VERSION ""

NS_ :

BS_:

BU_: Gen AF01A

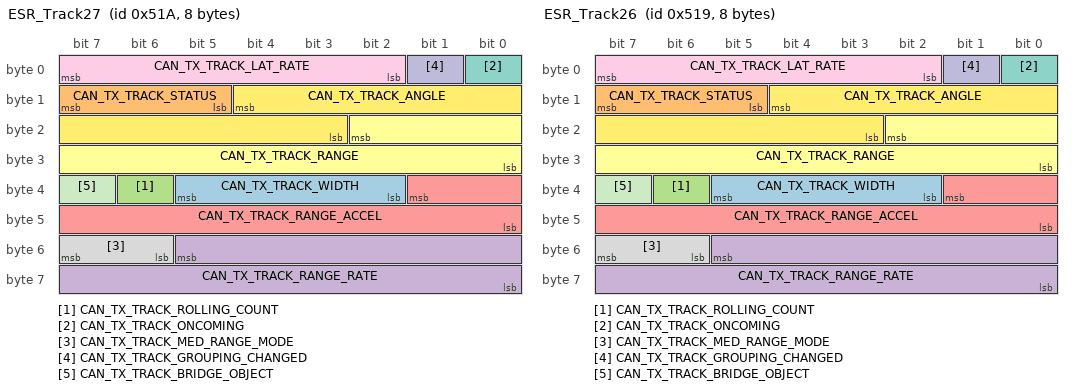
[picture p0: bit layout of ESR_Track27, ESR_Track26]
BO_ 1306 ESR_Track27: 8 Vector__XXX
 SG_ CAN_TX_TRACK_WIDTH : 37|4@0- (0.5,0) [0|7.5] "m"  AF01A
 SG_ CAN_TX_TRACK_STATUS : 15|3@0+ (1,0) [0|7] ""  AF01A
 SG_ CAN_TX_TRACK_ROLLING_COUNT : 38|1@0+ (1,0) [0|1] ""  AF01A
 SG_ CAN_TX_TRACK_RANGE_RATE : 53|14@0- (0.01,0) [-81.91|81.91] "m/s"  AF01A
 SG_ CAN_TX_TRACK_RANGE_ACCEL : 33|10@0- (0.05,0) [-25.6|25.55] "m/s/s"  AF01A
 SG_ CAN_TX_TRACK_RANGE : 18|11@0+ (0.1,0) [0|204.7] "m"  AF01A
 SG_ CAN_TX_TRACK_ONCOMING : 0|1@0+ (1,0) [0|0] ""  AF01A
 SG_ CAN_TX_TRACK_MED_RANGE_MODE : 55|2@0+ (1,0) [0|3] ""  AF01A
 SG_ CAN_TX_TRACK_LAT_RATE : 7|6@0- (0.25,0) [-8|7.75] ""  AF01A
 SG_ CAN_TX_TRACK_GROUPING_CHANGED : 1|1@0+ (1,0) [0|0] ""  AF01A
 SG_ CAN_TX_TRACK_BRIDGE_OBJECT : 39|1@0+ (1,0) [0|0] ""  AF01A
 SG_ CAN_TX_TRACK_ANGLE : 12|10@0- (0.1,0) [-51.2|51.1] "deg"  AF01A

BO_ 1305 ESR_Track26: 8 Vector__XXX
 SG_ CAN_TX_TRACK_WIDTH : 37|4@0+ (0.5,0) [0|7.5] "m"  AF01A
 SG_ CAN_TX_TRACK_STATUS : 15|3@0+ (1,0) [0|7] ""  AF01A
 SG_ CAN_TX_TRACK_ROLLING_COUNT : 38|1@0+ (1,0) [0|1] ""  AF01A
 SG_ CAN_TX_TRACK_RANGE_RATE : 53|14@0- (0.01,0) [-81.92|81.91] "m/s"  AF01A
 SG_ CAN_TX_TRACK_RANGE_ACCEL : 33|10@0- (0.05,0) [-25.6|25.55] "m/s/s"  AF01A
 SG_ CAN_TX_TRACK_RANGE : 18|11@0+ (0.1,0) [0|204.7] "m"  AF01A
 SG_ CAN_TX_TRACK_ONCOMING : 0|1@0+ (1,0) [0|0] ""  AF01A
 SG_ CAN_TX_TRACK_MED_RANGE_MODE : 55|2@0+ (1,0) [0|3] ""  AF01A
 SG_ CAN_TX_TRACK_LAT_RATE : 7|6@0- (0.25,0) [-8|7.75] ""  AF01A
 SG_ CAN_TX_TRACK_GROUPING_CHANGED : 1|1@0+ (1,0) [0|0] ""  AF01A
 SG_ CAN_TX_TRACK_BRIDGE_OBJECT : 39|1@0+ (1,0) [0|0] ""  AF01A
 SG_ CAN_TX_TRACK_ANGLE : 12|10@0- (0.1,0) [-51.2|51.1] "deg"  AF01A

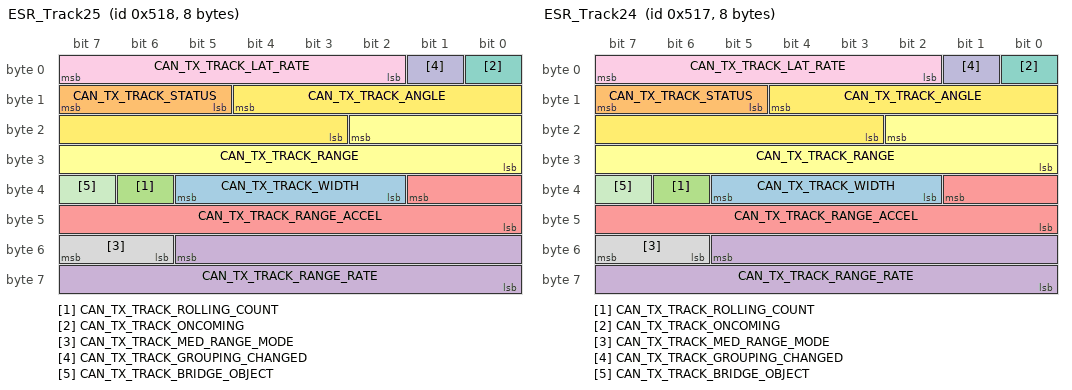
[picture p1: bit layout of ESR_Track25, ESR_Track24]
BO_ 1304 ESR_Track25: 8 Vector__XXX
 SG_ CAN_TX_TRACK_WIDTH : 37|4@0+ (0.5,0) [0|7.5] "m"  AF01A
 SG_ CAN_TX_TRACK_STATUS : 15|3@0+ (1,0) [0|7] ""  AF01A
 SG_ CAN_TX_TRACK_ROLLING_COUNT : 38|1@0+ (1,0) [0|1] ""  AF01A
 SG_ CAN_TX_TRACK_RANGE_RATE : 53|14@0- (0.01,0) [-81.92|81.91] "m/s"  AF01A
 SG_ CAN_TX_TRACK_RANGE_ACCEL : 33|10@0- (0.05,0) [-25.6|25.55] "m/s/s"  AF01A
 SG_ CAN_TX_TRACK_RANGE : 18|11@0+ (0.1,0) [0|204.7] "m"  AF01A
 SG_ CAN_TX_TRACK_ONCOMING : 0|1@0+ (1,0) [0|0] ""  AF01A
 SG_ CAN_TX_TRACK_MED_RANGE_MODE : 55|2@0+ (1,0) [0|3] ""  AF01A
 SG_ CAN_TX_TRACK_LAT_RATE : 7|6@0- (0.25,0) [-8|7.75] ""  AF01A
 SG_ CAN_TX_TRACK_GROUPING_CHANGED : 1|1@0+ (1,0) [0|0] ""  AF01A
 SG_ CAN_TX_TRACK_BRIDGE_OBJECT : 39|1@0+ (1,0) [0|0] ""  AF01A
 SG_ CAN_TX_TRACK_ANGLE : 12|10@0- (0.1,0) [-51.2|51.1] "deg"  AF01A

BO_ 1303 ESR_Track24: 8 Vector__XXX
 SG_ CAN_TX_TRACK_WIDTH : 37|4@0+ (0.5,0) [0|7.5] "m"  AF01A
 SG_ CAN_TX_TRACK_STATUS : 15|3@0+ (1,0) [0|7] ""  AF01A
 SG_ CAN_TX_TRACK_ROLLING_COUNT : 38|1@0+ (1,0) [0|1] ""  AF01A
 SG_ CAN_TX_TRACK_RANGE_RATE : 53|14@0- (0.01,0) [-81.92|81.91] "m/s"  AF01A
 SG_ CAN_TX_TRACK_RANGE_ACCEL : 33|10@0- (0.05,0) [-25.6|25.55] "m/s/s"  AF01A
 SG_ CAN_TX_TRACK_RANGE : 18|11@0+ (0.1,0) [0|204.7] "m"  AF01A
 SG_ CAN_TX_TRACK_ONCOMING : 0|1@0+ (1,0) [0|0] ""  AF01A
 SG_ CAN_TX_TRACK_MED_RANGE_MODE : 55|2@0+ (1,0) [0|3] ""  AF01A
 SG_ CAN_TX_TRACK_LAT_RATE : 7|6@0- (0.25,0) [-8|7.75] ""  AF01A
 SG_ CAN_TX_TRACK_GROUPING_CHANGED : 1|1@0+ (1,0) [0|0] ""  AF01A
 SG_ CAN_TX_TRACK_BRIDGE_OBJECT : 39|1@0+ (1,0) [0|0] ""  AF01A
 SG_ CAN_TX_TRACK_ANGLE : 12|10@0- (0.1,0) [-51.2|51.1] "deg"  AF01A

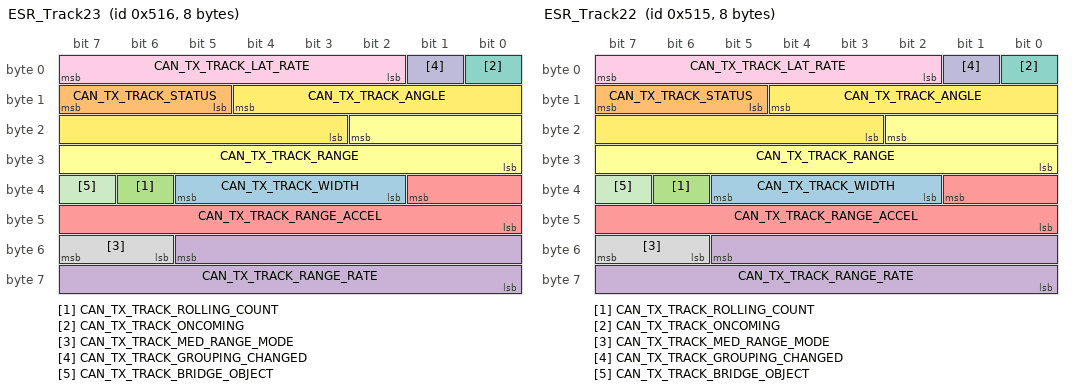
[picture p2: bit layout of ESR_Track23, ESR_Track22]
BO_ 1302 ESR_Track23: 8 Vector__XXX
 SG_ CAN_TX_TRACK_WIDTH : 37|4@0+ (0.5,0) [0|7.5] "m"  AF01A
 SG_ CAN_TX_TRACK_STATUS : 15|3@0+ (1,0) [0|7] ""  AF01A
 SG_ CAN_TX_TRACK_ROLLING_COUNT : 38|1@0+ (1,0) [0|1] ""  AF01A
 SG_ CAN_TX_TRACK_RANGE_RATE : 53|14@0- (0.01,0) [-81.92|81.91] "m/s"  AF01A
 SG_ CAN_TX_TRACK_RANGE_ACCEL : 33|10@0- (0.05,0) [-25.6|25.55] "m/s/s"  AF01A
 SG_ CAN_TX_TRACK_RANGE : 18|11@0+ (0.1,0) [0|204.7] "m"  AF01A
 SG_ CAN_TX_TRACK_ONCOMING : 0|1@0+ (1,0) [0|0] ""  AF01A
 SG_ CAN_TX_TRACK_MED_RANGE_MODE : 55|2@0+ (1,0) [0|3] ""  AF01A
 SG_ CAN_TX_TRACK_LAT_RATE : 7|6@0- (0.25,0) [-8|7.75] ""  AF01A
 SG_ CAN_TX_TRACK_GROUPING_CHANGED : 1|1@0+ (1,0) [0|0] ""  AF01A
 SG_ CAN_TX_TRACK_BRIDGE_OBJECT : 39|1@0+ (1,0) [0|0] ""  AF01A
 SG_ CAN_TX_TRACK_ANGLE : 12|10@0- (0.1,0) [-51.2|51.1] "deg"  AF01A

BO_ 1301 ESR_Track22: 8 Vector__XXX
 SG_ CAN_TX_TRACK_WIDTH : 37|4@0+ (0.5,0) [0|7.5] "m"  AF01A
 SG_ CAN_TX_TRACK_STATUS : 15|3@0+ (1,0) [0|7] ""  AF01A
 SG_ CAN_TX_TRACK_ROLLING_COUNT : 38|1@0+ (1,0) [0|1] ""  AF01A
 SG_ CAN_TX_TRACK_RANGE_RATE : 53|14@0- (0.01,0) [-81.92|81.91] "m/s"  AF01A
 SG_ CAN_TX_TRACK_RANGE_ACCEL : 33|10@0- (0.05,0) [-25.6|25.55] "m/s/s"  AF01A
 SG_ CAN_TX_TRACK_RANGE : 18|11@0+ (0.1,0) [0|204.7] "m"  AF01A
 SG_ CAN_TX_TRACK_ONCOMING : 0|1@0+ (1,0) [0|0] ""  AF01A
 SG_ CAN_TX_TRACK_MED_RANGE_MODE : 55|2@0+ (1,0) [0|3] ""  AF01A
 SG_ CAN_TX_TRACK_LAT_RATE : 7|6@0- (0.25,0) [-8|7.75] ""  AF01A
 SG_ CAN_TX_TRACK_GROUPING_CHANGED : 1|1@0+ (1,0) [0|0] ""  AF01A
 SG_ CAN_TX_TRACK_BRIDGE_OBJECT : 39|1@0+ (1,0) [0|0] ""  AF01A
 SG_ CAN_TX_TRACK_ANGLE : 12|10@0- (0.1,0) [-51.2|51.1] "deg"  AF01A

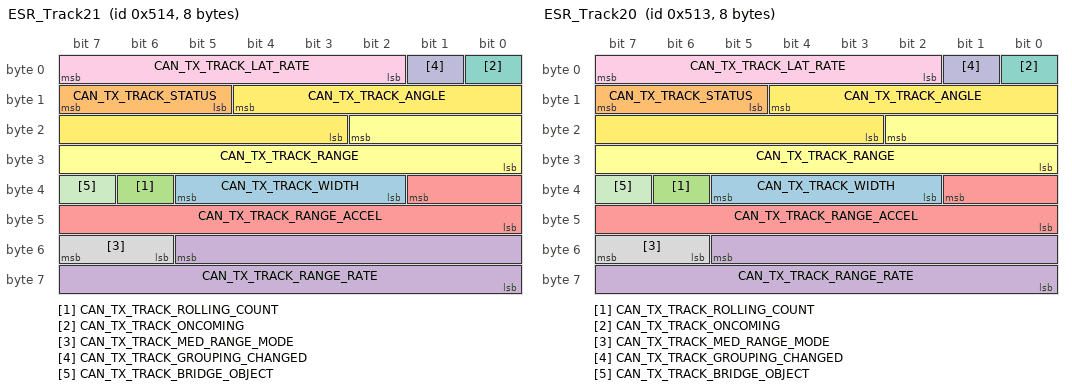
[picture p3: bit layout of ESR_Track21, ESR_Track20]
BO_ 1300 ESR_Track21: 8 Vector__XXX
 SG_ CAN_TX_TRACK_WIDTH : 37|4@0+ (0.5,0) [0|7.5] "m"  AF01A
 SG_ CAN_TX_TRACK_STATUS : 15|3@0+ (1,0) [0|7] ""  AF01A
 SG_ CAN_TX_TRACK_ROLLING_COUNT : 38|1@0+ (1,0) [0|1] ""  AF01A
 SG_ CAN_TX_TRACK_RANGE_RATE : 53|14@0- (0.01,0) [-81.92|81.91] "m/s"  AF01A
 SG_ CAN_TX_TRACK_RANGE_ACCEL : 33|10@0- (0.05,0) [-25.6|25.55] "m/s/s"  AF01A
 SG_ CAN_TX_TRACK_RANGE : 18|11@0+ (0.1,0) [0|204.7] "m"  AF01A
 SG_ CAN_TX_TRACK_ONCOMING : 0|1@0+ (1,0) [0|0] ""  AF01A
 SG_ CAN_TX_TRACK_MED_RANGE_MODE : 55|2@0+ (1,0) [0|3] ""  AF01A
 SG_ CAN_TX_TRACK_LAT_RATE : 7|6@0- (0.25,0) [-8|7.75] ""  AF01A
 SG_ CAN_TX_TRACK_GROUPING_CHANGED : 1|1@0+ (1,0) [0|0] ""  AF01A
 SG_ CAN_TX_TRACK_BRIDGE_OBJECT : 39|1@0+ (1,0) [0|0] ""  AF01A
 SG_ CAN_TX_TRACK_ANGLE : 12|10@0- (0.1,0) [-51.2|51.1] "deg"  AF01A

BO_ 1299 ESR_Track20: 8 Vector__XXX
 SG_ CAN_TX_TRACK_WIDTH : 37|4@0+ (0.5,0) [0|7.5] "m"  AF01A
 SG_ CAN_TX_TRACK_STATUS : 15|3@0+ (1,0) [0|7] ""  AF01A
 SG_ CAN_TX_TRACK_ROLLING_COUNT : 38|1@0+ (1,0) [0|1] ""  AF01A
 SG_ CAN_TX_TRACK_RANGE_RATE : 53|14@0- (0.01,0) [-81.92|81.91] "m/s"  AF01A
 SG_ CAN_TX_TRACK_RANGE_ACCEL : 33|10@0- (0.05,0) [-25.6|25.55] "m/s/s"  AF01A
 SG_ CAN_TX_TRACK_RANGE : 18|11@0+ (0.1,0) [0|204.7] "m"  AF01A
 SG_ CAN_TX_TRACK_ONCOMING : 0|1@0+ (1,0) [0|0] ""  AF01A
 SG_ CAN_TX_TRACK_MED_RANGE_MODE : 55|2@0+ (1,0) [0|3] ""  AF01A
 SG_ CAN_TX_TRACK_LAT_RATE : 7|6@0- (0.25,0) [-8|7.75] ""  AF01A
 SG_ CAN_TX_TRACK_GROUPING_CHANGED : 1|1@0+ (1,0) [0|0] ""  AF01A
 SG_ CAN_TX_TRACK_BRIDGE_OBJECT : 39|1@0+ (1,0) [0|0] ""  AF01A
 SG_ CAN_TX_TRACK_ANGLE : 12|10@0- (0.1,0) [-51.2|51.1] "deg"  AF01A

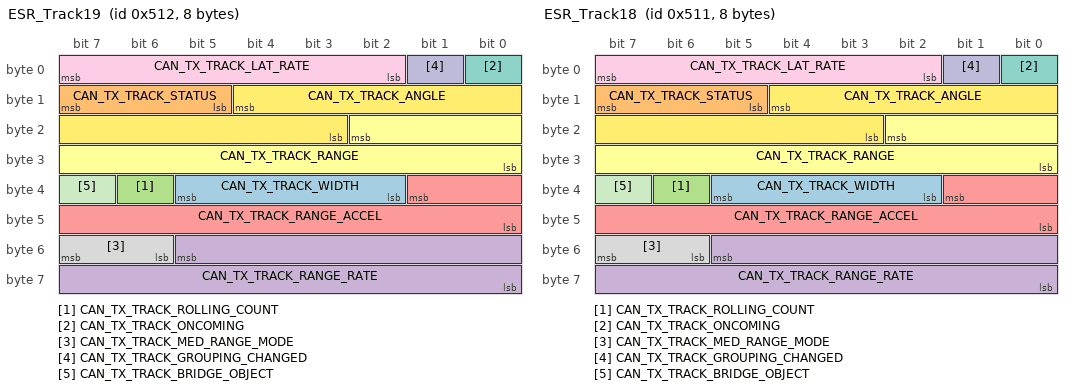
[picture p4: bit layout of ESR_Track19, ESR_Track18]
BO_ 1298 ESR_Track19: 8 Vector__XXX
 SG_ CAN_TX_TRACK_WIDTH : 37|4@0+ (0.5,0) [0|7.5] "m"  AF01A
 SG_ CAN_TX_TRACK_STATUS : 15|3@0+ (1,0) [0|7] ""  AF01A
 SG_ CAN_TX_TRACK_ROLLING_COUNT : 38|1@0+ (1,0) [0|1] ""  AF01A
 SG_ CAN_TX_TRACK_RANGE_RATE : 53|14@0- (0.01,0) [-81.92|81.91] "m/s"  AF01A
 SG_ CAN_TX_TRACK_RANGE_ACCEL : 33|10@0- (0.05,0) [-25.6|25.55] "m/s/s"  AF01A
 SG_ CAN_TX_TRACK_RANGE : 18|11@0+ (0.1,0) [0|204.7] "m"  AF01A
 SG_ CAN_TX_TRACK_ONCOMING : 0|1@0+ (1,0) [0|0] ""  AF01A
 SG_ CAN_TX_TRACK_MED_RANGE_MODE : 55|2@0+ (1,0) [0|3] ""  AF01A
 SG_ CAN_TX_TRACK_LAT_RATE : 7|6@0- (0.25,0) [-8|7.75] ""  AF01A
 SG_ CAN_TX_TRACK_GROUPING_CHANGED : 1|1@0+ (1,0) [0|0] ""  AF01A
 SG_ CAN_TX_TRACK_BRIDGE_OBJECT : 39|1@0+ (1,0) [0|0] ""  AF01A
 SG_ CAN_TX_TRACK_ANGLE : 12|10@0- (0.1,0) [-51.2|51.1] "deg"  AF01A

BO_ 1297 ESR_Track18: 8 Vector__XXX
 SG_ CAN_TX_TRACK_WIDTH : 37|4@0+ (0.5,0) [0|7.5] "m"  AF01A
 SG_ CAN_TX_TRACK_STATUS : 15|3@0+ (1,0) [0|7] ""  AF01A
 SG_ CAN_TX_TRACK_ROLLING_COUNT : 38|1@0+ (1,0) [0|1] ""  AF01A
 SG_ CAN_TX_TRACK_RANGE_RATE : 53|14@0- (0.01,0) [-81.92|81.91] "m/s"  AF01A
 SG_ CAN_TX_TRACK_RANGE_ACCEL : 33|10@0- (0.05,0) [-25.6|25.55] "m/s/s"  AF01A
 SG_ CAN_TX_TRACK_RANGE : 18|11@0+ (0.1,0) [0|204.7] "m"  AF01A
 SG_ CAN_TX_TRACK_ONCOMING : 0|1@0+ (1,0) [0|0] ""  AF01A
 SG_ CAN_TX_TRACK_MED_RANGE_MODE : 55|2@0+ (1,0) [0|3] ""  AF01A
 SG_ CAN_TX_TRACK_LAT_RATE : 7|6@0- (0.25,0) [-8|7.75] ""  AF01A
 SG_ CAN_TX_TRACK_GROUPING_CHANGED : 1|1@0+ (1,0) [0|0] ""  AF01A
 SG_ CAN_TX_TRACK_BRIDGE_OBJECT : 39|1@0+ (1,0) [0|0] ""  AF01A
 SG_ CAN_TX_TRACK_ANGLE : 12|10@0- (0.1,0) [-51.2|51.1] "deg"  AF01A

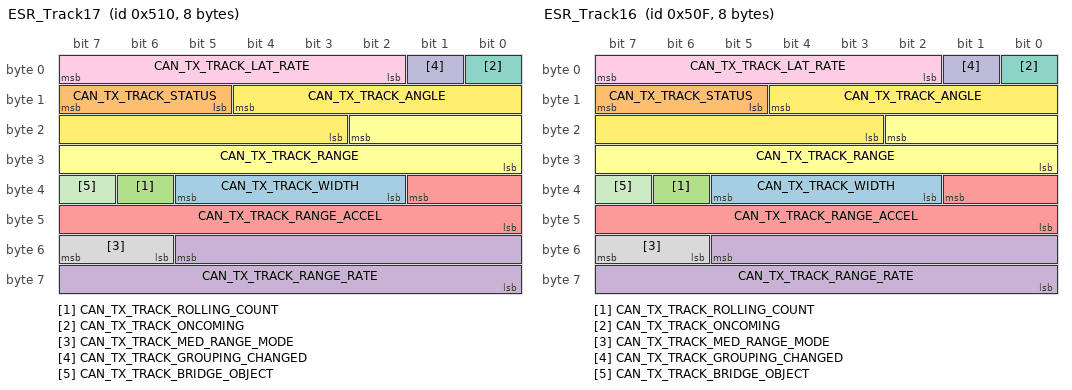
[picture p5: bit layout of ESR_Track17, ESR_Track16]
BO_ 1296 ESR_Track17: 8 Vector__XXX
 SG_ CAN_TX_TRACK_WIDTH : 37|4@0+ (0.5,0) [0|7.5] "m"  AF01A
 SG_ CAN_TX_TRACK_STATUS : 15|3@0+ (1,0) [0|7] ""  AF01A
 SG_ CAN_TX_TRACK_ROLLING_COUNT : 38|1@0+ (1,0) [0|1] ""  AF01A
 SG_ CAN_TX_TRACK_RANGE_RATE : 53|14@0- (0.01,0) [-81.92|81.91] "m/s"  AF01A
 SG_ CAN_TX_TRACK_RANGE_ACCEL : 33|10@0- (0.05,0) [-25.6|25.55] "m/s/s"  AF01A
 SG_ CAN_TX_TRACK_RANGE : 18|11@0+ (0.1,0) [0|204.7] "m"  AF01A
 SG_ CAN_TX_TRACK_ONCOMING : 0|1@0+ (1,0) [0|0] ""  AF01A
 SG_ CAN_TX_TRACK_MED_RANGE_MODE : 55|2@0+ (1,0) [0|3] ""  AF01A
 SG_ CAN_TX_TRACK_LAT_RATE : 7|6@0- (0.25,0) [-8|7.75] ""  AF01A
 SG_ CAN_TX_TRACK_GROUPING_CHANGED : 1|1@0+ (1,0) [0|0] ""  AF01A
 SG_ CAN_TX_TRACK_BRIDGE_OBJECT : 39|1@0+ (1,0) [0|0] ""  AF01A
 SG_ CAN_TX_TRACK_ANGLE : 12|10@0- (0.1,0) [-51.2|51.1] "deg"  AF01A

BO_ 1295 ESR_Track16: 8 Vector__XXX
 SG_ CAN_TX_TRACK_WIDTH : 37|4@0+ (0.5,0) [0|7.5] "m"  AF01A
 SG_ CAN_TX_TRACK_STATUS : 15|3@0+ (1,0) [0|7] ""  AF01A
 SG_ CAN_TX_TRACK_ROLLING_COUNT : 38|1@0+ (1,0) [0|1] ""  AF01A
 SG_ CAN_TX_TRACK_RANGE_RATE : 53|14@0- (0.01,0) [-81.92|81.91] "m/s"  AF01A
 SG_ CAN_TX_TRACK_RANGE_ACCEL : 33|10@0- (0.05,0) [-25.6|25.55] "m/s/s"  AF01A
 SG_ CAN_TX_TRACK_RANGE : 18|11@0+ (0.1,0) [0|204.7] "m"  AF01A
 SG_ CAN_TX_TRACK_ONCOMING : 0|1@0+ (1,0) [0|0] ""  AF01A
 SG_ CAN_TX_TRACK_MED_RANGE_MODE : 55|2@0+ (1,0) [0|3] ""  AF01A
 SG_ CAN_TX_TRACK_LAT_RATE : 7|6@0- (0.25,0) [-8|7.75] ""  AF01A
 SG_ CAN_TX_TRACK_GROUPING_CHANGED : 1|1@0+ (1,0) [0|0] ""  AF01A
 SG_ CAN_TX_TRACK_BRIDGE_OBJECT : 39|1@0+ (1,0) [0|0] ""  AF01A
 SG_ CAN_TX_TRACK_ANGLE : 12|10@0- (0.1,0) [-51.2|51.1] "deg"  AF01A

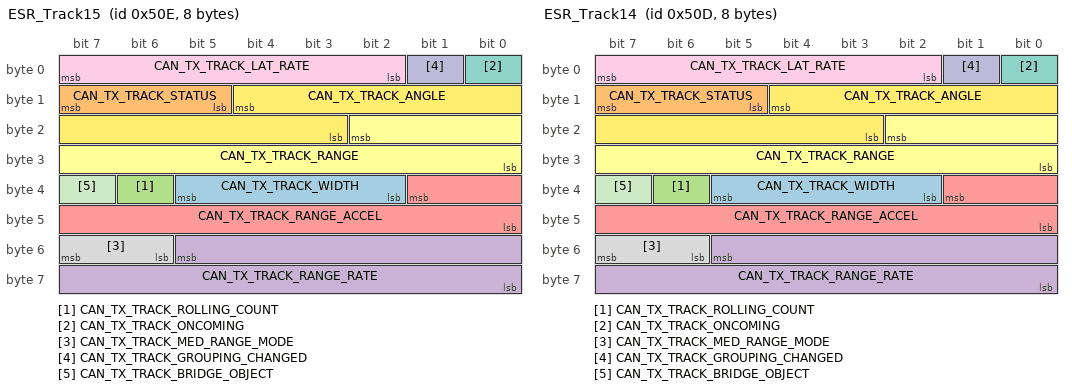
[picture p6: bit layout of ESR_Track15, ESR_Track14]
BO_ 1294 ESR_Track15: 8 Vector__XXX
 SG_ CAN_TX_TRACK_WIDTH : 37|4@0+ (0.5,0) [0|7.5] "m"  AF01A
 SG_ CAN_TX_TRACK_STATUS : 15|3@0+ (1,0) [0|7] ""  AF01A
 SG_ CAN_TX_TRACK_ROLLING_COUNT : 38|1@0+ (1,0) [0|1] ""  AF01A
 SG_ CAN_TX_TRACK_RANGE_RATE : 53|14@0- (0.01,0) [-81.92|81.91] "m/s"  AF01A
 SG_ CAN_TX_TRACK_RANGE_ACCEL : 33|10@0- (0.05,0) [-25.6|25.55] "m/s/s"  AF01A
 SG_ CAN_TX_TRACK_RANGE : 18|11@0+ (0.1,0) [0|204.7] "m"  AF01A
 SG_ CAN_TX_TRACK_ONCOMING : 0|1@0+ (1,0) [0|0] ""  AF01A
 SG_ CAN_TX_TRACK_MED_RANGE_MODE : 55|2@0+ (1,0) [0|3] ""  AF01A
 SG_ CAN_TX_TRACK_LAT_RATE : 7|6@0- (0.25,0) [-8|7.75] ""  AF01A
 SG_ CAN_TX_TRACK_GROUPING_CHANGED : 1|1@0+ (1,0) [0|0] ""  AF01A
 SG_ CAN_TX_TRACK_BRIDGE_OBJECT : 39|1@0+ (1,0) [0|0] ""  AF01A
 SG_ CAN_TX_TRACK_ANGLE : 12|10@0- (0.1,0) [-51.2|51.1] "deg"  AF01A

BO_ 1293 ESR_Track14: 8 Vector__XXX
 SG_ CAN_TX_TRACK_WIDTH : 37|4@0+ (0.5,0) [0|7.5] "m"  AF01A
 SG_ CAN_TX_TRACK_STATUS : 15|3@0+ (1,0) [0|7] ""  AF01A
 SG_ CAN_TX_TRACK_ROLLING_COUNT : 38|1@0+ (1,0) [0|1] ""  AF01A
 SG_ CAN_TX_TRACK_RANGE_RATE : 53|14@0- (0.01,0) [-81.92|81.91] "m/s"  AF01A
 SG_ CAN_TX_TRACK_RANGE_ACCEL : 33|10@0- (0.05,0) [-25.6|25.55] "m/s/s"  AF01A
 SG_ CAN_TX_TRACK_RANGE : 18|11@0+ (0.1,0) [0|204.7] "m"  AF01A
 SG_ CAN_TX_TRACK_ONCOMING : 0|1@0+ (1,0) [0|0] ""  AF01A
 SG_ CAN_TX_TRACK_MED_RANGE_MODE : 55|2@0+ (1,0) [0|3] ""  AF01A
 SG_ CAN_TX_TRACK_LAT_RATE : 7|6@0- (0.25,0) [-8|7.75] ""  AF01A
 SG_ CAN_TX_TRACK_GROUPING_CHANGED : 1|1@0+ (1,0) [0|0] ""  AF01A
 SG_ CAN_TX_TRACK_BRIDGE_OBJECT : 39|1@0+ (1,0) [0|0] ""  AF01A
 SG_ CAN_TX_TRACK_ANGLE : 12|10@0- (0.1,0) [-51.2|51.1] "deg"  AF01A

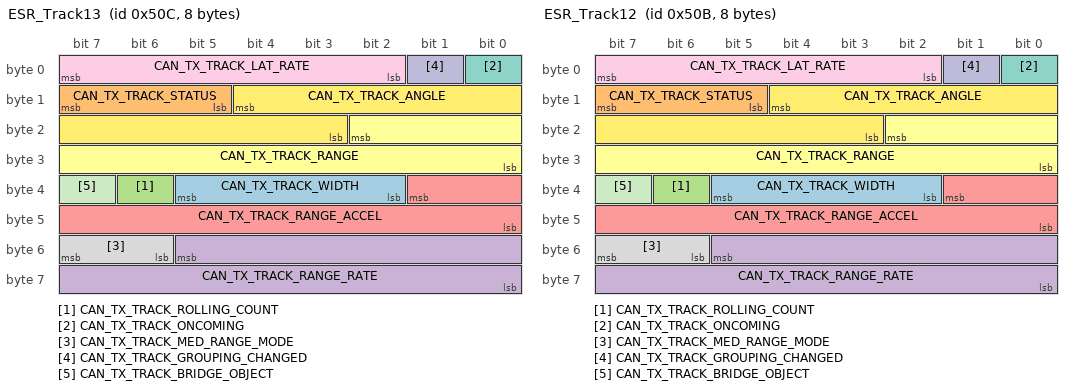
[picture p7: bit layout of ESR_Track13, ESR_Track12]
BO_ 1292 ESR_Track13: 8 Vector__XXX
 SG_ CAN_TX_TRACK_WIDTH : 37|4@0+ (0.5,0) [0|7.5] "m"  AF01A
 SG_ CAN_TX_TRACK_STATUS : 15|3@0+ (1,0) [0|7] ""  AF01A
 SG_ CAN_TX_TRACK_ROLLING_COUNT : 38|1@0+ (1,0) [0|1] ""  AF01A
 SG_ CAN_TX_TRACK_RANGE_RATE : 53|14@0- (0.01,0) [-81.92|81.91] "m/s"  AF01A
 SG_ CAN_TX_TRACK_RANGE_ACCEL : 33|10@0- (0.05,0) [-25.6|25.55] "m/s/s"  AF01A
 SG_ CAN_TX_TRACK_RANGE : 18|11@0+ (0.1,0) [0|204.7] "m"  AF01A
 SG_ CAN_TX_TRACK_ONCOMING : 0|1@0+ (1,0) [0|0] ""  AF01A
 SG_ CAN_TX_TRACK_MED_RANGE_MODE : 55|2@0+ (1,0) [0|3] ""  AF01A
 SG_ CAN_TX_TRACK_LAT_RATE : 7|6@0- (0.25,0) [-8|7.75] ""  AF01A
 SG_ CAN_TX_TRACK_GROUPING_CHANGED : 1|1@0+ (1,0) [0|0] ""  AF01A
 SG_ CAN_TX_TRACK_BRIDGE_OBJECT : 39|1@0+ (1,0) [0|0] ""  AF01A
 SG_ CAN_TX_TRACK_ANGLE : 12|10@0- (0.1,0) [-51.2|51.1] "deg"  AF01A

BO_ 1291 ESR_Track12: 8 Vector__XXX
 SG_ CAN_TX_TRACK_WIDTH : 37|4@0+ (0.5,0) [0|7.5] "m"  AF01A
 SG_ CAN_TX_TRACK_STATUS : 15|3@0+ (1,0) [0|7] ""  AF01A
 SG_ CAN_TX_TRACK_ROLLING_COUNT : 38|1@0+ (1,0) [0|1] ""  AF01A
 SG_ CAN_TX_TRACK_RANGE_RATE : 53|14@0- (0.01,0) [-81.92|81.91] "m/s"  AF01A
 SG_ CAN_TX_TRACK_RANGE_ACCEL : 33|10@0- (0.05,0) [-25.6|25.55] "m/s/s"  AF01A
 SG_ CAN_TX_TRACK_RANGE : 18|11@0+ (0.1,0) [0|204.7] "m"  AF01A
 SG_ CAN_TX_TRACK_ONCOMING : 0|1@0+ (1,0) [0|0] ""  AF01A
 SG_ CAN_TX_TRACK_MED_RANGE_MODE : 55|2@0+ (1,0) [0|3] ""  AF01A
 SG_ CAN_TX_TRACK_LAT_RATE : 7|6@0- (0.25,0) [-8|7.75] ""  AF01A
 SG_ CAN_TX_TRACK_GROUPING_CHANGED : 1|1@0+ (1,0) [0|0] ""  AF01A
 SG_ CAN_TX_TRACK_BRIDGE_OBJECT : 39|1@0+ (1,0) [0|0] ""  AF01A
 SG_ CAN_TX_TRACK_ANGLE : 12|10@0- (0.1,0) [-51.2|51.1] "deg"  AF01A

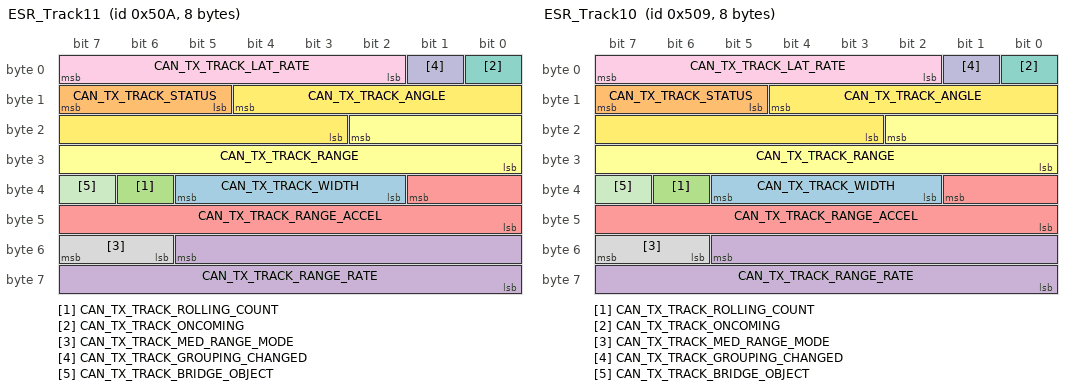
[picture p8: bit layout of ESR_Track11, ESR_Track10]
BO_ 1290 ESR_Track11: 8 Vector__XXX
 SG_ CAN_TX_TRACK_WIDTH : 37|4@0+ (0.5,0) [0|7.5] "m"  AF01A
 SG_ CAN_TX_TRACK_STATUS : 15|3@0+ (1,0) [0|7] ""  AF01A
 SG_ CAN_TX_TRACK_ROLLING_COUNT : 38|1@0+ (1,0) [0|1] ""  AF01A
 SG_ CAN_TX_TRACK_RANGE_RATE : 53|14@0- (0.01,0) [-81.92|81.91] "m/s"  AF01A
 SG_ CAN_TX_TRACK_RANGE_ACCEL : 33|10@0- (0.05,0) [-25.6|25.55] "m/s/s"  AF01A
 SG_ CAN_TX_TRACK_RANGE : 18|11@0+ (0.1,0) [0|204.7] "m"  AF01A
 SG_ CAN_TX_TRACK_ONCOMING : 0|1@0+ (1,0) [0|0] ""  AF01A
 SG_ CAN_TX_TRACK_MED_RANGE_MODE : 55|2@0+ (1,0) [0|3] ""  AF01A
 SG_ CAN_TX_TRACK_LAT_RATE : 7|6@0- (0.25,0) [-8|7.75] ""  AF01A
 SG_ CAN_TX_TRACK_GROUPING_CHANGED : 1|1@0+ (1,0) [0|0] ""  AF01A
 SG_ CAN_TX_TRACK_BRIDGE_OBJECT : 39|1@0+ (1,0) [0|0] ""  AF01A
 SG_ CAN_TX_TRACK_ANGLE : 12|10@0- (0.1,0) [-51.2|51.1] "deg"  AF01A

BO_ 1289 ESR_Track10: 8 Vector__XXX
 SG_ CAN_TX_TRACK_WIDTH : 37|4@0+ (0.5,0) [0|7.5] "m"  AF01A
 SG_ CAN_TX_TRACK_STATUS : 15|3@0+ (1,0) [0|7] ""  AF01A
 SG_ CAN_TX_TRACK_ROLLING_COUNT : 38|1@0+ (1,0) [0|1] ""  AF01A
 SG_ CAN_TX_TRACK_RANGE_RATE : 53|14@0- (0.01,0) [-81.92|81.91] "m/s"  AF01A
 SG_ CAN_TX_TRACK_RANGE_ACCEL : 33|10@0- (0.05,0) [-25.6|25.55] "m/s/s"  AF01A
 SG_ CAN_TX_TRACK_RANGE : 18|11@0+ (0.1,0) [0|204.7] "m"  AF01A
 SG_ CAN_TX_TRACK_ONCOMING : 0|1@0+ (1,0) [0|0] ""  AF01A
 SG_ CAN_TX_TRACK_MED_RANGE_MODE : 55|2@0+ (1,0) [0|3] ""  AF01A
 SG_ CAN_TX_TRACK_LAT_RATE : 7|6@0- (0.25,0) [-8|7.75] ""  AF01A
 SG_ CAN_TX_TRACK_GROUPING_CHANGED : 1|1@0+ (1,0) [0|0] ""  AF01A
 SG_ CAN_TX_TRACK_BRIDGE_OBJECT : 39|1@0+ (1,0) [0|0] ""  AF01A
 SG_ CAN_TX_TRACK_ANGLE : 12|10@0- (0.1,0) [-51.2|51.1] "deg"  AF01A

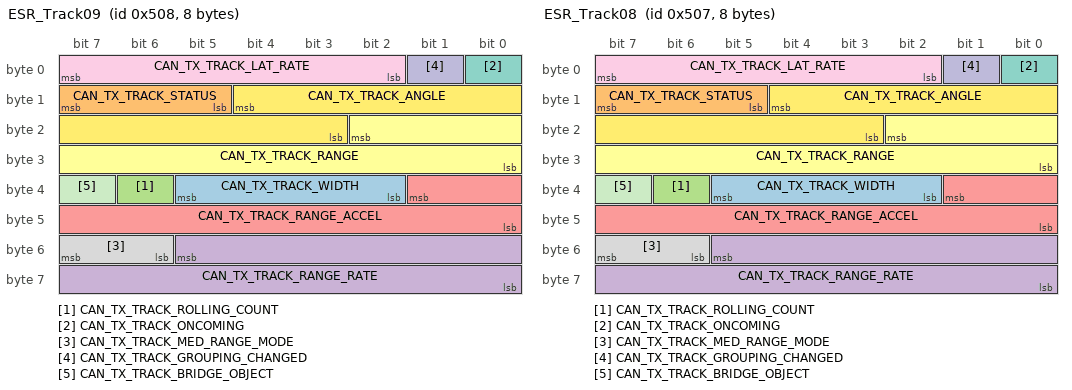
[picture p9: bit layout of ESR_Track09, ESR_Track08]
BO_ 1288 ESR_Track09: 8 Vector__XXX
 SG_ CAN_TX_TRACK_WIDTH : 37|4@0+ (0.5,0) [0|7.5] "m"  AF01A
 SG_ CAN_TX_TRACK_STATUS : 15|3@0+ (1,0) [0|7] ""  AF01A
 SG_ CAN_TX_TRACK_ROLLING_COUNT : 38|1@0+ (1,0) [0|1] ""  AF01A
 SG_ CAN_TX_TRACK_RANGE_RATE : 53|14@0- (0.01,0) [-81.92|81.91] "m/s"  AF01A
 SG_ CAN_TX_TRACK_RANGE_ACCEL : 33|10@0- (0.05,0) [-25.6|25.55] "m/s/s"  AF01A
 SG_ CAN_TX_TRACK_RANGE : 18|11@0+ (0.1,0) [0|204.7] "m"  AF01A
 SG_ CAN_TX_TRACK_ONCOMING : 0|1@0+ (1,0) [0|0] ""  AF01A
 SG_ CAN_TX_TRACK_MED_RANGE_MODE : 55|2@0+ (1,0) [0|3] ""  AF01A
 SG_ CAN_TX_TRACK_LAT_RATE : 7|6@0- (0.25,0) [-8|7.75] ""  AF01A
 SG_ CAN_TX_TRACK_GROUPING_CHANGED : 1|1@0+ (1,0) [0|0] ""  AF01A
 SG_ CAN_TX_TRACK_BRIDGE_OBJECT : 39|1@0+ (1,0) [0|0] ""  AF01A
 SG_ CAN_TX_TRACK_ANGLE : 12|10@0- (0.1,0) [-51.2|51.1] "deg"  AF01A

BO_ 1287 ESR_Track08: 8 Vector__XXX
 SG_ CAN_TX_TRACK_WIDTH : 37|4@0+ (0.5,0) [0|7.5] "m"  AF01A
 SG_ CAN_TX_TRACK_STATUS : 15|3@0+ (1,0) [0|7] ""  AF01A
 SG_ CAN_TX_TRACK_ROLLING_COUNT : 38|1@0+ (1,0) [0|1] ""  AF01A
 SG_ CAN_TX_TRACK_RANGE_RATE : 53|14@0- (0.01,0) [-81.92|81.91] "m/s"  AF01A
 SG_ CAN_TX_TRACK_RANGE_ACCEL : 33|10@0- (0.05,0) [-25.6|25.55] "m/s/s"  AF01A
 SG_ CAN_TX_TRACK_RANGE : 18|11@0+ (0.1,0) [0|204.7] "m"  AF01A
 SG_ CAN_TX_TRACK_ONCOMING : 0|1@0+ (1,0) [0|0] ""  AF01A
 SG_ CAN_TX_TRACK_MED_RANGE_MODE : 55|2@0+ (1,0) [0|3] ""  AF01A
 SG_ CAN_TX_TRACK_LAT_RATE : 7|6@0- (0.25,0) [-8|7.75] ""  AF01A
 SG_ CAN_TX_TRACK_GROUPING_CHANGED : 1|1@0+ (1,0) [0|0] ""  AF01A
 SG_ CAN_TX_TRACK_BRIDGE_OBJECT : 39|1@0+ (1,0) [0|0] ""  AF01A
 SG_ CAN_TX_TRACK_ANGLE : 12|10@0- (0.1,0) [-51.2|51.1] "deg"  AF01A

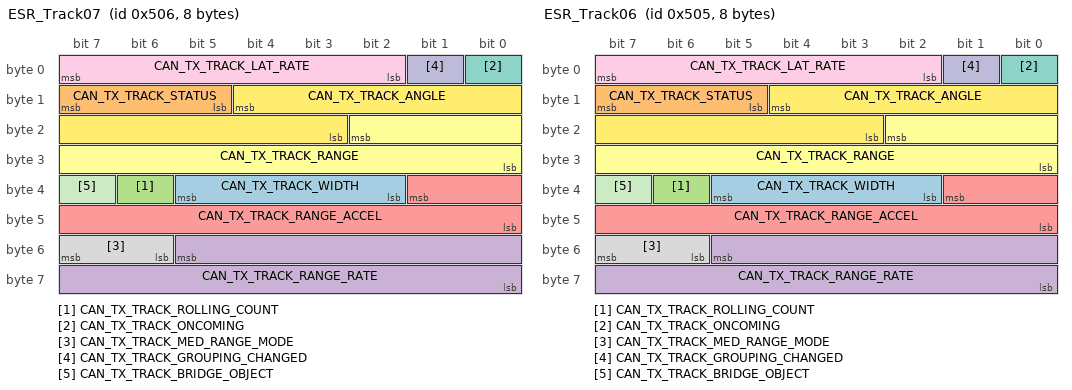
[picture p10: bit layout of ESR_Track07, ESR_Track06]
BO_ 1286 ESR_Track07: 8 Vector__XXX
 SG_ CAN_TX_TRACK_WIDTH : 37|4@0+ (0.5,0) [0|7.5] "m"  AF01A
 SG_ CAN_TX_TRACK_STATUS : 15|3@0+ (1,0) [0|7] ""  AF01A
 SG_ CAN_TX_TRACK_ROLLING_COUNT : 38|1@0+ (1,0) [0|1] ""  AF01A
 SG_ CAN_TX_TRACK_RANGE_RATE : 53|14@0- (0.01,0) [-81.92|81.91] "m/s"  AF01A
 SG_ CAN_TX_TRACK_RANGE_ACCEL : 33|10@0- (0.05,0) [-25.6|25.55] "m/s/s"  AF01A
 SG_ CAN_TX_TRACK_RANGE : 18|11@0+ (0.1,0) [0|204.7] "m"  AF01A
 SG_ CAN_TX_TRACK_ONCOMING : 0|1@0+ (1,0) [0|0] ""  AF01A
 SG_ CAN_TX_TRACK_MED_RANGE_MODE : 55|2@0+ (1,0) [0|3] ""  AF01A
 SG_ CAN_TX_TRACK_LAT_RATE : 7|6@0- (0.25,0) [-8|7.75] ""  AF01A
 SG_ CAN_TX_TRACK_GROUPING_CHANGED : 1|1@0+ (1,0) [0|0] ""  AF01A
 SG_ CAN_TX_TRACK_BRIDGE_OBJECT : 39|1@0+ (1,0) [0|0] ""  AF01A
 SG_ CAN_TX_TRACK_ANGLE : 12|10@0- (0.1,0) [-51.2|51.1] "deg"  AF01A

BO_ 1285 ESR_Track06: 8 Vector__XXX
 SG_ CAN_TX_TRACK_WIDTH : 37|4@0+ (0.5,0) [0|7.5] "m"  AF01A
 SG_ CAN_TX_TRACK_STATUS : 15|3@0+ (1,0) [0|7] ""  AF01A
 SG_ CAN_TX_TRACK_ROLLING_COUNT : 38|1@0+ (1,0) [0|1] ""  AF01A
 SG_ CAN_TX_TRACK_RANGE_RATE : 53|14@0- (0.01,0) [-81.92|81.91] "m/s"  AF01A
 SG_ CAN_TX_TRACK_RANGE_ACCEL : 33|10@0- (0.05,0) [-25.6|25.55] "m/s/s"  AF01A
 SG_ CAN_TX_TRACK_RANGE : 18|11@0+ (0.1,0) [0|204.7] "m"  AF01A
 SG_ CAN_TX_TRACK_ONCOMING : 0|1@0+ (1,0) [0|0] ""  AF01A
 SG_ CAN_TX_TRACK_MED_RANGE_MODE : 55|2@0+ (1,0) [0|3] ""  AF01A
 SG_ CAN_TX_TRACK_LAT_RATE : 7|6@0- (0.25,0) [-8|7.75] ""  AF01A
 SG_ CAN_TX_TRACK_GROUPING_CHANGED : 1|1@0+ (1,0) [0|0] ""  AF01A
 SG_ CAN_TX_TRACK_BRIDGE_OBJECT : 39|1@0+ (1,0) [0|0] ""  AF01A
 SG_ CAN_TX_TRACK_ANGLE : 12|10@0- (0.1,0) [-51.2|51.1] "deg"  AF01A

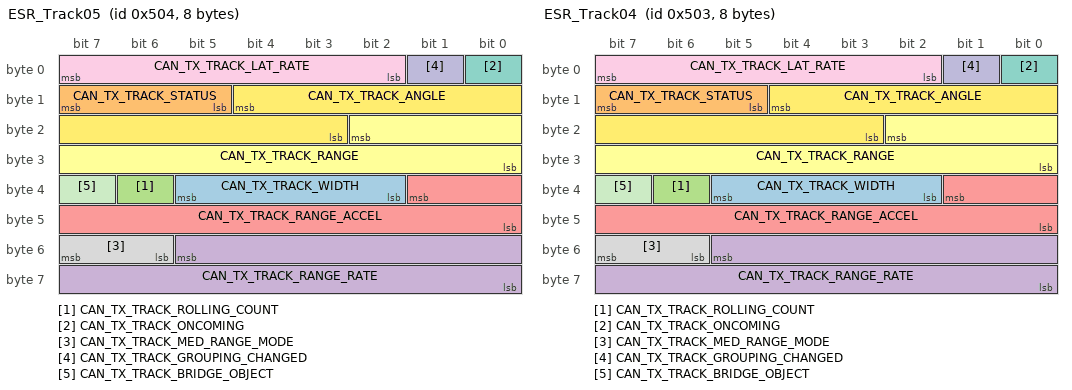
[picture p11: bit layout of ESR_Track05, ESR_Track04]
BO_ 1284 ESR_Track05: 8 Vector__XXX
 SG_ CAN_TX_TRACK_WIDTH : 37|4@0+ (0.5,0) [0|7.5] "m"  AF01A
 SG_ CAN_TX_TRACK_STATUS : 15|3@0+ (1,0) [0|7] ""  AF01A
 SG_ CAN_TX_TRACK_ROLLING_COUNT : 38|1@0+ (1,0) [0|1] ""  AF01A
 SG_ CAN_TX_TRACK_RANGE_RATE : 53|14@0- (0.01,0) [-81.92|81.91] "m/s"  AF01A
 SG_ CAN_TX_TRACK_RANGE_ACCEL : 33|10@0- (0.05,0) [-25.6|25.55] "m/s/s"  AF01A
 SG_ CAN_TX_TRACK_RANGE : 18|11@0+ (0.1,0) [0|204.7] "m"  AF01A
 SG_ CAN_TX_TRACK_ONCOMING : 0|1@0+ (1,0) [0|0] ""  AF01A
 SG_ CAN_TX_TRACK_MED_RANGE_MODE : 55|2@0+ (1,0) [0|3] ""  AF01A
 SG_ CAN_TX_TRACK_LAT_RATE : 7|6@0- (0.25,0) [-8|7.75] ""  AF01A
 SG_ CAN_TX_TRACK_GROUPING_CHANGED : 1|1@0+ (1,0) [0|0] ""  AF01A
 SG_ CAN_TX_TRACK_BRIDGE_OBJECT : 39|1@0+ (1,0) [0|0] ""  AF01A
 SG_ CAN_TX_TRACK_ANGLE : 12|10@0- (0.1,0) [-51.2|51.1] "deg"  AF01A

BO_ 1283 ESR_Track04: 8 Vector__XXX
 SG_ CAN_TX_TRACK_WIDTH : 37|4@0+ (0.5,0) [0|0] "m"  AF01A
 SG_ CAN_TX_TRACK_STATUS : 15|3@0+ (1,0) [0|7] ""  AF01A
 SG_ CAN_TX_TRACK_ROLLING_COUNT : 38|1@0+ (1,0) [0|1] ""  AF01A
 SG_ CAN_TX_TRACK_RANGE_RATE : 53|14@0- (0.01,0) [-81.92|81.91] "m/s"  AF01A
 SG_ CAN_TX_TRACK_RANGE_ACCEL : 33|10@0- (0.05,0) [-25.6|25.55] "m/s/s"  AF01A
 SG_ CAN_TX_TRACK_RANGE : 18|11@0+ (0.1,0) [0|204.7] "m"  AF01A
 SG_ CAN_TX_TRACK_ONCOMING : 0|1@0+ (1,0) [0|0] ""  AF01A
 SG_ CAN_TX_TRACK_MED_RANGE_MODE : 55|2@0+ (1,0) [0|3] ""  AF01A
 SG_ CAN_TX_TRACK_LAT_RATE : 7|6@0- (0.25,0) [-8|7.75] ""  AF01A
 SG_ CAN_TX_TRACK_GROUPING_CHANGED : 1|1@0+ (1,0) [0|0] ""  AF01A
 SG_ CAN_TX_TRACK_BRIDGE_OBJECT : 39|1@0+ (1,0) [0|0] ""  AF01A
 SG_ CAN_TX_TRACK_ANGLE : 12|10@0- (0.1,0) [-51.2|51.1] "deg"  AF01A

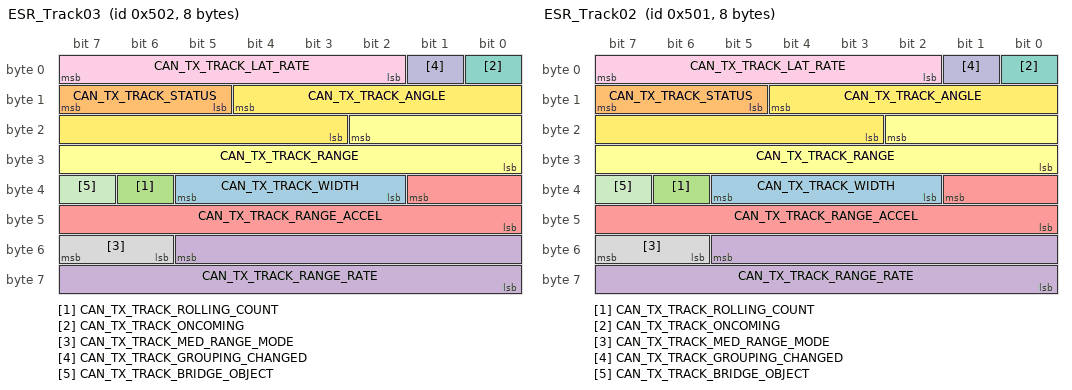
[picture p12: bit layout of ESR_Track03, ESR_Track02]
BO_ 1282 ESR_Track03: 8 Vector__XXX
 SG_ CAN_TX_TRACK_WIDTH : 37|4@0+ (0.5,0) [0|7.5] "m"  AF01A
 SG_ CAN_TX_TRACK_STATUS : 15|3@0+ (1,0) [0|7] ""  AF01A
 SG_ CAN_TX_TRACK_ROLLING_COUNT : 38|1@0+ (1,0) [0|1] ""  AF01A
 SG_ CAN_TX_TRACK_RANGE_RATE : 53|14@0- (0.01,0) [-81.92|81.91] "m/s"  AF01A
 SG_ CAN_TX_TRACK_RANGE_ACCEL : 33|10@0- (0.05,0) [-25.6|25.55] "m/s/s"  AF01A
 SG_ CAN_TX_TRACK_RANGE : 18|11@0+ (0.1,0) [0|204.7] "m"  AF01A
 SG_ CAN_TX_TRACK_ONCOMING : 0|1@0+ (1,0) [0|0] ""  AF01A
 SG_ CAN_TX_TRACK_MED_RANGE_MODE : 55|2@0+ (1,0) [0|3] ""  AF01A
 SG_ CAN_TX_TRACK_LAT_RATE : 7|6@0- (0.25,0) [-8|7.75] ""  AF01A
 SG_ CAN_TX_TRACK_GROUPING_CHANGED : 1|1@0+ (1,0) [0|0] ""  AF01A
 SG_ CAN_TX_TRACK_BRIDGE_OBJECT : 39|1@0+ (1,0) [0|0] ""  AF01A
 SG_ CAN_TX_TRACK_ANGLE : 12|10@0- (0.1,0) [-51.2|51.1] "deg"  AF01A

BO_ 1281 ESR_Track02: 8 Vector__XXX
 SG_ CAN_TX_TRACK_WIDTH : 37|4@0+ (0.5,0) [0|7.5] "m"  AF01A
 SG_ CAN_TX_TRACK_STATUS : 15|3@0+ (1,0) [0|7] ""  AF01A
 SG_ CAN_TX_TRACK_ROLLING_COUNT : 38|1@0+ (1,0) [0|1] ""  AF01A
 SG_ CAN_TX_TRACK_RANGE_RATE : 53|14@0- (0.01,0) [-81.92|81.91] "m/s"  AF01A
 SG_ CAN_TX_TRACK_RANGE_ACCEL : 33|10@0- (0.05,0) [-25.6|25.55] "m/s/s"  AF01A
 SG_ CAN_TX_TRACK_RANGE : 18|11@0+ (0.1,0) [0|204.7] "m"  AF01A
 SG_ CAN_TX_TRACK_ONCOMING : 0|1@0+ (1,0) [0|0] ""  AF01A
 SG_ CAN_TX_TRACK_MED_RANGE_MODE : 55|2@0+ (1,0) [0|3] ""  AF01A
 SG_ CAN_TX_TRACK_LAT_RATE : 7|6@0- (0.25,0) [-8|7.75] ""  AF01A
 SG_ CAN_TX_TRACK_GROUPING_CHANGED : 1|1@0+ (1,0) [0|0] ""  AF01A
 SG_ CAN_TX_TRACK_BRIDGE_OBJECT : 39|1@0+ (1,0) [0|0] ""  AF01A
 SG_ CAN_TX_TRACK_ANGLE : 12|10@0- (0.1,0) [-51.2|51.1] "deg"  AF01A

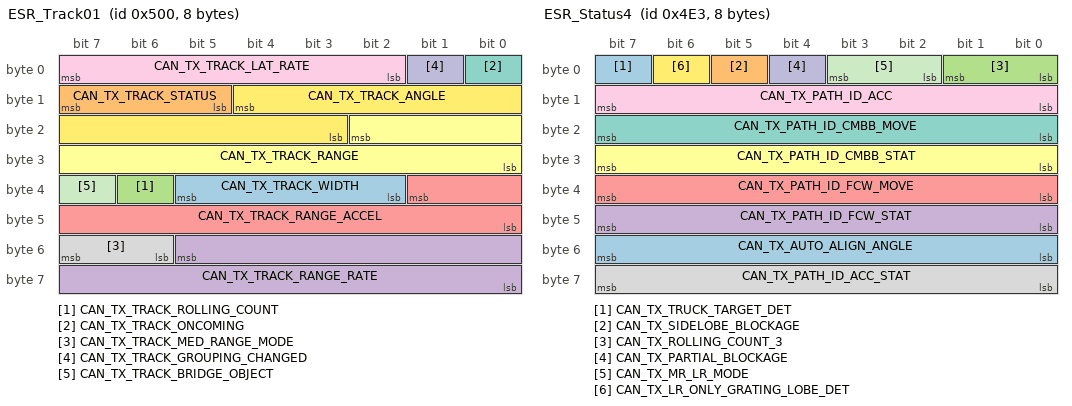
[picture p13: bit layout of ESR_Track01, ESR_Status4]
BO_ 1280 ESR_Track01: 8 Vector__XXX
 SG_ CAN_TX_TRACK_WIDTH : 37|4@0+ (0.5,0) [0|7.5] "m"  AF01A
 SG_ CAN_TX_TRACK_STATUS : 15|3@0+ (1,0) [0|7] ""  AF01A
 SG_ CAN_TX_TRACK_ROLLING_COUNT : 38|1@0+ (1,0) [0|1] ""  AF01A
 SG_ CAN_TX_TRACK_RANGE_RATE : 53|14@0- (0.01,0) [-81.92|81.91] "m/s"  AF01A
 SG_ CAN_TX_TRACK_RANGE_ACCEL : 33|10@0- (0.05,0) [-25.6|25.55] "m/s/s"  AF01A
 SG_ CAN_TX_TRACK_RANGE : 18|11@0+ (0.1,0) [0|204.7] "m"  AF01A
 SG_ CAN_TX_TRACK_ONCOMING : 0|1@0+ (1,0) [0|0] ""  AF01A
 SG_ CAN_TX_TRACK_MED_RANGE_MODE : 55|2@0+ (1,0) [0|3] ""  AF01A
 SG_ CAN_TX_TRACK_LAT_RATE : 7|6@0- (0.25,0) [-8|7.75] ""  AF01A
 SG_ CAN_TX_TRACK_GROUPING_CHANGED : 1|1@0+ (1,0) [0|0] ""  AF01A
 SG_ CAN_TX_TRACK_BRIDGE_OBJECT : 39|1@0+ (1,0) [0|0] ""  AF01A
 SG_ CAN_TX_TRACK_ANGLE : 12|10@0- (0.1,0) [-51.2|51.1] "deg"  AF01A

BO_ 1251 ESR_Status4: 8 Vector__XXX
 SG_ CAN_TX_TRUCK_TARGET_DET : 7|1@0+ (1,0) [0|0] ""  AF01A
 SG_ CAN_TX_SIDELOBE_BLOCKAGE : 5|1@0+ (1,0) [0|0] ""  AF01A
 SG_ CAN_TX_ROLLING_COUNT_3 : 1|2@0+ (1,0) [0|0] ""  AF01A
 SG_ CAN_TX_PATH_ID_FCW_STAT : 47|8@0+ (1,0) [0|0] ""  AF01A
 SG_ CAN_TX_PATH_ID_FCW_MOVE : 39|8@0+ (1,0) [0|0] ""  AF01A
 SG_ CAN_TX_PATH_ID_CMBB_STAT : 31|8@0+ (1,0) [0|0] ""  AF01A
 SG_ CAN_TX_PATH_ID_CMBB_MOVE : 23|8@0+ (1,0) [0|0] ""  AF01A
 SG_ CAN_TX_PATH_ID_ACC_STAT : 63|8@0+ (1,0) [0|0] ""  AF01A
 SG_ CAN_TX_PATH_ID_ACC : 15|8@0+ (1,0) [0|0] ""  AF01A
 SG_ CAN_TX_PARTIAL_BLOCKAGE : 4|1@0+ (1,0) [0|0] ""  AF01A
 SG_ CAN_TX_MR_LR_MODE : 3|2@0+ (1,0) [0|3] ""  AF01A
 SG_ CAN_TX_LR_ONLY_GRATING_LOBE_DET : 6|1@0+ (1,0) [0|0] ""  AF01A
 SG_ CAN_TX_AUTO_ALIGN_ANGLE : 55|8@0- (0.0625,0) [-8|7.9375] ""  AF01A

BO_ 1250 ESR_Status3: 8 Vector__XXX
 SG_ CAN_TX_SW_VERSION_PLD : 63|8@0+ (1,0) [0|0] ""  AF01A
 SG_ CAN_TX_SW_VERSION_HOST : 15|24@0+ (1,0) [0|0] ""  AF01A
 SG_ CAN_TX_SERIAL_NUM : 39|24@0+ (1,0) [0|0] ""  AF01A
 SG_ CAN_TX_INTERFACE_VERSION : 7|4@0+ (1,0) [0|0] ""  AF01A
 SG_ CAN_TX_HW_VERSION : 3|4@0+ (1,0) [0|0] ""  AF01A

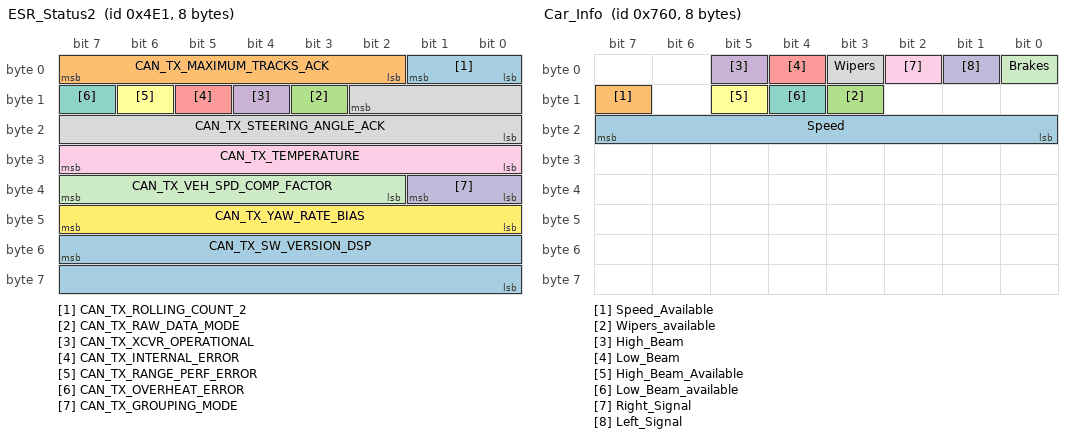
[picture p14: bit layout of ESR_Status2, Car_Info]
BO_ 1249 ESR_Status2: 8 Vector__XXX
 SG_ CAN_TX_ROLLING_COUNT_2 : 1|2@0+ (1,0) [0|0] ""  AF01A
 SG_ CAN_TX_MAXIMUM_TRACKS_ACK : 7|6@0+ (1,0) [1|64] ""  AF01A
 SG_ CAN_TX_RAW_DATA_MODE : 11|1@0+ (1,0) [0|0] ""  AF01A
 SG_ CAN_TX_XCVR_OPERATIONAL : 12|1@0+ (1,0) [0|0] ""  AF01A
 SG_ CAN_TX_INTERNAL_ERROR : 13|1@0+ (1,0) [0|0] ""  AF01A
 SG_ CAN_TX_RANGE_PERF_ERROR : 14|1@0+ (1,0) [0|0] ""  AF01A
 SG_ CAN_TX_OVERHEAT_ERROR : 15|1@0+ (1,0) [0|0] ""  AF01A
 SG_ CAN_TX_STEERING_ANGLE_ACK : 10|11@0+ (1,0) [0|2047] "deg"  AF01A
 SG_ CAN_TX_TEMPERATURE : 31|8@0- (1,0) [-128|127] "degC"  AF01A
 SG_ CAN_TX_GROUPING_MODE : 33|2@0+ (1,0) [0|0] ""  AF01A
 SG_ CAN_TX_VEH_SPD_COMP_FACTOR : 39|6@0- (0.001953125,1) [0.9375|1.060546875] ""  AF01A
 SG_ CAN_TX_YAW_RATE_BIAS : 47|8@0- (0.125,0) [-16|15.875] ""  AF01A
 SG_ CAN_TX_SW_VERSION_DSP : 55|16@0+ (1,0) [0|0] ""  AF01A

BO_ 1248 ESR_Status1: 8 Vector__XXX
 SG_ CAN_TX_VEHICLE_SPEED_CALC : 50|11@0+ (0.0625,0) [0|127.9375] "m/s"  AF01A
 SG_ CAN_TX_YAW_RATE_CALC : 47|12@0- (0.0625,0) [-128|127.9375] "deg/s"  AF01A
 SG_ CAN_TX_SCAN_INDEX : 31|16@0+ (1,0) [0|65535] ""  AF01A
 SG_ CAN_TX_RADIUS_CURVATURE_CALC : 13|14@0- (1,0) [-8192|8191] "m"  AF01A
 SG_ CAN_TX_DSP_TIMESTAMP : 5|7@0+ (2,0) [0|254] "ms"  AF01A
 SG_ CAN_TX_COMM_ERROR : 14|1@0+ (1,0) [0|0] ""  AF01A
 SG_ CAN_TX_ROLLING_COUNT_1 : 7|2@0+ (1,0) [0|0] ""  AF01A

BO_ 1888 Car_Info: 8 AF01A
 SG_ Speed : 16|8@1+ (1,0) [0|255] "km/h" Vector__XXX
 SG_ Speed_Available : 15|1@1+ (1,0) [0|1] "" Vector__XXX
 SG_ Wipers_available : 11|1@1+ (1,0) [0|1] "" Vector__XXX
 SG_ High_Beam : 5|1@1+ (1,0) [0|1] "" Vector__XXX
 SG_ Low_Beam : 4|1@1+ (1,0) [0|1] "" Vector__XXX
 SG_ High_Beam_Available : 13|1@1+ (1,0) [0|1] "" Vector__XXX
 SG_ Low_Beam_available : 12|1@1+ (1,0) [0|1] "" Vector__XXX
 SG_ Wipers : 3|1@1+ (1,0) [0|1] "" Vector__XXX
 SG_ Right_Signal : 2|1@1+ (1,0) [0|1] "" Vector__XXX
 SG_ Left_Signal : 1|1@1+ (1,0) [0|1] "" Vector__XXX
 SG_ Brakes : 0|1@1+ (1,0) [0|1] "" Vector__XXX

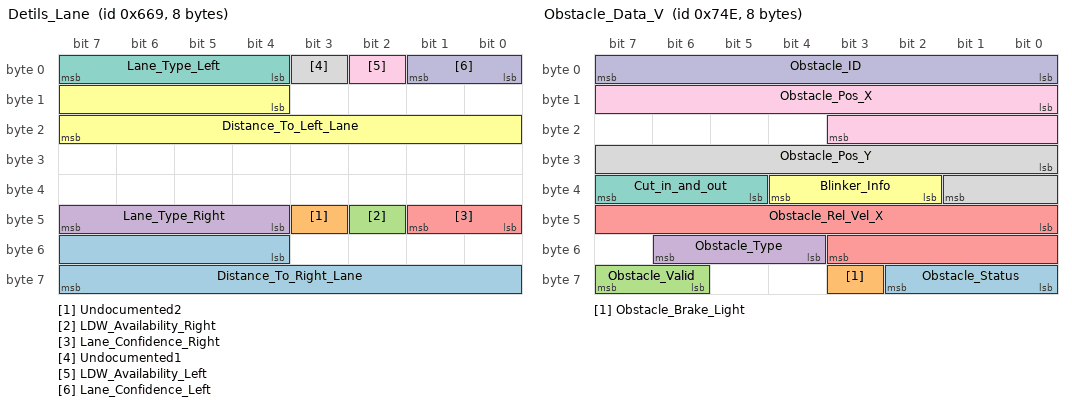
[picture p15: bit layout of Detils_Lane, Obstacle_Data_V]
BO_ 1641 Detils_Lane: 8 AF01A
 SG_ Distance_To_Right_Lane : 52|12@1- (0.02,0) [-40|40] "" Vector__XXX
 SG_ Undocumented2 : 43|1@1+ (1,0) [0|1] "" Vector__XXX
 SG_ LDW_Availability_Right : 42|1@1+ (1,0) [0|1] "" Vector__XXX
 SG_ Lane_Type_Right : 44|4@1+ (1,0) [0|15] "" Vector__XXX
 SG_ Lane_Confidence_Right : 40|2@1+ (1,0) [0|3] "m" Vector__XXX
 SG_ Distance_To_Left_Lane : 12|12@1- (0.02,0) [-40|40] "" Vector__XXX
 SG_ Lane_Type_Left : 4|4@1+ (1,0) [0|15] "" Vector__XXX
 SG_ Undocumented1 : 3|1@1+ (1,0) [0|1] "" Vector__XXX
 SG_ LDW_Availability_Left : 2|1@1+ (1,0) [0|1] "" Vector__XXX
 SG_ Lane_Confidence_Left : 0|2@1+ (1,0) [0|3] "m" Vector__XXX

BO_ 1915 Next_lane_Right_P: 4 AF01A
 SG_ View_range_availability : 31|1@1+ (1,0) [0|1] "" Vector__XXX
 SG_ View_range : 16|15@1+ (0.00390625,0) [0|127.99609375] "meter" Vector__XXX
 SG_ Heading_angle_Parameter_C1 : 0|16@1+ (0.0009765625,-31.999) [-0.357|0.357] "radians" Vector__XXX

BO_ 1914 Next_lane_Right_O: 8 AF01A
 SG_ Curvature_derivative_C3 : 40|16@1+ (3.72529E-009,-0.000122067) [-0.00012|0.00012] "n/a" Vector__XXX
 SG_ Curvature_Parameter_C2 : 24|16@1+ (9.765625E-007,-0.031999) [-0.031999|0.0320000234375] "n/a" Vector__XXX
 SG_ Position_Parameter_C0 : 8|16@1- (0.00390625,0) [-127|128] "meter" Vector__XXX
 SG_ Model_degree : 6|2@1+ (1,0) [0|3] "" Vector__XXX
 SG_ Quality : 4|2@1+ (1,0) [0|3] "" Vector__XXX
 SG_ Lane_type : 0|4@1+ (1,0) [0|15] "" Vector__XXX
 SG_ Lane_mark_width : 56|8@1+ (0.01,0) [0|2.5] "m" Vector__XXX

BO_ 1913 Next_lane_Left_N: 4 AF01A
 SG_ View_range_availability : 31|1@1+ (1,0) [0|1] "" Vector__XXX
 SG_ View_range : 16|15@1+ (0.00390625,0) [0|127.99609375] "meter" Vector__XXX
 SG_ Heading_angle_Parameter_C1 : 0|16@1+ (0.0009765625,-31.999) [-0.357|0.357] "radians" Vector__XXX

BO_ 1912 Next_lane_Left_M: 8 AF01A
 SG_ Curvature_derivative_C3 : 40|16@1+ (3.72529E-009,-0.000122067) [-0.00012|0.00012] "n/a" Vector__XXX
 SG_ Curvature_Parameter_C2 : 24|16@1+ (9.765625E-007,-0.031999) [-0.031999|0.0320000234375] "n/a" Vector__XXX
 SG_ Position_Parameter_C0 : 8|16@1- (0.00390625,0) [-127|128] "meter" Vector__XXX
 SG_ Model_degree : 6|2@1+ (1,0) [0|3] "" Vector__XXX
 SG_ Quality : 4|2@1+ (1,0) [0|3] "" Vector__XXX
 SG_ Lane_type : 0|4@1+ (1,0) [0|15] "" Vector__XXX
 SG_ Lane_mark_width : 56|8@1+ (0.01,0) [0|2.5] "m" Vector__XXX

BO_ 1909 Next_lane_Left_J: 4 AF01A
 SG_ View_range_availability : 31|1@1+ (1,0) [0|1] "" Vector__XXX
 SG_ View_range : 16|15@1+ (0.00390625,0) [0|127.99609375] "meter" Vector__XXX
 SG_ Heading_angle_Parameter_C1 : 0|16@1+ (0.0009765625,-31.999) [-0.357|0.357] "radians" Vector__XXX

BO_ 1908 Next_lane_Left_I: 8 AF01A
 SG_ Curvature_derivative_C3 : 40|16@1+ (3.72529E-009,-0.000122067) [-0.00012|0.00012] "n/a" Vector__XXX
 SG_ Curvature_Parameter_C2 : 24|16@1+ (9.765625E-007,-0.031999) [-0.031999|0.0320000234375] "n/a" Vector__XXX
 SG_ Position_Parameter_C0 : 8|16@1- (0.00390625,0) [-127|128] "meter" Vector__XXX
 SG_ Model_degree : 6|2@1+ (1,0) [0|3] "" Vector__XXX
 SG_ Quality : 4|2@1+ (1,0) [0|3] "" Vector__XXX
 SG_ Lane_type : 0|4@1+ (1,0) [0|15] "" Vector__XXX
 SG_ Lane_mark_width : 56|8@1+ (0.01,0) [0|2.5] "m" Vector__XXX

BO_ 1911 Next_lane_Right_L: 4 AF01A
 SG_ View_range_availability : 31|1@1+ (1,0) [0|1] "" Vector__XXX
 SG_ View_range : 16|15@1+ (0.00390625,0) [0|127.99609375] "meter" Vector__XXX
 SG_ Heading_angle_Parameter_C1 : 0|16@1+ (0.0009765625,-31.999) [-0.357|0.357] "radians" Vector__XXX

BO_ 1910 Next_lane_Right_K: 8 AF01A
 SG_ Curvature_derivative_C3 : 40|16@1+ (3.72529E-009,-0.000122067) [-0.00012|0.00012] "n/a" Vector__XXX
 SG_ Curvature_Parameter_C2 : 24|16@1+ (9.765625E-007,-0.031999) [-0.031999|0.0320000234375] "n/a" Vector__XXX
 SG_ Position_Parameter_C0 : 8|16@1- (0.00390625,0) [-127|128] "meter" Vector__XXX
 SG_ Model_degree : 6|2@1+ (1,0) [0|3] "" Vector__XXX
 SG_ Quality : 4|2@1+ (1,0) [0|3] "" Vector__XXX
 SG_ Lane_type : 0|4@1+ (1,0) [0|15] "" Vector__XXX
 SG_ Lane_mark_width : 56|8@1+ (0.01,0) [0|2.5] "m" Vector__XXX

BO_ 1907 Next_lane_Right_H: 4 AF01A
 SG_ View_range_availability : 31|1@1+ (1,0) [0|1] "" Vector__XXX
 SG_ View_range : 16|15@1+ (0.00390625,0) [0|127.99609375] "meter" Vector__XXX
 SG_ Heading_angle_Parameter_C1 : 0|16@1+ (0.0009765625,-31.999) [-0.357|0.357] "radians" Vector__XXX

BO_ 1906 Next_lane_Right_G: 8 AF01A
 SG_ Curvature_derivative_C3 : 40|16@1+ (3.72529E-009,-0.000122067) [-0.00012|0.00012] "n/a" Vector__XXX
 SG_ Curvature_Parameter_C2 : 24|16@1+ (9.765625E-007,-0.031999) [-0.031999|0.0320000234375] "n/a" Vector__XXX
 SG_ Position_Parameter_C0 : 8|16@1- (0.00390625,0) [-127|128] "meter" Vector__XXX
 SG_ Model_degree : 6|2@1+ (1,0) [0|3] "" Vector__XXX
 SG_ Quality : 4|2@1+ (1,0) [0|3] "" Vector__XXX
 SG_ Lane_type : 0|4@1+ (1,0) [0|15] "" Vector__XXX
 SG_ Lane_mark_width : 56|8@1+ (0.01,0) [0|2.5] "m" Vector__XXX

BO_ 1905 Next_lane_Left_F: 4 AF01A
 SG_ View_range_availability : 31|1@1+ (1,0) [0|1] "" Vector__XXX
 SG_ View_range : 16|15@1+ (0.00390625,0) [0|127.99609375] "meter" Vector__XXX
 SG_ Heading_angle_Parameter_C1 : 0|16@1+ (0.0009765625,-31.999) [-0.357|0.357] "radians" Vector__XXX

BO_ 1904 Next_lane_Left_E: 8 AF01A
 SG_ Curvature_derivative_C3 : 40|16@1+ (3.72529E-009,-0.000122067) [-0.00012|0.00012] "n/a" Vector__XXX
 SG_ Curvature_Parameter_C2 : 24|16@1+ (9.765625E-007,-0.031999) [-0.031999|0.0320000234375] "n/a" Vector__XXX
 SG_ Position_Parameter_C0 : 8|16@1- (0.00390625,0) [-127|128] "meter" Vector__XXX
 SG_ Model_degree : 6|2@1+ (1,0) [0|3] "" Vector__XXX
 SG_ Quality : 4|2@1+ (1,0) [0|3] "" Vector__XXX
 SG_ Lane_type : 0|4@1+ (1,0) [0|15] "" Vector__XXX
 SG_ Lane_mark_width : 56|8@1+ (0.01,0) [0|2.5] "m" Vector__XXX

BO_ 1903 Next_lane_Right_D: 4 AF01A
 SG_ View_range_availability : 31|1@1+ (1,0) [0|1] "" Vector__XXX
 SG_ View_range : 16|15@1+ (0.00390625,0) [0|127.99609375] "meter" Vector__XXX
 SG_ Heading_angle_Parameter_C1 : 0|16@1+ (0.0009765625,-31.999) [-0.357|0.357] "radians" Vector__XXX

BO_ 1902 Next_lane_Right_C: 8 AF01A
 SG_ Curvature_derivative_C3 : 40|16@1+ (3.72529E-009,-0.000122067) [-0.00012|0.00012] "n/a" Vector__XXX
 SG_ Curvature_Parameter_C2 : 24|16@1+ (9.765625E-007,-0.031999) [-0.031999|0.0320000234375] "n/a" Vector__XXX
 SG_ Position_Parameter_C0 : 8|16@1- (0.00390625,0) [-127|128] "meter" Vector__XXX
 SG_ Model_degree : 6|2@1+ (1,0) [0|3] "" Vector__XXX
 SG_ Quality : 4|2@1+ (1,0) [0|3] "" Vector__XXX
 SG_ Lane_type : 0|4@1+ (1,0) [0|15] "" Vector__XXX
 SG_ Lane_mark_width : 56|8@1+ (0.01,0) [0|2.5] "m" Vector__XXX

BO_ 1872 Obstacle_Data_X: 8 AF01A
 SG_ Obstacle_Angle : 48|16@1- (0.01,0) [-327.68|327.68] "degree" Vector__XXX
 SG_ Obstacle_Replaced : 44|1@1+ (1,0) [0|1] "" Vector__XXX
 SG_ Object_Accel_X : 32|10@1- (0.03,0) [-14.97|14.97] "m/s^2" Vector__XXX
 SG_ Obstacle_Scale_Change : 16|16@1- (0.0002,0) [-6.5532|6.5532] "pix/sec" Vector__XXX
 SG_ Obstacle_Angle_Rate : 0|16@1- (0.01,0) [-327.68|327.68] "degree" Vector__XXX

BO_ 1869 Obstacle_Data_U: 8 AF01A
 SG_ Obstacle_Angle : 48|16@1- (0.01,0) [-327.68|327.68] "degree" Vector__XXX
 SG_ Obstacle_Replaced : 44|1@1+ (1,0) [0|1] "" Vector__XXX
 SG_ Object_Accel_X : 32|10@1- (0.03,0) [-14.97|14.97] "m/s^2" Vector__XXX
 SG_ Obstacle_Scale_Change : 16|16@1- (0.0002,0) [-6.5532|6.5532] "pix/sec" Vector__XXX
 SG_ Obstacle_Angle_Rate : 0|16@1- (0.01,0) [-327.68|327.68] "degree" Vector__XXX

BO_ 1866 Obstacle_Data_R: 8 AF01A
 SG_ Obstacle_Angle : 48|16@1- (0.01,0) [-327.68|327.68] "degree" Vector__XXX
 SG_ Obstacle_Replaced : 44|1@1+ (1,0) [0|1] "" Vector__XXX
 SG_ Object_Accel_X : 32|10@1- (0.03,0) [-14.97|14.97] "m/s^2" Vector__XXX
 SG_ Obstacle_Scale_Change : 16|16@1- (0.0002,0) [-6.5532|6.5532] "pix/sec" Vector__XXX
 SG_ Obstacle_Angle_Rate : 0|16@1- (0.01,0) [-327.68|327.68] "degree" Vector__XXX

BO_ 1863 Obstacle_Data_O: 8 AF01A
 SG_ Obstacle_Angle : 48|16@1- (0.01,0) [-327.68|327.68] "degree" Vector__XXX
 SG_ Obstacle_Replaced : 44|1@1+ (1,0) [0|1] "" Vector__XXX
 SG_ Object_Accel_X : 32|10@1- (0.03,0) [-14.97|14.97] "m/s^2" Vector__XXX
 SG_ Obstacle_Scale_Change : 16|16@1- (0.0002,0) [-6.5532|6.5532] "pix/sec" Vector__XXX
 SG_ Obstacle_Angle_Rate : 0|16@1- (0.01,0) [-327.68|327.68] "degree" Vector__XXX

BO_ 1860 Obstacle_Data_L: 8 AF01A
 SG_ Obstacle_Angle : 48|16@1- (0.01,0) [-327.68|327.68] "degree" Vector__XXX
 SG_ Obstacle_Replaced : 44|1@1+ (1,0) [0|1] "" Vector__XXX
 SG_ Object_Accel_X : 32|10@1- (0.03,0) [-14.97|14.97] "m/s^2" Vector__XXX
 SG_ Obstacle_Scale_Change : 16|16@1- (0.0002,0) [-6.5532|6.5532] "pix/sec" Vector__XXX
 SG_ Obstacle_Angle_Rate : 0|16@1- (0.01,0) [-327.68|327.68] "degree" Vector__XXX

BO_ 1857 Obstacle_Data_I: 8 AF01A
 SG_ Obstacle_Angle : 48|16@1- (0.01,0) [-327.68|327.68] "degree" Vector__XXX
 SG_ Obstacle_Replaced : 44|1@1+ (1,0) [0|1] "" Vector__XXX
 SG_ Object_Accel_X : 32|10@1- (0.03,0) [-14.97|14.97] "m/s^2" Vector__XXX
 SG_ Obstacle_Scale_Change : 16|16@1- (0.0002,0) [-6.5532|6.5532] "pix/sec" Vector__XXX
 SG_ Obstacle_Angle_Rate : 0|16@1- (0.01,0) [-327.68|327.68] "degree" Vector__XXX

BO_ 1854 Obstacle_Data_F: 8 AF01A
 SG_ Obstacle_Angle : 48|16@1- (0.01,0) [-327.68|327.68] "degree" Vector__XXX
 SG_ Obstacle_Replaced : 44|1@1+ (1,0) [0|1] "" Vector__XXX
 SG_ Object_Accel_X : 32|10@1- (0.03,0) [-14.97|14.97] "m/s^2" Vector__XXX
 SG_ Obstacle_Scale_Change : 16|16@1- (0.0002,0) [-6.5532|6.5532] "pix/sec" Vector__XXX
 SG_ Obstacle_Angle_Rate : 0|16@1- (0.01,0) [-327.68|327.68] "degree" Vector__XXX

BO_ 1871 Obstacle_Data_W: 8 AF01A
 SG_ Matched_Radar_ID : 56|7@1+ (1,0) [0|127] "" Vector__XXX
 SG_ Radar_Match_Confidence : 52|3@1+ (1,0) [0.5|5] "" Vector__XXX
 SG_ CIPV_Flag : 26|1@1+ (1,0) [0|1] "Enum" Vector__XXX
 SG_ Obstacle_Lane : 24|2@1+ (1,0) [0|3] "Enum" Vector__XXX
 SG_ Radar_Vel_X : 40|12@1- (0.0625,0) [-127.93|127.93] "meter/sec" Vector__XXX
 SG_ Radar_Pos_X : 28|12@1+ (0.0625,0) [0|250] "meter" Vector__XXX
 SG_ Obstacle_Age : 16|8@1+ (1,0) [0|255] "" Vector__XXX
 SG_ Obstacle_Width : 8|8@1+ (0.05,0) [0|12.5] "meter" Vector__XXX
 SG_ Obstacle_Legnth : 0|8@1+ (0.5,0) [0|31] "meter" Vector__XXX

BO_ 1868 Obstacle_Data_T: 8 AF01A
 SG_ Matched_Radar_ID : 56|7@1+ (1,0) [0|127] "" Vector__XXX
 SG_ Radar_Match_Confidence : 52|3@1+ (1,0) [0.5|5] "" Vector__XXX
 SG_ CIPV_Flag : 26|1@1+ (1,0) [0|1] "Enum" Vector__XXX
 SG_ Obstacle_Lane : 24|2@1+ (1,0) [0|3] "Enum" Vector__XXX
 SG_ Radar_Vel_X : 40|12@1- (0.0625,0) [-127.93|127.93] "meter/sec" Vector__XXX
 SG_ Radar_Pos_X : 28|12@1+ (0.0625,0) [0|250] "meter" Vector__XXX
 SG_ Obstacle_Age : 16|8@1+ (1,0) [0|255] "" Vector__XXX
 SG_ Obstacle_Width : 8|8@1+ (0.05,0) [0|12.5] "meter" Vector__XXX
 SG_ Obstacle_Legnth : 0|8@1+ (0.5,0) [0|31] "meter" Vector__XXX

BO_ 1865 Obstacle_Data_Q: 8 AF01A
 SG_ Matched_Radar_ID : 56|7@1+ (1,0) [0|127] "" Vector__XXX
 SG_ Radar_Match_Confidence : 52|3@1+ (1,0) [0.5|5] "" Vector__XXX
 SG_ CIPV_Flag : 26|1@1+ (1,0) [0|1] "Enum" Vector__XXX
 SG_ Obstacle_Lane : 24|2@1+ (1,0) [0|3] "Enum" Vector__XXX
 SG_ Radar_Vel_X : 40|12@1- (0.0625,0) [-127.93|127.93] "meter/sec" Vector__XXX
 SG_ Radar_Pos_X : 28|12@1+ (0.0625,0) [0|250] "meter" Vector__XXX
 SG_ Obstacle_Age : 16|8@1+ (1,0) [0|255] "" Vector__XXX
 SG_ Obstacle_Width : 8|8@1+ (0.05,0) [0|12.5] "meter" Vector__XXX
 SG_ Obstacle_Legnth : 0|8@1+ (0.5,0) [0|31] "meter" Vector__XXX

BO_ 1862 Obstacle_Data_N: 8 AF01A
 SG_ Matched_Radar_ID : 56|7@1+ (1,0) [0|127] "" Vector__XXX
 SG_ Radar_Match_Confidence : 52|3@1+ (1,0) [0.5|5] "" Vector__XXX
 SG_ CIPV_Flag : 26|1@1+ (1,0) [0|1] "Enum" Vector__XXX
 SG_ Obstacle_Lane : 24|2@1+ (1,0) [0|3] "Enum" Vector__XXX
 SG_ Radar_Vel_X : 40|12@1- (0.0625,0) [-127.93|127.93] "meter/sec" Vector__XXX
 SG_ Radar_Pos_X : 28|12@1+ (0.0625,0) [0|250] "meter" Vector__XXX
 SG_ Obstacle_Age : 16|8@1+ (1,0) [0|255] "" Vector__XXX
 SG_ Obstacle_Width : 8|8@1+ (0.05,0) [0|12.5] "meter" Vector__XXX
 SG_ Obstacle_Legnth : 0|8@1+ (0.5,0) [0|31] "meter" Vector__XXX

BO_ 1859 Obstacle_Data_K: 8 AF01A
 SG_ Matched_Radar_ID : 56|7@1+ (1,0) [0|127] "" Vector__XXX
 SG_ Radar_Match_Confidence : 52|3@1+ (1,0) [0.5|5] "" Vector__XXX
 SG_ CIPV_Flag : 26|1@1+ (1,0) [0|1] "Enum" Vector__XXX
 SG_ Obstacle_Lane : 24|2@1+ (1,0) [0|3] "Enum" Vector__XXX
 SG_ Radar_Vel_X : 40|12@1- (0.0625,0) [-127.93|127.93] "meter/sec" Vector__XXX
 SG_ Radar_Pos_X : 28|12@1+ (0.0625,0) [0|250] "meter" Vector__XXX
 SG_ Obstacle_Age : 16|8@1+ (1,0) [0|255] "" Vector__XXX
 SG_ Obstacle_Width : 8|8@1+ (0.05,0) [0|12.5] "meter" Vector__XXX
 SG_ Obstacle_Legnth : 0|8@1+ (0.5,0) [0|31] "meter" Vector__XXX

BO_ 1856 Obstacle_Data_H: 8 AF01A
 SG_ Matched_Radar_ID : 56|7@1+ (1,0) [0|127] "" Vector__XXX
 SG_ Radar_Match_Confidence : 52|3@1+ (1,0) [0.5|5] "" Vector__XXX
 SG_ CIPV_Flag : 26|1@1+ (1,0) [0|1] "Enum" Vector__XXX
 SG_ Obstacle_Lane : 24|2@1+ (1,0) [0|3] "Enum" Vector__XXX
 SG_ Radar_Vel_X : 40|12@1- (0.0625,0) [-127.93|127.93] "meter/sec" Vector__XXX
 SG_ Radar_Pos_X : 28|12@1+ (0.0625,0) [0|250] "meter" Vector__XXX
 SG_ Obstacle_Age : 16|8@1+ (1,0) [0|255] "" Vector__XXX
 SG_ Obstacle_Width : 8|8@1+ (0.05,0) [0|12.5] "meter" Vector__XXX
 SG_ Obstacle_Legnth : 0|8@1+ (0.5,0) [0|31] "meter" Vector__XXX

BO_ 1853 Obstacle_Data_E: 8 AF01A
 SG_ Matched_Radar_ID : 56|7@1+ (1,0) [0|127] "" Vector__XXX
 SG_ Radar_Match_Confidence : 52|3@1+ (1,0) [0.5|5] "" Vector__XXX
 SG_ CIPV_Flag : 26|1@1+ (1,0) [0|1] "Enum" Vector__XXX
 SG_ Obstacle_Lane : 24|2@1+ (1,0) [0|3] "Enum" Vector__XXX
 SG_ Radar_Vel_X : 40|12@1- (0.0625,0) [-127.93|127.93] "meter/sec" Vector__XXX
 SG_ Radar_Pos_X : 28|12@1+ (0.0625,0) [0|250] "meter" Vector__XXX
 SG_ Obstacle_Age : 16|8@1+ (1,0) [0|255] "" Vector__XXX
 SG_ Obstacle_Width : 8|8@1+ (0.05,0) [0|12.5] "meter" Vector__XXX
 SG_ Obstacle_Legnth : 0|8@1+ (0.5,0) [0|31] "meter" Vector__XXX

BO_ 1870 Obstacle_Data_V: 8 AF01A
 SG_ Obstacle_Status : 56|3@1+ (1,0) [0|7] "" Vector__XXX
 SG_ Obstacle_Brake_Light : 59|1@1+ (1,0) [0|1] "" Vector__XXX
 SG_ Obstacle_Valid : 62|2@1+ (1,0) [0|3] "" Vector__XXX
 SG_ Obstacle_Type : 52|3@1+ (1,0) [0|7] "" Vector__XXX
 SG_ Obstacle_Rel_Vel_X : 40|12@1- (0.0625,0) [-127.93|127.93] "meter/sec" Vector__XXX
 SG_ Blinker_Info : 34|3@1+ (1,0) [0|7] "" Vector__XXX
 SG_ Cut_in_and_out : 37|3@1+ (1,0) [0|7] "" Vector__XXX
 SG_ Obstacle_Pos_Y : 24|10@1- (0.0625,0) [-31.93|31.93] "m" Vector__XXX
 SG_ Obstacle_Pos_X : 8|12@1+ (0.0625,0) [0|250] "meter" Vector__XXX
 SG_ Obstacle_ID : 0|8@1+ (1,0) [0|63] "" Vector__XXX

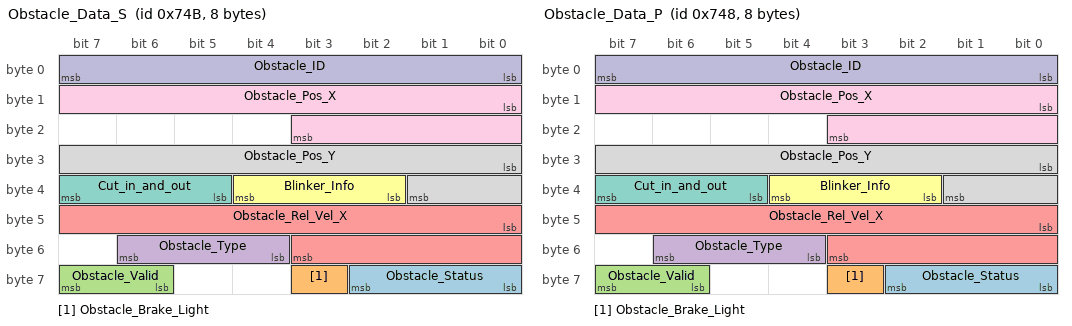
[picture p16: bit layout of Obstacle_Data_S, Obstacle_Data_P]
BO_ 1867 Obstacle_Data_S: 8 AF01A
 SG_ Obstacle_Status : 56|3@1+ (1,0) [0|7] "" Vector__XXX
 SG_ Obstacle_Brake_Light : 59|1@1+ (1,0) [0|1] "" Vector__XXX
 SG_ Obstacle_Valid : 62|2@1+ (1,0) [0|3] "" Vector__XXX
 SG_ Obstacle_Type : 52|3@1+ (1,0) [0|7] "" Vector__XXX
 SG_ Obstacle_Rel_Vel_X : 40|12@1- (0.0625,0) [-127.93|127.93] "meter/sec" Vector__XXX
 SG_ Blinker_Info : 34|3@1+ (1,0) [0|7] "" Vector__XXX
 SG_ Cut_in_and_out : 37|3@1+ (1,0) [0|7] "" Vector__XXX
 SG_ Obstacle_Pos_Y : 24|10@1- (0.0625,0) [-31.93|31.93] "m" Vector__XXX
 SG_ Obstacle_Pos_X : 8|12@1+ (0.0625,0) [0|250] "meter" Vector__XXX
 SG_ Obstacle_ID : 0|8@1+ (1,0) [0|63] "" Vector__XXX

BO_ 1864 Obstacle_Data_P: 8 AF01A
 SG_ Obstacle_Status : 56|3@1+ (1,0) [0|7] "" Vector__XXX
 SG_ Obstacle_Brake_Light : 59|1@1+ (1,0) [0|1] "" Vector__XXX
 SG_ Obstacle_Valid : 62|2@1+ (1,0) [0|3] "" Vector__XXX
 SG_ Obstacle_Type : 52|3@1+ (1,0) [0|7] "" Vector__XXX
 SG_ Obstacle_Rel_Vel_X : 40|12@1- (0.0625,0) [-127.93|127.93] "meter/sec" Vector__XXX
 SG_ Blinker_Info : 34|3@1+ (1,0) [0|7] "" Vector__XXX
 SG_ Cut_in_and_out : 37|3@1+ (1,0) [0|7] "" Vector__XXX
 SG_ Obstacle_Pos_Y : 24|10@1- (0.0625,0) [-31.93|31.93] "m" Vector__XXX
 SG_ Obstacle_Pos_X : 8|12@1+ (0.0625,0) [0|250] "meter" Vector__XXX
 SG_ Obstacle_ID : 0|8@1+ (1,0) [0|63] "" Vector__XXX

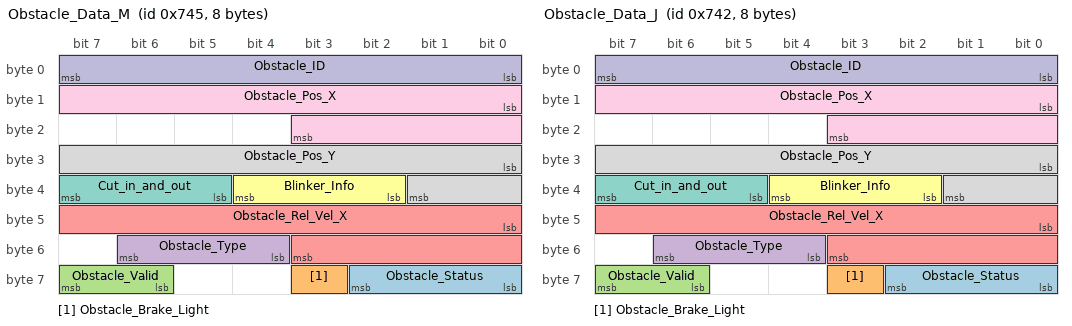
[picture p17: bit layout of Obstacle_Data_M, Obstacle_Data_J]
BO_ 1861 Obstacle_Data_M: 8 AF01A
 SG_ Obstacle_Status : 56|3@1+ (1,0) [0|7] "" Vector__XXX
 SG_ Obstacle_Brake_Light : 59|1@1+ (1,0) [0|1] "" Vector__XXX
 SG_ Obstacle_Valid : 62|2@1+ (1,0) [0|3] "" Vector__XXX
 SG_ Obstacle_Type : 52|3@1+ (1,0) [0|7] "" Vector__XXX
 SG_ Obstacle_Rel_Vel_X : 40|12@1- (0.0625,0) [-127.93|127.93] "meter/sec" Vector__XXX
 SG_ Blinker_Info : 34|3@1+ (1,0) [0|7] "" Vector__XXX
 SG_ Cut_in_and_out : 37|3@1+ (1,0) [0|7] "" Vector__XXX
 SG_ Obstacle_Pos_Y : 24|10@1- (0.0625,0) [-31.93|31.93] "m" Vector__XXX
 SG_ Obstacle_Pos_X : 8|12@1+ (0.0625,0) [0|250] "meter" Vector__XXX
 SG_ Obstacle_ID : 0|8@1+ (1,0) [0|63] "" Vector__XXX

BO_ 1858 Obstacle_Data_J: 8 AF01A
 SG_ Obstacle_Status : 56|3@1+ (1,0) [0|7] "" Vector__XXX
 SG_ Obstacle_Brake_Light : 59|1@1+ (1,0) [0|1] "" Vector__XXX
 SG_ Obstacle_Valid : 62|2@1+ (1,0) [0|3] "" Vector__XXX
 SG_ Obstacle_Type : 52|3@1+ (1,0) [0|7] "" Vector__XXX
 SG_ Obstacle_Rel_Vel_X : 40|12@1- (0.0625,0) [-127.93|127.93] "meter/sec" Vector__XXX
 SG_ Blinker_Info : 34|3@1+ (1,0) [0|7] "" Vector__XXX
 SG_ Cut_in_and_out : 37|3@1+ (1,0) [0|7] "" Vector__XXX
 SG_ Obstacle_Pos_Y : 24|10@1- (0.0625,0) [-31.93|31.93] "m" Vector__XXX
 SG_ Obstacle_Pos_X : 8|12@1+ (0.0625,0) [0|250] "meter" Vector__XXX
 SG_ Obstacle_ID : 0|8@1+ (1,0) [0|63] "" Vector__XXX

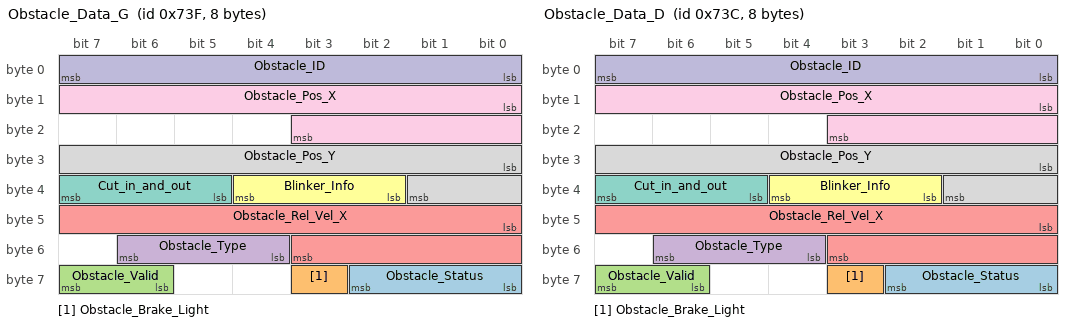
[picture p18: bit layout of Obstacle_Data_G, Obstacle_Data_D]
BO_ 1855 Obstacle_Data_G: 8 AF01A
 SG_ Obstacle_Status : 56|3@1+ (1,0) [0|7] "" Vector__XXX
 SG_ Obstacle_Brake_Light : 59|1@1+ (1,0) [0|1] "" Vector__XXX
 SG_ Obstacle_Valid : 62|2@1+ (1,0) [0|3] "" Vector__XXX
 SG_ Obstacle_Type : 52|3@1+ (1,0) [0|7] "" Vector__XXX
 SG_ Obstacle_Rel_Vel_X : 40|12@1- (0.0625,0) [-127.93|127.93] "meter/sec" Vector__XXX
 SG_ Blinker_Info : 34|3@1+ (1,0) [0|7] "" Vector__XXX
 SG_ Cut_in_and_out : 37|3@1+ (1,0) [0|7] "" Vector__XXX
 SG_ Obstacle_Pos_Y : 24|10@1- (0.0625,0) [-31.93|31.93] "m" Vector__XXX
 SG_ Obstacle_Pos_X : 8|12@1+ (0.0625,0) [0|250] "meter" Vector__XXX
 SG_ Obstacle_ID : 0|8@1+ (1,0) [0|63] "" Vector__XXX

BO_ 1852 Obstacle_Data_D: 8 AF01A
 SG_ Obstacle_Status : 56|3@1+ (1,0) [0|7] "" Vector__XXX
 SG_ Obstacle_Brake_Light : 59|1@1+ (1,0) [0|1] "" Vector__XXX
 SG_ Obstacle_Valid : 62|2@1+ (1,0) [0|3] "" Vector__XXX
 SG_ Obstacle_Type : 52|3@1+ (1,0) [0|7] "" Vector__XXX
 SG_ Obstacle_Rel_Vel_X : 40|12@1- (0.0625,0) [-127.93|127.93] "meter/sec" Vector__XXX
 SG_ Blinker_Info : 34|3@1+ (1,0) [0|7] "" Vector__XXX
 SG_ Cut_in_and_out : 37|3@1+ (1,0) [0|7] "" Vector__XXX
 SG_ Obstacle_Pos_Y : 24|10@1- (0.0625,0) [-31.93|31.93] "m" Vector__XXX
 SG_ Obstacle_Pos_X : 8|12@1+ (0.0625,0) [0|250] "meter" Vector__XXX
 SG_ Obstacle_ID : 0|8@1+ (1,0) [0|63] "" Vector__XXX

BO_ 1830 TSR_message_G: 6 AF01A
 SG_ Sign_Position_Z : 32|8@1- (0.5,0) [-16|16] "meter" Vector__XXX
 SG_ Filter_Type : 40|8@1+ (1,0) [0|255] "" Vector__XXX
 SG_ Sign_Position_Y : 24|8@1- (0.5,0) [-32|31] "meter" Vector__XXX
 SG_ Sign_Position_X : 16|8@1+ (0.5,0) [0|122] "meter" Vector__XXX
 SG_ Supplementary_Sign_Type : 8|8@1+ (1,0) [0|255] "" Vector__XXX
 SG_ Vision_only_Sign_Type : 0|8@1+ (1,0) [0|255] "" Vector__XXX

BO_ 1829 TSR_message_F: 6 AF01A
 SG_ Sign_Position_Z : 32|8@1- (0.5,0) [-16|16] "meter" Vector__XXX
 SG_ Filter_Type : 40|8@1+ (1,0) [0|255] "" Vector__XXX
 SG_ Sign_Position_Y : 24|8@1- (0.5,0) [-32|31] "meter" Vector__XXX
 SG_ Sign_Position_X : 16|8@1+ (0.5,0) [0|122] "meter" Vector__XXX
 SG_ Supplementary_Sign_Type : 8|8@1+ (1,0) [0|255] "" Vector__XXX
 SG_ Vision_only_Sign_Type : 0|8@1+ (1,0) [0|255] "" Vector__XXX

BO_ 1828 TSR_message_E: 6 AF01A
 SG_ Sign_Position_Z : 32|8@1- (0.5,0) [-16|16] "meter" Vector__XXX
 SG_ Filter_Type : 40|8@1+ (1,0) [0|255] "" Vector__XXX
 SG_ Sign_Position_Y : 24|8@1- (0.5,0) [-32|31] "meter" Vector__XXX
 SG_ Sign_Position_X : 16|8@1+ (0.5,0) [0|122] "meter" Vector__XXX
 SG_ Supplementary_Sign_Type : 8|8@1+ (1,0) [0|255] "" Vector__XXX
 SG_ Vision_only_Sign_Type : 0|8@1+ (1,0) [0|255] "" Vector__XXX

BO_ 1827 TSR_message_D: 6 AF01A
 SG_ Sign_Position_Z : 32|8@1- (0.5,0) [-16|16] "meter" Vector__XXX
 SG_ Filter_Type : 40|8@1+ (1,0) [0|255] "" Vector__XXX
 SG_ Sign_Position_Y : 24|8@1- (0.5,0) [-32|31] "meter" Vector__XXX
 SG_ Sign_Position_X : 16|8@1+ (0.5,0) [0|122] "meter" Vector__XXX
 SG_ Supplementary_Sign_Type : 8|8@1+ (1,0) [0|255] "" Vector__XXX
 SG_ Vision_only_Sign_Type : 0|8@1+ (1,0) [0|255] "" Vector__XXX

BO_ 1826 TSR_message_C: 6 AF01A
 SG_ Sign_Position_Z : 32|8@1- (0.5,0) [-16|16] "meter" Vector__XXX
 SG_ Filter_Type : 40|8@1+ (1,0) [0|255] "" Vector__XXX
 SG_ Sign_Position_Y : 24|8@1- (0.5,0) [-32|31] "meter" Vector__XXX
 SG_ Sign_Position_X : 16|8@1+ (0.5,0) [0|122] "meter" Vector__XXX
 SG_ Supplementary_Sign_Type : 8|8@1+ (1,0) [0|255] "" Vector__XXX
 SG_ Vision_only_Sign_Type : 0|8@1+ (1,0) [0|255] "" Vector__XXX

BO_ 1825 TSR_message_B: 6 AF01A
 SG_ Sign_Position_Z : 32|8@1- (0.5,0) [-16|16] "meter" Vector__XXX
 SG_ Filter_Type : 40|8@1+ (1,0) [0|255] "" Vector__XXX
 SG_ Sign_Position_Y : 24|8@1- (0.5,0) [-32|31] "meter" Vector__XXX
 SG_ Sign_Position_X : 16|8@1+ (0.5,0) [0|122] "meter" Vector__XXX
 SG_ Supplementary_Sign_Type : 8|8@1+ (1,0) [0|255] "" Vector__XXX
 SG_ Vision_only_Sign_Type : 0|8@1+ (1,0) [0|255] "" Vector__XXX

BO_ 1898 Reference_points: 8 AF01A
 SG_ Ref_point_2_validity : 63|1@1+ (1,0) [0|1] "" Vector__XXX
 SG_ Ref_point_1_validity : 31|1@1+ (1,0) [0|1] "" Vector__XXX
 SG_ Ref_point_2_Distance : 48|15@1+ (0.00390625,0) [0|127.99609376] "meters" Vector__XXX
 SG_ Ref_point_2_Position : 32|16@1+ (0.00390625,-127.99609375) [-127.996|127.996] "meters" Vector__XXX
 SG_ Ref_point_1_Distance : 16|15@1+ (0.00390625,0) [0|127.99609376] "meters" Vector__XXX
 SG_ Ref_point_1_Position : 0|16@1+ (0.00390625,-127.99609376) [-127.996|127.996] "meters" Vector__XXX

BO_ 1899 Numebr_of_next_lane: 1 AF01A
 SG_ Number_lane_markers_reported : 0|8@1+ (1,0) [0|7] "" Vector__XXX

BO_ 1901 Next_lane_Left_B: 4 AF01A
 SG_ View_range_availability : 31|1@1+ (1,0) [0|1] "" Vector__XXX
 SG_ View_range : 16|15@1+ (0.00390625,0) [0|127.99609375] "meter" Vector__XXX
 SG_ Heading_angle_Parameter_C1 : 0|16@1+ (0.0009765625,-31.999) [-0.357|0.357] "radians" Vector__XXX

BO_ 1900 Next_lane_Left_A: 8 AF01A
 SG_ Curvature_derivative_C3 : 40|16@1+ (3.72529E-009,-0.000122067) [-0.00012|0.00012] "n/a" Vector__XXX
 SG_ Curvature_Parameter_C2 : 24|16@1+ (9.765625E-007,-0.031999) [-0.031999|0.0320000234375] "n/a" Vector__XXX
 SG_ Position_Parameter_C0 : 8|16@1- (0.00390625,0) [-127|128] "meter" Vector__XXX
 SG_ Model_degree : 6|2@1+ (1,0) [0|3] "" Vector__XXX
 SG_ Quality : 4|2@1+ (1,0) [0|3] "" Vector__XXX
 SG_ Lane_type : 0|4@1+ (1,0) [0|15] "" Vector__XXX
 SG_ Lane_mark_width : 56|8@1+ (0.01,0) [0|2.5] "m" Vector__XXX

BO_ 1897 LKA_right_lane_B: 4 AF01A
 SG_ View_range_availability : 31|1@1+ (1,0) [0|1] "" Vector__XXX
 SG_ View_range : 16|15@1+ (0.00390625,0) [0|127.99609375] "meter" Vector__XXX
 SG_ Heading_angle_Parameter_C1 : 0|16@1+ (0.0009765625,-31.999) [-0.357|0.357] "radians" Vector__XXX

BO_ 1896 LKA_right_lane_A: 8 AF01A
 SG_ Curvature_derivative_C3 : 40|16@1+ (3.72529E-009,-0.000122067) [-0.00012|0.00012] "n/a" Vector__XXX
 SG_ Curvature_Parameter_C2 : 24|16@1+ (9.765625E-007,-0.031999) [-0.031999|0.0320000234375] "n/a" Vector__XXX
 SG_ Position_Parameter_C0 : 8|16@1- (0.00390625,0) [-127|128] "meter" Vector__XXX
 SG_ Model_degree : 6|2@1+ (1,0) [0|3] "" Vector__XXX
 SG_ Quality : 4|2@1+ (1,0) [0|3] "" Vector__XXX
 SG_ Lane_type : 0|4@1+ (1,0) [0|15] "" Vector__XXX
 SG_ Width_right_marking : 56|8@1+ (0.01,0) [0|2.5] "m" Vector__XXX

BO_ 1895 LKA_left_lane_B: 4 AF01A
 SG_ Heading_angle_Parameter_C1 : 0|16@1+ (0.0009765625,-31.999) [-0.357|0.357] "radians" Vector__XXX
 SG_ View_range_availability : 31|1@1+ (1,0) [0|1] "" Vector__XXX
 SG_ View_range : 16|15@1+ (0.00390625,0) [0|127.99609375] "meter" Vector__XXX

BO_ 1894 LKA_left_lane_A: 8 AF01A
 SG_ Curvature_Parameter_C2 : 24|16@1+ (9.765625E-007,-0.031999) [-0.031999|0.0320000234375] "n/a" Vector__XXX
 SG_ Width_left_marking : 56|8@1+ (0.01,0) [0|2.5] "m" Vector__XXX
 SG_ Curvature_derivative_C3 : 40|16@1+ (3.72529E-009,-0.000122067) [-0.00012|0.00012] "n/a" Vector__XXX
 SG_ Position_Parameter_C0 : 8|16@1- (0.00390625,0) [-127|128] "meter" Vector__XXX
 SG_ Model_degree : 6|2@1+ (1,0) [0|3] "" Vector__XXX
 SG_ Quality : 4|2@1+ (1,0) [0|3] "" Vector__XXX
 SG_ Lane_type : 0|4@1+ (1,0) [0|15] "" Vector__XXX

BO_ 1851 Obstacle_Data_C: 8 AF01A
 SG_ Obstacle_Angle : 48|16@1- (0.01,0) [-327.68|327.68] "degree" Vector__XXX
 SG_ Obstacle_Replaced : 44|1@1+ (1,0) [0|1] "" Vector__XXX
 SG_ Object_Accel_X : 32|10@1- (0.03,0) [-14.97|14.97] "m/s^2" Vector__XXX
 SG_ Obstacle_Scale_Change : 16|16@1- (0.0002,0) [-6.5532|6.5532] "pix/sec" Vector__XXX
 SG_ Obstacle_Angle_Rate : 0|16@1- (0.01,0) [-327.68|327.68] "degree" Vector__XXX

BO_ 1850 Obstacle_Data_B: 8 AF01A
 SG_ Matched_Radar_ID : 56|7@1+ (1,0) [0|127] "" Vector__XXX
 SG_ Radar_Match_Confidence : 52|3@1+ (1,0) [0.5|5] "" Vector__XXX
 SG_ CIPV_Flag : 26|1@1+ (1,0) [0|1] "Enum" Vector__XXX
 SG_ Obstacle_Lane : 24|2@1+ (1,0) [0|3] "Enum" Vector__XXX
 SG_ Radar_Vel_X : 40|12@1- (0.0625,0) [-127.93|127.93] "meter/sec" Vector__XXX
 SG_ Radar_Pos_X : 28|12@1+ (0.0625,0) [0|250] "meter" Vector__XXX
 SG_ Obstacle_Age : 16|8@1+ (1,0) [0|255] "" Vector__XXX
 SG_ Obstacle_Width : 8|8@1+ (0.05,0) [0|12.5] "meter" Vector__XXX
 SG_ Obstacle_Legnth : 0|8@1+ (0.5,0) [0|31] "meter" Vector__XXX

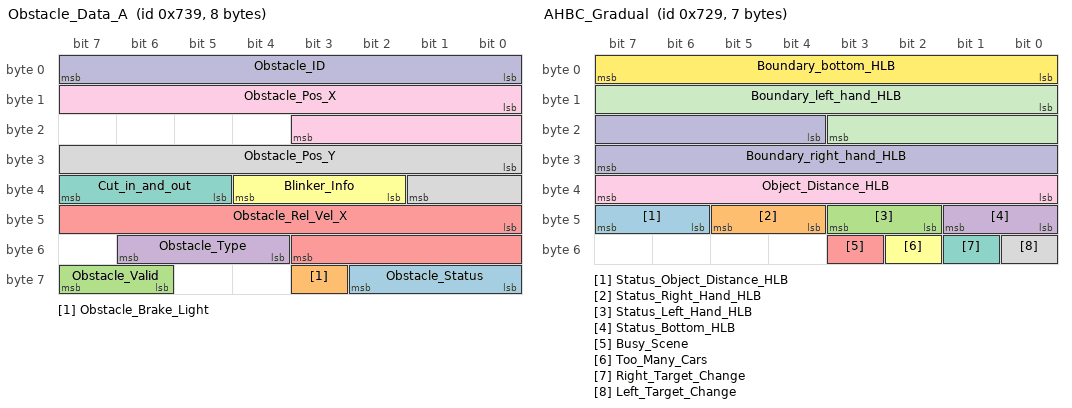
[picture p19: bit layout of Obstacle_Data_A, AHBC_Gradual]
BO_ 1849 Obstacle_Data_A: 8 AF01A
 SG_ Obstacle_Status : 56|3@1+ (1,0) [0|7] "" Vector__XXX
 SG_ Obstacle_Brake_Light : 59|1@1+ (1,0) [0|1] "" Vector__XXX
 SG_ Obstacle_Valid : 62|2@1+ (1,0) [0|3] "" Vector__XXX
 SG_ Obstacle_Type : 52|3@1+ (1,0) [0|7] "" Vector__XXX
 SG_ Obstacle_Rel_Vel_X : 40|12@1- (0.0625,0) [-127.93|127.93] "meter/sec" Vector__XXX
 SG_ Blinker_Info : 34|3@1+ (1,0) [0|7] "" Vector__XXX
 SG_ Cut_in_and_out : 37|3@1+ (1,0) [0|7] "" Vector__XXX
 SG_ Obstacle_Pos_Y : 24|10@1- (0.0625,0) [-31.93|31.93] "m" Vector__XXX
 SG_ Obstacle_Pos_X : 8|12@1+ (0.0625,0) [0|250] "meter" Vector__XXX
 SG_ Obstacle_ID : 0|8@1+ (1,0) [0|63] "" Vector__XXX

BO_ 1848 Obstacle_Status: 6 AF01A
 SG_ Close_Car : 40|1@1+ (1,0) [0|1] "" Vector__XXX
 SG_ Failsafe : 41|4@1+ (1,0) [0|7] "" Vector__XXX
 SG_ Protocol_Version : 32|8@1+ (1,0) [0|255] "" Vector__XXX
 SG_ Active_Version_Number_Section : 24|2@1+ (1,0) [0|3] "" Vector__XXX
 SG_ Left_close_rang_cut_in : 26|1@1+ (1,0) [0|1] "" Vector__XXX
 SG_ Right_close_rang_cut_in : 27|1@1+ (1,0) [0|1] "" Vector__XXX
 SG_ Go : 28|4@1+ (1,0) [0|15] "" Vector__XXX
 SG_ Application_Version : 16|8@1+ (1,0) [0|255] "" Vector__XXX
 SG_ Timestamp : 8|8@1+ (1,0) [0|255] "ms" Vector__XXX
 SG_ Num_Obstacles : 0|8@1+ (1,0) [0|255] "" Vector__XXX

BO_ 1847 Lane: 8 AF01A
 SG_ Lane_Curvature : 0|16@1- (3.81E-006,0) [-0.12|0.12] "l/m" Vector__XXX
 SG_ Pitch_Angle : 48|16@1+ (1.91E-006,-0.06249809) [-0.05|0.05] "radians" Vector__XXX
 SG_ Yaw_Angle : 32|16@1+ (0.00097656,-31.999) [-31.999|31.9998596] "radians" Vector__XXX
 SG_ CA : 28|1@1+ (1,0) [0|1] "" Vector__XXX
 SG_ Right_LDW_Availability : 29|1@1+ (1,0) [0|1] "" Vector__XXX
 SG_ Left_LDW_Availability : 30|1@1+ (1,0) [0|1] "" Vector__XXX
 SG_ Lane_Heading : 16|12@1- (0.0005,0) [-1|1] "" Vector__XXX

BO_ 1832 AHBC_high_low_beam: 3 AF01A
 SG_ Reasons_for_switch_to_low_beam : 8|9@1+ (1,0) [0|511] "" Vector__XXX
 SG_ Binary_high_low_beam_decision : 0|2@1+ (1,0) [0|3] "" Vector__XXX

BO_ 1824 TSR_message_A: 6 AF01A
 SG_ Sign_Position_Z : 32|8@1- (0.5,0) [-16|16] "meter" Vector__XXX
 SG_ Filter_Type : 40|8@1+ (1,0) [0|255] "" Vector__XXX
 SG_ Sign_Position_Y : 24|8@1- (0.5,0) [-32|31] "meter" Vector__XXX
 SG_ Sign_Position_X : 16|8@1+ (0.5,0) [0|122] "meter" Vector__XXX
 SG_ Supplementary_Sign_Type : 8|8@1+ (1,0) [0|255] "" Vector__XXX
 SG_ Vision_only_Sign_Type : 0|8@1+ (1,0) [0|255] "" Vector__XXX

BO_ 1831 Sign_Type: 8 AF01A
 SG_ Supplementary_Sign_Type_Display4 : 56|8@1+ (1,0) [0|255] "" Vector__XXX
 SG_ Supplementary_Sign_Type_Display3 : 40|8@1+ (1,0) [0|255] "" Vector__XXX
 SG_ Supplementary_Sign_Type_Display2 : 24|8@1+ (1,0) [0|255] "" Vector__XXX
 SG_ Supplementary_Sign_Type_Display1 : 8|8@1+ (1,0) [0|255] "" Vector__XXX
 SG_ Vision_only_Sign_Type_Display4 : 48|8@1+ (1,0) [0|255] "" Vector__XXX
 SG_ Vision_only_Sign_Type_Display3 : 32|8@1+ (1,0) [0|255] "" Vector__XXX
 SG_ Vision_only_Sign_Type_Display2 : 16|8@1+ (1,0) [0|255] "" Vector__XXX
 SG_ Vision_only_Sign_Type_Display1 : 0|8@1+ (1,0) [0|255] "" Vector__XXX

BO_ 1616 Fixed_FOE: 8 AF01A
 SG_ Fixed_Horizon : 32|32@1- (1,0) [-3.4E+038|3.4E+038] "" Vector__XXX
 SG_ Fixed_Yaw : 0|32@1- (1,0) [-3.4E+038|3.4E+038] "" Vector__XXX

BO_ 1792 C2_Display_and_warning: 8 AF01A
 SG_ Right_Crossing : 37|1@1+ (1,0) [0|1] "" Vector__XXX
 SG_ Left_Crossing : 36|1@1+ (1,0) [0|1] "" Vector__XXX
 SG_ Lanes_On : 32|1@1+ (1,0) [0|1] "" Vector__XXX
 SG_ Suppress : 7|1@1+ (1,0) [0|1] "" Vector__XXX
 SG_ Dusk_Time_Indicator : 3|1@1+ (1,0) [0|1] "" Vector__XXX
 SG_ Night_Time_Indicator : 4|1@1+ (1,0) [0|1] "" Vector__XXX
 SG_ Maintenanc : 38|1@1+ (1,0) [0|1] "" Vector__XXX
 SG_ Headway_Warning_Level : 56|2@1+ (1,0) [0|3] "" Vector__XXX
 SG_ Peds_FCW : 41|1@1+ (1,0) [0|1] "" Vector__XXX
 SG_ Peds_in_DZ : 42|1@1+ (1,0) [0|1] "" Vector__XXX
 SG_ Left_LDW_ON : 33|1@1+ (1,0) [0|1] "" Vector__XXX
 SG_ Right_LDW_ON : 34|1@1+ (1,0) [0|1] "" Vector__XXX
 SG_ FCW_on : 35|1@1+ (1,0) [0|1] "" Vector__XXX
 SG_ Failsafe : 39|1@1+ (1,0) [0|1] "" Vector__XXX
 SG_ Headway_valid : 16|1@1+ (1,0) [0|1] "" Vector__XXX
 SG_ Headway_measurement : 17|7@1+ (0.1,0) [0|9.9] "0.1s" Vector__XXX
 SG_ Sound_type : 0|3@1+ (1,0) [0|1] "" Vector__XXX

BO_ 1833 AHBC_Gradual: 7 AF01A
 SG_ Status_Object_Distance_HLB : 46|2@1+ (1,0) [0|3] "" Vector__XXX
 SG_ Status_Right_Hand_HLB : 44|2@1+ (1,0) [0|3] "" Vector__XXX
 SG_ Status_Left_Hand_HLB : 42|2@1+ (1,0) [0|3] "" Vector__XXX
 SG_ Status_Bottom_HLB : 40|2@1+ (1,0) [0|3] "" Vector__XXX
 SG_ Busy_Scene : 51|1@1+ (1,0) [0|1] "" Vector__XXX
 SG_ Too_Many_Cars : 50|1@1+ (1,0) [0|1] "" Vector__XXX
 SG_ Right_Target_Change : 49|1@1+ (1,0) [0|1] "" Vector__XXX
 SG_ Left_Target_Change : 48|1@1+ (1,0) [0|1] "" Vector__XXX
 SG_ Object_Distance_HLB : 32|8@1+ (2,0) [0|400] "m" Vector__XXX
 SG_ Boundary_right_hand_HLB : 20|12@1+ (0.1,-20) [-20|20] "deg" Vector__XXX
 SG_ Boundary_left_hand_HLB : 8|12@1+ (0.1,-20) [-20|20] "deg" Vector__XXX
 SG_ Boundary_bottom_HLB : 0|8@1+ (0.1,-10) [-10|10] "deg" Vector__XXX

BO_TX_BU_ 1888 : Gen,AF01A;
BO_TX_BU_ 1641 : Gen,AF01A;
BO_TX_BU_ 1915 : Gen,AF01A;
BO_TX_BU_ 1914 : Gen,AF01A;
BO_TX_BU_ 1913 : Gen,AF01A;
BO_TX_BU_ 1912 : Gen,AF01A;
BO_TX_BU_ 1909 : Gen,AF01A;
BO_TX_BU_ 1908 : Gen,AF01A;
BO_TX_BU_ 1911 : Gen,AF01A;
BO_TX_BU_ 1910 : Gen,AF01A;
BO_TX_BU_ 1907 : Gen,AF01A;
BO_TX_BU_ 1906 : Gen,AF01A;
BO_TX_BU_ 1905 : Gen,AF01A;
BO_TX_BU_ 1904 : Gen,AF01A;
BO_TX_BU_ 1903 : Gen,AF01A;
BO_TX_BU_ 1902 : Gen,AF01A;
BO_TX_BU_ 1872 : Gen,AF01A;
BO_TX_BU_ 1869 : Gen,AF01A;
BO_TX_BU_ 1866 : Gen,AF01A;
BO_TX_BU_ 1863 : Gen,AF01A;
BO_TX_BU_ 1860 : Gen,AF01A;
BO_TX_BU_ 1857 : Gen,AF01A;
BO_TX_BU_ 1854 : Gen,AF01A;
BO_TX_BU_ 1871 : Gen,AF01A;
BO_TX_BU_ 1868 : Gen,AF01A;
BO_TX_BU_ 1865 : Gen,AF01A;
BO_TX_BU_ 1862 : Gen,AF01A;
BO_TX_BU_ 1859 : Gen,AF01A;
BO_TX_BU_ 1856 : Gen,AF01A;
BO_TX_BU_ 1853 : Gen,AF01A;
BO_TX_BU_ 1870 : Gen,AF01A;
BO_TX_BU_ 1867 : Gen,AF01A;
BO_TX_BU_ 1864 : Gen,AF01A;
BO_TX_BU_ 1861 : Gen,AF01A;
BO_TX_BU_ 1858 : Gen,AF01A;
BO_TX_BU_ 1855 : Gen,AF01A;
BO_TX_BU_ 1852 : Gen,AF01A;
BO_TX_BU_ 1830 : Gen,AF01A;
BO_TX_BU_ 1829 : Gen,AF01A;
BO_TX_BU_ 1828 : Gen,AF01A;
BO_TX_BU_ 1827 : Gen,AF01A;
BO_TX_BU_ 1826 : Gen,AF01A;
BO_TX_BU_ 1825 : Gen,AF01A;
BO_TX_BU_ 1898 : Gen,AF01A;
BO_TX_BU_ 1899 : Gen,AF01A;
BO_TX_BU_ 1901 : Gen,AF01A;
BO_TX_BU_ 1900 : Gen,AF01A;
BO_TX_BU_ 1897 : Gen,AF01A;
BO_TX_BU_ 1896 : Gen,AF01A;
BO_TX_BU_ 1895 : Gen,AF01A;
BO_TX_BU_ 1894 : Gen,AF01A;
BO_TX_BU_ 1851 : Gen,AF01A;
BO_TX_BU_ 1850 : Gen,AF01A;
BO_TX_BU_ 1849 : Gen,AF01A;
BO_TX_BU_ 1848 : Gen,AF01A;
BO_TX_BU_ 1847 : Gen,AF01A;
BO_TX_BU_ 1832 : Gen,AF01A;
BO_TX_BU_ 1824 : Gen,AF01A;
BO_TX_BU_ 1831 : Gen,AF01A;
BO_TX_BU_ 1616 : Gen,AF01A;
BO_TX_BU_ 1792 : Gen,AF01A;
BO_TX_BU_ 1833 : Gen,AF01A;
BA_DEF_ SG_  "GenSigSendType" ENUM  "Cyclic","OnWrite","OnWriteWithRepetition","OnChange","OnChangeWithRepetition","IfActive","IfActiveWithRepetition","NoSigSendType";
BA_DEF_ BO_  "GenMsgSendType" ENUM  "Cyclic","not_used","not_used","not_used","not_used","not_used","not_used","IfActive","NoMsgSendType";
BA_DEF_ BO_  "GenMsgNrOfRepetition" INT 0 100;
BA_DEF_ BO_  "GenMsgILSupport" ENUM  "No","Yes";
BA_DEF_ BO_  "GenMsgCycleTimeFast" INT 0 100000;
BA_DEF_ BO_  "GenMsgCycleTime" INT 0 10000;
BA_DEF_REL_ BU_SG_REL_  "GenSigTimeoutTime" INT 0 65535;
BA_DEF_DEF_  "GenSigSendType" "Cyclic";
BA_DEF_DEF_  "GenMsgSendType" "Cyclic";
BA_DEF_DEF_  "GenMsgNrOfRepetition" 0;
BA_DEF_DEF_  "GenMsgILSupport" "Yes";
BA_DEF_DEF_  "GenMsgCycleTimeFast" 0;
BA_DEF_DEF_  "GenMsgCycleTime" 0;
BA_DEF_DEF_REL_ "GenSigTimeoutTime" 0;
BA_ "GenMsgCycleTime" BO_ 1888 100;
BA_ "GenMsgCycleTime" BO_ 1641 100;
BA_ "GenMsgCycleTime" BO_ 1915 100;
BA_ "GenMsgCycleTime" BO_ 1914 100;
BA_ "GenMsgCycleTime" BO_ 1913 100;
BA_ "GenMsgCycleTime" BO_ 1912 100;
BA_ "GenMsgCycleTime" BO_ 1909 100;
BA_ "GenMsgCycleTime" BO_ 1908 100;
BA_ "GenMsgCycleTime" BO_ 1911 100;
BA_ "GenMsgCycleTime" BO_ 1910 100;
BA_ "GenMsgCycleTime" BO_ 1907 100;
BA_ "GenMsgCycleTime" BO_ 1906 100;
BA_ "GenMsgCycleTime" BO_ 1905 100;
BA_ "GenMsgCycleTime" BO_ 1904 100;
BA_ "GenMsgCycleTime" BO_ 1903 100;
BA_ "GenMsgCycleTime" BO_ 1902 100;
BA_ "GenMsgCycleTime" BO_ 1872 100;
BA_ "GenMsgCycleTime" BO_ 1869 100;
BA_ "GenMsgCycleTime" BO_ 1866 100;
BA_ "GenMsgCycleTime" BO_ 1863 100;
BA_ "GenMsgCycleTime" BO_ 1860 100;
BA_ "GenMsgCycleTime" BO_ 1857 100;
BA_ "GenMsgCycleTime" BO_ 1854 100;
BA_ "GenMsgCycleTime" BO_ 1871 100;
BA_ "GenMsgCycleTime" BO_ 1868 100;
BA_ "GenMsgCycleTime" BO_ 1865 100;
BA_ "GenMsgCycleTime" BO_ 1862 100;
BA_ "GenMsgCycleTime" BO_ 1859 100;
BA_ "GenMsgCycleTime" BO_ 1856 100;
BA_ "GenMsgCycleTime" BO_ 1853 100;
BA_ "GenMsgCycleTime" BO_ 1870 100;
BA_ "GenMsgCycleTime" BO_ 1867 100;
BA_ "GenMsgCycleTime" BO_ 1864 100;
BA_ "GenMsgCycleTime" BO_ 1861 100;
BA_ "GenMsgCycleTime" BO_ 1858 100;
BA_ "GenMsgCycleTime" BO_ 1855 100;
BA_ "GenMsgCycleTime" BO_ 1852 100;
BA_ "GenMsgCycleTime" BO_ 1830 100;
BA_ "GenMsgCycleTime" BO_ 1829 100;
BA_ "GenMsgCycleTime" BO_ 1828 100;
BA_ "GenMsgCycleTime" BO_ 1827 100;
BA_ "GenMsgCycleTime" BO_ 1826 100;
BA_ "GenMsgCycleTime" BO_ 1825 100;
BA_ "GenMsgCycleTime" BO_ 1898 100;
BA_ "GenMsgCycleTime" BO_ 1899 100;
BA_ "GenMsgCycleTime" BO_ 1901 100;
BA_ "GenMsgCycleTime" BO_ 1900 100;
BA_ "GenMsgCycleTime" BO_ 1897 100;
BA_ "GenMsgCycleTime" BO_ 1896 100;
BA_ "GenMsgCycleTime" BO_ 1895 100;
BA_ "GenMsgCycleTime" BO_ 1894 100;
BA_ "GenMsgCycleTime" BO_ 1851 100;
BA_ "GenMsgCycleTime" BO_ 1850 100;
BA_ "GenMsgCycleTime" BO_ 1849 100;
BA_ "GenMsgCycleTime" BO_ 1848 100;
BA_ "GenMsgCycleTime" BO_ 1847 100;
BA_ "GenMsgCycleTime" BO_ 1832 100;
BA_ "GenMsgCycleTime" BO_ 1824 100;
BA_ "GenMsgCycleTime" BO_ 1831 100;
BA_ "GenMsgCycleTime" BO_ 1616 100;
BA_ "GenMsgCycleTime" BO_ 1792 100;
BA_ "GenMsgCycleTime" BO_ 1833 100;
BA_REL_ "GenSigTimeoutTime" BU_SG_REL_ AF01A SG_ 1306 CAN_TX_TRACK_WIDTH 60;
BA_REL_ "GenSigTimeoutTime" BU_SG_REL_ AF01A SG_ 1306 CAN_TX_TRACK_STATUS 60;
BA_REL_ "GenSigTimeoutTime" BU_SG_REL_ AF01A SG_ 1306 CAN_TX_TRACK_ROLLING_COUNT 60;
BA_REL_ "GenSigTimeoutTime" BU_SG_REL_ AF01A SG_ 1306 CAN_TX_TRACK_RANGE_RATE 60;
BA_REL_ "GenSigTimeoutTime" BU_SG_REL_ AF01A SG_ 1306 CAN_TX_TRACK_RANGE_ACCEL 60;
BA_REL_ "GenSigTimeoutTime" BU_SG_REL_ AF01A SG_ 1306 CAN_TX_TRACK_RANGE 60;
BA_REL_ "GenSigTimeoutTime" BU_SG_REL_ AF01A SG_ 1306 CAN_TX_TRACK_ONCOMING 60;
BA_REL_ "GenSigTimeoutTime" BU_SG_REL_ AF01A SG_ 1306 CAN_TX_TRACK_MED_RANGE_MODE 60;
BA_REL_ "GenSigTimeoutTime" BU_SG_REL_ AF01A SG_ 1306 CAN_TX_TRACK_LAT_RATE 60;
BA_REL_ "GenSigTimeoutTime" BU_SG_REL_ AF01A SG_ 1306 CAN_TX_TRACK_GROUPING_CHANGED 60;
BA_REL_ "GenSigTimeoutTime" BU_SG_REL_ AF01A SG_ 1306 CAN_TX_TRACK_BRIDGE_OBJECT 60;
BA_REL_ "GenSigTimeoutTime" BU_SG_REL_ AF01A SG_ 1306 CAN_TX_TRACK_ANGLE 60;
BA_REL_ "GenSigTimeoutTime" BU_SG_REL_ AF01A SG_ 1305 CAN_TX_TRACK_WIDTH 60;
BA_REL_ "GenSigTimeoutTime" BU_SG_REL_ AF01A SG_ 1305 CAN_TX_TRACK_STATUS 60;
BA_REL_ "GenSigTimeoutTime" BU_SG_REL_ AF01A SG_ 1305 CAN_TX_TRACK_ROLLING_COUNT 60;
BA_REL_ "GenSigTimeoutTime" BU_SG_REL_ AF01A SG_ 1305 CAN_TX_TRACK_RANGE_RATE 60;
BA_REL_ "GenSigTimeoutTime" BU_SG_REL_ AF01A SG_ 1305 CAN_TX_TRACK_RANGE_ACCEL 60;
BA_REL_ "GenSigTimeoutTime" BU_SG_REL_ AF01A SG_ 1305 CAN_TX_TRACK_RANGE 60;
BA_REL_ "GenSigTimeoutTime" BU_SG_REL_ AF01A SG_ 1305 CAN_TX_TRACK_ONCOMING 60;
BA_REL_ "GenSigTimeoutTime" BU_SG_REL_ AF01A SG_ 1305 CAN_TX_TRACK_MED_RANGE_MODE 60;
BA_REL_ "GenSigTimeoutTime" BU_SG_REL_ AF01A SG_ 1305 CAN_TX_TRACK_LAT_RATE 60;
BA_REL_ "GenSigTimeoutTime" BU_SG_REL_ AF01A SG_ 1305 CAN_TX_TRACK_GROUPING_CHANGED 60;
BA_REL_ "GenSigTimeoutTime" BU_SG_REL_ AF01A SG_ 1305 CAN_TX_TRACK_BRIDGE_OBJECT 60;
BA_REL_ "GenSigTimeoutTime" BU_SG_REL_ AF01A SG_ 1305 CAN_TX_TRACK_ANGLE 60;
BA_REL_ "GenSigTimeoutTime" BU_SG_REL_ AF01A SG_ 1304 CAN_TX_TRACK_WIDTH 60;
BA_REL_ "GenSigTimeoutTime" BU_SG_REL_ AF01A SG_ 1304 CAN_TX_TRACK_STATUS 60;
BA_REL_ "GenSigTimeoutTime" BU_SG_REL_ AF01A SG_ 1304 CAN_TX_TRACK_ROLLING_COUNT 60;
BA_REL_ "GenSigTimeoutTime" BU_SG_REL_ AF01A SG_ 1304 CAN_TX_TRACK_RANGE_RATE 60;
BA_REL_ "GenSigTimeoutTime" BU_SG_REL_ AF01A SG_ 1304 CAN_TX_TRACK_RANGE_ACCEL 60;
BA_REL_ "GenSigTimeoutTime" BU_SG_REL_ AF01A SG_ 1304 CAN_TX_TRACK_RANGE 60;
BA_REL_ "GenSigTimeoutTime" BU_SG_REL_ AF01A SG_ 1304 CAN_TX_TRACK_ONCOMING 60;
BA_REL_ "GenSigTimeoutTime" BU_SG_REL_ AF01A SG_ 1304 CAN_TX_TRACK_MED_RANGE_MODE 60;
BA_REL_ "GenSigTimeoutTime" BU_SG_REL_ AF01A SG_ 1304 CAN_TX_TRACK_LAT_RATE 60;
BA_REL_ "GenSigTimeoutTime" BU_SG_REL_ AF01A SG_ 1304 CAN_TX_TRACK_GROUPING_CHANGED 60;
BA_REL_ "GenSigTimeoutTime" BU_SG_REL_ AF01A SG_ 1304 CAN_TX_TRACK_BRIDGE_OBJECT 60;
BA_REL_ "GenSigTimeoutTime" BU_SG_REL_ AF01A SG_ 1304 CAN_TX_TRACK_ANGLE 60;
BA_REL_ "GenSigTimeoutTime" BU_SG_REL_ AF01A SG_ 1303 CAN_TX_TRACK_WIDTH 60;
BA_REL_ "GenSigTimeoutTime" BU_SG_REL_ AF01A SG_ 1303 CAN_TX_TRACK_STATUS 60;
BA_REL_ "GenSigTimeoutTime" BU_SG_REL_ AF01A SG_ 1303 CAN_TX_TRACK_ROLLING_COUNT 60;
BA_REL_ "GenSigTimeoutTime" BU_SG_REL_ AF01A SG_ 1303 CAN_TX_TRACK_RANGE_RATE 60;
BA_REL_ "GenSigTimeoutTime" BU_SG_REL_ AF01A SG_ 1303 CAN_TX_TRACK_RANGE_ACCEL 60;
BA_REL_ "GenSigTimeoutTime" BU_SG_REL_ AF01A SG_ 1303 CAN_TX_TRACK_RANGE 60;
BA_REL_ "GenSigTimeoutTime" BU_SG_REL_ AF01A SG_ 1303 CAN_TX_TRACK_ONCOMING 60;
BA_REL_ "GenSigTimeoutTime" BU_SG_REL_ AF01A SG_ 1303 CAN_TX_TRACK_MED_RANGE_MODE 60;
BA_REL_ "GenSigTimeoutTime" BU_SG_REL_ AF01A SG_ 1303 CAN_TX_TRACK_LAT_RATE 60;
BA_REL_ "GenSigTimeoutTime" BU_SG_REL_ AF01A SG_ 1303 CAN_TX_TRACK_GROUPING_CHANGED 60;
BA_REL_ "GenSigTimeoutTime" BU_SG_REL_ AF01A SG_ 1303 CAN_TX_TRACK_BRIDGE_OBJECT 60;
BA_REL_ "GenSigTimeoutTime" BU_SG_REL_ AF01A SG_ 1303 CAN_TX_TRACK_ANGLE 60;
BA_REL_ "GenSigTimeoutTime" BU_SG_REL_ AF01A SG_ 1302 CAN_TX_TRACK_WIDTH 60;
BA_REL_ "GenSigTimeoutTime" BU_SG_REL_ AF01A SG_ 1302 CAN_TX_TRACK_STATUS 60;
BA_REL_ "GenSigTimeoutTime" BU_SG_REL_ AF01A SG_ 1302 CAN_TX_TRACK_ROLLING_COUNT 60;
BA_REL_ "GenSigTimeoutTime" BU_SG_REL_ AF01A SG_ 1302 CAN_TX_TRACK_RANGE_RATE 60;
BA_REL_ "GenSigTimeoutTime" BU_SG_REL_ AF01A SG_ 1302 CAN_TX_TRACK_RANGE_ACCEL 60;
BA_REL_ "GenSigTimeoutTime" BU_SG_REL_ AF01A SG_ 1302 CAN_TX_TRACK_RANGE 60;
BA_REL_ "GenSigTimeoutTime" BU_SG_REL_ AF01A SG_ 1302 CAN_TX_TRACK_ONCOMING 60;
BA_REL_ "GenSigTimeoutTime" BU_SG_REL_ AF01A SG_ 1302 CAN_TX_TRACK_MED_RANGE_MODE 60;
BA_REL_ "GenSigTimeoutTime" BU_SG_REL_ AF01A SG_ 1302 CAN_TX_TRACK_LAT_RATE 60;
BA_REL_ "GenSigTimeoutTime" BU_SG_REL_ AF01A SG_ 1302 CAN_TX_TRACK_GROUPING_CHANGED 60;
BA_REL_ "GenSigTimeoutTime" BU_SG_REL_ AF01A SG_ 1302 CAN_TX_TRACK_BRIDGE_OBJECT 60;
BA_REL_ "GenSigTimeoutTime" BU_SG_REL_ AF01A SG_ 1302 CAN_TX_TRACK_ANGLE 60;
BA_REL_ "GenSigTimeoutTime" BU_SG_REL_ AF01A SG_ 1301 CAN_TX_TRACK_WIDTH 60;
BA_REL_ "GenSigTimeoutTime" BU_SG_REL_ AF01A SG_ 1301 CAN_TX_TRACK_STATUS 60;
BA_REL_ "GenSigTimeoutTime" BU_SG_REL_ AF01A SG_ 1301 CAN_TX_TRACK_ROLLING_COUNT 60;
BA_REL_ "GenSigTimeoutTime" BU_SG_REL_ AF01A SG_ 1301 CAN_TX_TRACK_RANGE_RATE 60;
BA_REL_ "GenSigTimeoutTime" BU_SG_REL_ AF01A SG_ 1301 CAN_TX_TRACK_RANGE_ACCEL 60;
BA_REL_ "GenSigTimeoutTime" BU_SG_REL_ AF01A SG_ 1301 CAN_TX_TRACK_RANGE 60;
BA_REL_ "GenSigTimeoutTime" BU_SG_REL_ AF01A SG_ 1301 CAN_TX_TRACK_ONCOMING 60;
BA_REL_ "GenSigTimeoutTime" BU_SG_REL_ AF01A SG_ 1301 CAN_TX_TRACK_MED_RANGE_MODE 60;
BA_REL_ "GenSigTimeoutTime" BU_SG_REL_ AF01A SG_ 1301 CAN_TX_TRACK_LAT_RATE 60;
BA_REL_ "GenSigTimeoutTime" BU_SG_REL_ AF01A SG_ 1301 CAN_TX_TRACK_GROUPING_CHANGED 60;
BA_REL_ "GenSigTimeoutTime" BU_SG_REL_ AF01A SG_ 1301 CAN_TX_TRACK_BRIDGE_OBJECT 60;
BA_REL_ "GenSigTimeoutTime" BU_SG_REL_ AF01A SG_ 1301 CAN_TX_TRACK_ANGLE 60;
BA_REL_ "GenSigTimeoutTime" BU_SG_REL_ AF01A SG_ 1300 CAN_TX_TRACK_WIDTH 60;
BA_REL_ "GenSigTimeoutTime" BU_SG_REL_ AF01A SG_ 1300 CAN_TX_TRACK_STATUS 60;
BA_REL_ "GenSigTimeoutTime" BU_SG_REL_ AF01A SG_ 1300 CAN_TX_TRACK_ROLLING_COUNT 60;
BA_REL_ "GenSigTimeoutTime" BU_SG_REL_ AF01A SG_ 1300 CAN_TX_TRACK_RANGE_RATE 60;
BA_REL_ "GenSigTimeoutTime" BU_SG_REL_ AF01A SG_ 1300 CAN_TX_TRACK_RANGE_ACCEL 60;
BA_REL_ "GenSigTimeoutTime" BU_SG_REL_ AF01A SG_ 1300 CAN_TX_TRACK_RANGE 60;
BA_REL_ "GenSigTimeoutTime" BU_SG_REL_ AF01A SG_ 1300 CAN_TX_TRACK_ONCOMING 60;
BA_REL_ "GenSigTimeoutTime" BU_SG_REL_ AF01A SG_ 1300 CAN_TX_TRACK_MED_RANGE_MODE 60;
BA_REL_ "GenSigTimeoutTime" BU_SG_REL_ AF01A SG_ 1300 CAN_TX_TRACK_LAT_RATE 60;
BA_REL_ "GenSigTimeoutTime" BU_SG_REL_ AF01A SG_ 1300 CAN_TX_TRACK_GROUPING_CHANGED 60;
BA_REL_ "GenSigTimeoutTime" BU_SG_REL_ AF01A SG_ 1300 CAN_TX_TRACK_BRIDGE_OBJECT 60;
BA_REL_ "GenSigTimeoutTime" BU_SG_REL_ AF01A SG_ 1300 CAN_TX_TRACK_ANGLE 60;
BA_REL_ "GenSigTimeoutTime" BU_SG_REL_ AF01A SG_ 1299 CAN_TX_TRACK_WIDTH 60;
BA_REL_ "GenSigTimeoutTime" BU_SG_REL_ AF01A SG_ 1299 CAN_TX_TRACK_STATUS 60;
BA_REL_ "GenSigTimeoutTime" BU_SG_REL_ AF01A SG_ 1299 CAN_TX_TRACK_ROLLING_COUNT 60;
BA_REL_ "GenSigTimeoutTime" BU_SG_REL_ AF01A SG_ 1299 CAN_TX_TRACK_RANGE_RATE 60;
BA_REL_ "GenSigTimeoutTime" BU_SG_REL_ AF01A SG_ 1299 CAN_TX_TRACK_RANGE_ACCEL 60;
BA_REL_ "GenSigTimeoutTime" BU_SG_REL_ AF01A SG_ 1299 CAN_TX_TRACK_RANGE 60;
BA_REL_ "GenSigTimeoutTime" BU_SG_REL_ AF01A SG_ 1299 CAN_TX_TRACK_ONCOMING 60;
BA_REL_ "GenSigTimeoutTime" BU_SG_REL_ AF01A SG_ 1299 CAN_TX_TRACK_MED_RANGE_MODE 60;
BA_REL_ "GenSigTimeoutTime" BU_SG_REL_ AF01A SG_ 1299 CAN_TX_TRACK_LAT_RATE 60;
BA_REL_ "GenSigTimeoutTime" BU_SG_REL_ AF01A SG_ 1299 CAN_TX_TRACK_GROUPING_CHANGED 60;
BA_REL_ "GenSigTimeoutTime" BU_SG_REL_ AF01A SG_ 1299 CAN_TX_TRACK_BRIDGE_OBJECT 60;
BA_REL_ "GenSigTimeoutTime" BU_SG_REL_ AF01A SG_ 1299 CAN_TX_TRACK_ANGLE 60;
BA_REL_ "GenSigTimeoutTime" BU_SG_REL_ AF01A SG_ 1298 CAN_TX_TRACK_WIDTH 60;
BA_REL_ "GenSigTimeoutTime" BU_SG_REL_ AF01A SG_ 1298 CAN_TX_TRACK_STATUS 60;
BA_REL_ "GenSigTimeoutTime" BU_SG_REL_ AF01A SG_ 1298 CAN_TX_TRACK_ROLLING_COUNT 60;
BA_REL_ "GenSigTimeoutTime" BU_SG_REL_ AF01A SG_ 1298 CAN_TX_TRACK_RANGE_RATE 60;
BA_REL_ "GenSigTimeoutTime" BU_SG_REL_ AF01A SG_ 1298 CAN_TX_TRACK_RANGE_ACCEL 60;
BA_REL_ "GenSigTimeoutTime" BU_SG_REL_ AF01A SG_ 1298 CAN_TX_TRACK_RANGE 60;
BA_REL_ "GenSigTimeoutTime" BU_SG_REL_ AF01A SG_ 1298 CAN_TX_TRACK_ONCOMING 60;
BA_REL_ "GenSigTimeoutTime" BU_SG_REL_ AF01A SG_ 1298 CAN_TX_TRACK_MED_RANGE_MODE 60;
BA_REL_ "GenSigTimeoutTime" BU_SG_REL_ AF01A SG_ 1298 CAN_TX_TRACK_LAT_RATE 60;
BA_REL_ "GenSigTimeoutTime" BU_SG_REL_ AF01A SG_ 1298 CAN_TX_TRACK_GROUPING_CHANGED 60;
BA_REL_ "GenSigTimeoutTime" BU_SG_REL_ AF01A SG_ 1298 CAN_TX_TRACK_BRIDGE_OBJECT 60;
BA_REL_ "GenSigTimeoutTime" BU_SG_REL_ AF01A SG_ 1298 CAN_TX_TRACK_ANGLE 60;
BA_REL_ "GenSigTimeoutTime" BU_SG_REL_ AF01A SG_ 1297 CAN_TX_TRACK_WIDTH 60;
BA_REL_ "GenSigTimeoutTime" BU_SG_REL_ AF01A SG_ 1297 CAN_TX_TRACK_STATUS 60;
BA_REL_ "GenSigTimeoutTime" BU_SG_REL_ AF01A SG_ 1297 CAN_TX_TRACK_ROLLING_COUNT 60;
BA_REL_ "GenSigTimeoutTime" BU_SG_REL_ AF01A SG_ 1297 CAN_TX_TRACK_RANGE_RATE 60;
BA_REL_ "GenSigTimeoutTime" BU_SG_REL_ AF01A SG_ 1297 CAN_TX_TRACK_RANGE_ACCEL 60;
BA_REL_ "GenSigTimeoutTime" BU_SG_REL_ AF01A SG_ 1297 CAN_TX_TRACK_RANGE 60;
BA_REL_ "GenSigTimeoutTime" BU_SG_REL_ AF01A SG_ 1297 CAN_TX_TRACK_ONCOMING 60;
BA_REL_ "GenSigTimeoutTime" BU_SG_REL_ AF01A SG_ 1297 CAN_TX_TRACK_MED_RANGE_MODE 60;
BA_REL_ "GenSigTimeoutTime" BU_SG_REL_ AF01A SG_ 1297 CAN_TX_TRACK_LAT_RATE 60;
BA_REL_ "GenSigTimeoutTime" BU_SG_REL_ AF01A SG_ 1297 CAN_TX_TRACK_GROUPING_CHANGED 60;
BA_REL_ "GenSigTimeoutTime" BU_SG_REL_ AF01A SG_ 1297 CAN_TX_TRACK_BRIDGE_OBJECT 60;
BA_REL_ "GenSigTimeoutTime" BU_SG_REL_ AF01A SG_ 1297 CAN_TX_TRACK_ANGLE 60;
BA_REL_ "GenSigTimeoutTime" BU_SG_REL_ AF01A SG_ 1296 CAN_TX_TRACK_WIDTH 60;
BA_REL_ "GenSigTimeoutTime" BU_SG_REL_ AF01A SG_ 1296 CAN_TX_TRACK_STATUS 60;
BA_REL_ "GenSigTimeoutTime" BU_SG_REL_ AF01A SG_ 1296 CAN_TX_TRACK_ROLLING_COUNT 60;
BA_REL_ "GenSigTimeoutTime" BU_SG_REL_ AF01A SG_ 1296 CAN_TX_TRACK_RANGE_RATE 60;
BA_REL_ "GenSigTimeoutTime" BU_SG_REL_ AF01A SG_ 1296 CAN_TX_TRACK_RANGE_ACCEL 60;
BA_REL_ "GenSigTimeoutTime" BU_SG_REL_ AF01A SG_ 1296 CAN_TX_TRACK_RANGE 60;
BA_REL_ "GenSigTimeoutTime" BU_SG_REL_ AF01A SG_ 1296 CAN_TX_TRACK_ONCOMING 60;
BA_REL_ "GenSigTimeoutTime" BU_SG_REL_ AF01A SG_ 1296 CAN_TX_TRACK_MED_RANGE_MODE 60;
BA_REL_ "GenSigTimeoutTime" BU_SG_REL_ AF01A SG_ 1296 CAN_TX_TRACK_LAT_RATE 60;
BA_REL_ "GenSigTimeoutTime" BU_SG_REL_ AF01A SG_ 1296 CAN_TX_TRACK_GROUPING_CHANGED 60;
BA_REL_ "GenSigTimeoutTime" BU_SG_REL_ AF01A SG_ 1296 CAN_TX_TRACK_BRIDGE_OBJECT 60;
BA_REL_ "GenSigTimeoutTime" BU_SG_REL_ AF01A SG_ 1296 CAN_TX_TRACK_ANGLE 60;
BA_REL_ "GenSigTimeoutTime" BU_SG_REL_ AF01A SG_ 1295 CAN_TX_TRACK_WIDTH 60;
BA_REL_ "GenSigTimeoutTime" BU_SG_REL_ AF01A SG_ 1295 CAN_TX_TRACK_STATUS 60;
BA_REL_ "GenSigTimeoutTime" BU_SG_REL_ AF01A SG_ 1295 CAN_TX_TRACK_ROLLING_COUNT 60;
BA_REL_ "GenSigTimeoutTime" BU_SG_REL_ AF01A SG_ 1295 CAN_TX_TRACK_RANGE_RATE 60;
BA_REL_ "GenSigTimeoutTime" BU_SG_REL_ AF01A SG_ 1295 CAN_TX_TRACK_RANGE_ACCEL 60;
BA_REL_ "GenSigTimeoutTime" BU_SG_REL_ AF01A SG_ 1295 CAN_TX_TRACK_RANGE 60;
BA_REL_ "GenSigTimeoutTime" BU_SG_REL_ AF01A SG_ 1295 CAN_TX_TRACK_ONCOMING 60;
BA_REL_ "GenSigTimeoutTime" BU_SG_REL_ AF01A SG_ 1295 CAN_TX_TRACK_MED_RANGE_MODE 60;
BA_REL_ "GenSigTimeoutTime" BU_SG_REL_ AF01A SG_ 1295 CAN_TX_TRACK_LAT_RATE 60;
BA_REL_ "GenSigTimeoutTime" BU_SG_REL_ AF01A SG_ 1295 CAN_TX_TRACK_GROUPING_CHANGED 60;
BA_REL_ "GenSigTimeoutTime" BU_SG_REL_ AF01A SG_ 1295 CAN_TX_TRACK_BRIDGE_OBJECT 60;
BA_REL_ "GenSigTimeoutTime" BU_SG_REL_ AF01A SG_ 1295 CAN_TX_TRACK_ANGLE 60;
BA_REL_ "GenSigTimeoutTime" BU_SG_REL_ AF01A SG_ 1294 CAN_TX_TRACK_WIDTH 60;
BA_REL_ "GenSigTimeoutTime" BU_SG_REL_ AF01A SG_ 1294 CAN_TX_TRACK_STATUS 60;
BA_REL_ "GenSigTimeoutTime" BU_SG_REL_ AF01A SG_ 1294 CAN_TX_TRACK_ROLLING_COUNT 60;
BA_REL_ "GenSigTimeoutTime" BU_SG_REL_ AF01A SG_ 1294 CAN_TX_TRACK_RANGE_RATE 60;
BA_REL_ "GenSigTimeoutTime" BU_SG_REL_ AF01A SG_ 1294 CAN_TX_TRACK_RANGE_ACCEL 60;
BA_REL_ "GenSigTimeoutTime" BU_SG_REL_ AF01A SG_ 1294 CAN_TX_TRACK_RANGE 60;
BA_REL_ "GenSigTimeoutTime" BU_SG_REL_ AF01A SG_ 1294 CAN_TX_TRACK_ONCOMING 60;
BA_REL_ "GenSigTimeoutTime" BU_SG_REL_ AF01A SG_ 1294 CAN_TX_TRACK_MED_RANGE_MODE 60;
BA_REL_ "GenSigTimeoutTime" BU_SG_REL_ AF01A SG_ 1294 CAN_TX_TRACK_LAT_RATE 60;
BA_REL_ "GenSigTimeoutTime" BU_SG_REL_ AF01A SG_ 1294 CAN_TX_TRACK_GROUPING_CHANGED 60;
BA_REL_ "GenSigTimeoutTime" BU_SG_REL_ AF01A SG_ 1294 CAN_TX_TRACK_BRIDGE_OBJECT 60;
BA_REL_ "GenSigTimeoutTime" BU_SG_REL_ AF01A SG_ 1294 CAN_TX_TRACK_ANGLE 60;
BA_REL_ "GenSigTimeoutTime" BU_SG_REL_ AF01A SG_ 1293 CAN_TX_TRACK_WIDTH 60;
BA_REL_ "GenSigTimeoutTime" BU_SG_REL_ AF01A SG_ 1293 CAN_TX_TRACK_STATUS 60;
BA_REL_ "GenSigTimeoutTime" BU_SG_REL_ AF01A SG_ 1293 CAN_TX_TRACK_ROLLING_COUNT 60;
BA_REL_ "GenSigTimeoutTime" BU_SG_REL_ AF01A SG_ 1293 CAN_TX_TRACK_RANGE_RATE 60;
BA_REL_ "GenSigTimeoutTime" BU_SG_REL_ AF01A SG_ 1293 CAN_TX_TRACK_RANGE_ACCEL 60;
BA_REL_ "GenSigTimeoutTime" BU_SG_REL_ AF01A SG_ 1293 CAN_TX_TRACK_RANGE 60;
BA_REL_ "GenSigTimeoutTime" BU_SG_REL_ AF01A SG_ 1293 CAN_TX_TRACK_ONCOMING 60;
BA_REL_ "GenSigTimeoutTime" BU_SG_REL_ AF01A SG_ 1293 CAN_TX_TRACK_MED_RANGE_MODE 60;
BA_REL_ "GenSigTimeoutTime" BU_SG_REL_ AF01A SG_ 1293 CAN_TX_TRACK_LAT_RATE 60;
BA_REL_ "GenSigTimeoutTime" BU_SG_REL_ AF01A SG_ 1293 CAN_TX_TRACK_GROUPING_CHANGED 60;
BA_REL_ "GenSigTimeoutTime" BU_SG_REL_ AF01A SG_ 1293 CAN_TX_TRACK_BRIDGE_OBJECT 60;
BA_REL_ "GenSigTimeoutTime" BU_SG_REL_ AF01A SG_ 1293 CAN_TX_TRACK_ANGLE 60;
BA_REL_ "GenSigTimeoutTime" BU_SG_REL_ AF01A SG_ 1292 CAN_TX_TRACK_WIDTH 60;
BA_REL_ "GenSigTimeoutTime" BU_SG_REL_ AF01A SG_ 1292 CAN_TX_TRACK_STATUS 60;
BA_REL_ "GenSigTimeoutTime" BU_SG_REL_ AF01A SG_ 1292 CAN_TX_TRACK_ROLLING_COUNT 60;
BA_REL_ "GenSigTimeoutTime" BU_SG_REL_ AF01A SG_ 1292 CAN_TX_TRACK_RANGE_RATE 60;
BA_REL_ "GenSigTimeoutTime" BU_SG_REL_ AF01A SG_ 1292 CAN_TX_TRACK_RANGE_ACCEL 60;
BA_REL_ "GenSigTimeoutTime" BU_SG_REL_ AF01A SG_ 1292 CAN_TX_TRACK_RANGE 60;
BA_REL_ "GenSigTimeoutTime" BU_SG_REL_ AF01A SG_ 1292 CAN_TX_TRACK_ONCOMING 60;
BA_REL_ "GenSigTimeoutTime" BU_SG_REL_ AF01A SG_ 1292 CAN_TX_TRACK_MED_RANGE_MODE 60;
BA_REL_ "GenSigTimeoutTime" BU_SG_REL_ AF01A SG_ 1292 CAN_TX_TRACK_LAT_RATE 60;
BA_REL_ "GenSigTimeoutTime" BU_SG_REL_ AF01A SG_ 1292 CAN_TX_TRACK_GROUPING_CHANGED 60;
BA_REL_ "GenSigTimeoutTime" BU_SG_REL_ AF01A SG_ 1292 CAN_TX_TRACK_BRIDGE_OBJECT 60;
BA_REL_ "GenSigTimeoutTime" BU_SG_REL_ AF01A SG_ 1292 CAN_TX_TRACK_ANGLE 60;
BA_REL_ "GenSigTimeoutTime" BU_SG_REL_ AF01A SG_ 1291 CAN_TX_TRACK_WIDTH 60;
BA_REL_ "GenSigTimeoutTime" BU_SG_REL_ AF01A SG_ 1291 CAN_TX_TRACK_STATUS 60;
BA_REL_ "GenSigTimeoutTime" BU_SG_REL_ AF01A SG_ 1291 CAN_TX_TRACK_ROLLING_COUNT 60;
BA_REL_ "GenSigTimeoutTime" BU_SG_REL_ AF01A SG_ 1291 CAN_TX_TRACK_RANGE_RATE 60;
BA_REL_ "GenSigTimeoutTime" BU_SG_REL_ AF01A SG_ 1291 CAN_TX_TRACK_RANGE_ACCEL 60;
BA_REL_ "GenSigTimeoutTime" BU_SG_REL_ AF01A SG_ 1291 CAN_TX_TRACK_RANGE 60;
BA_REL_ "GenSigTimeoutTime" BU_SG_REL_ AF01A SG_ 1291 CAN_TX_TRACK_ONCOMING 60;
BA_REL_ "GenSigTimeoutTime" BU_SG_REL_ AF01A SG_ 1291 CAN_TX_TRACK_MED_RANGE_MODE 60;
BA_REL_ "GenSigTimeoutTime" BU_SG_REL_ AF01A SG_ 1291 CAN_TX_TRACK_LAT_RATE 60;
BA_REL_ "GenSigTimeoutTime" BU_SG_REL_ AF01A SG_ 1291 CAN_TX_TRACK_GROUPING_CHANGED 60;
BA_REL_ "GenSigTimeoutTime" BU_SG_REL_ AF01A SG_ 1291 CAN_TX_TRACK_BRIDGE_OBJECT 60;
BA_REL_ "GenSigTimeoutTime" BU_SG_REL_ AF01A SG_ 1291 CAN_TX_TRACK_ANGLE 60;
BA_REL_ "GenSigTimeoutTime" BU_SG_REL_ AF01A SG_ 1290 CAN_TX_TRACK_WIDTH 60;
BA_REL_ "GenSigTimeoutTime" BU_SG_REL_ AF01A SG_ 1290 CAN_TX_TRACK_STATUS 60;
BA_REL_ "GenSigTimeoutTime" BU_SG_REL_ AF01A SG_ 1290 CAN_TX_TRACK_ROLLING_COUNT 60;
BA_REL_ "GenSigTimeoutTime" BU_SG_REL_ AF01A SG_ 1290 CAN_TX_TRACK_RANGE_RATE 60;
BA_REL_ "GenSigTimeoutTime" BU_SG_REL_ AF01A SG_ 1290 CAN_TX_TRACK_RANGE_ACCEL 60;
BA_REL_ "GenSigTimeoutTime" BU_SG_REL_ AF01A SG_ 1290 CAN_TX_TRACK_RANGE 60;
BA_REL_ "GenSigTimeoutTime" BU_SG_REL_ AF01A SG_ 1290 CAN_TX_TRACK_ONCOMING 60;
BA_REL_ "GenSigTimeoutTime" BU_SG_REL_ AF01A SG_ 1290 CAN_TX_TRACK_MED_RANGE_MODE 60;
BA_REL_ "GenSigTimeoutTime" BU_SG_REL_ AF01A SG_ 1290 CAN_TX_TRACK_LAT_RATE 60;
BA_REL_ "GenSigTimeoutTime" BU_SG_REL_ AF01A SG_ 1290 CAN_TX_TRACK_GROUPING_CHANGED 60;
BA_REL_ "GenSigTimeoutTime" BU_SG_REL_ AF01A SG_ 1290 CAN_TX_TRACK_BRIDGE_OBJECT 60;
BA_REL_ "GenSigTimeoutTime" BU_SG_REL_ AF01A SG_ 1290 CAN_TX_TRACK_ANGLE 60;
BA_REL_ "GenSigTimeoutTime" BU_SG_REL_ AF01A SG_ 1289 CAN_TX_TRACK_WIDTH 60;
BA_REL_ "GenSigTimeoutTime" BU_SG_REL_ AF01A SG_ 1289 CAN_TX_TRACK_STATUS 60;
BA_REL_ "GenSigTimeoutTime" BU_SG_REL_ AF01A SG_ 1289 CAN_TX_TRACK_ROLLING_COUNT 60;
BA_REL_ "GenSigTimeoutTime" BU_SG_REL_ AF01A SG_ 1289 CAN_TX_TRACK_RANGE_RATE 60;
BA_REL_ "GenSigTimeoutTime" BU_SG_REL_ AF01A SG_ 1289 CAN_TX_TRACK_RANGE_ACCEL 60;
BA_REL_ "GenSigTimeoutTime" BU_SG_REL_ AF01A SG_ 1289 CAN_TX_TRACK_RANGE 60;
BA_REL_ "GenSigTimeoutTime" BU_SG_REL_ AF01A SG_ 1289 CAN_TX_TRACK_ONCOMING 60;
BA_REL_ "GenSigTimeoutTime" BU_SG_REL_ AF01A SG_ 1289 CAN_TX_TRACK_MED_RANGE_MODE 60;
BA_REL_ "GenSigTimeoutTime" BU_SG_REL_ AF01A SG_ 1289 CAN_TX_TRACK_LAT_RATE 60;
BA_REL_ "GenSigTimeoutTime" BU_SG_REL_ AF01A SG_ 1289 CAN_TX_TRACK_GROUPING_CHANGED 60;
BA_REL_ "GenSigTimeoutTime" BU_SG_REL_ AF01A SG_ 1289 CAN_TX_TRACK_BRIDGE_OBJECT 60;
BA_REL_ "GenSigTimeoutTime" BU_SG_REL_ AF01A SG_ 1289 CAN_TX_TRACK_ANGLE 60;
BA_REL_ "GenSigTimeoutTime" BU_SG_REL_ AF01A SG_ 1288 CAN_TX_TRACK_WIDTH 60;
BA_REL_ "GenSigTimeoutTime" BU_SG_REL_ AF01A SG_ 1288 CAN_TX_TRACK_STATUS 60;
BA_REL_ "GenSigTimeoutTime" BU_SG_REL_ AF01A SG_ 1288 CAN_TX_TRACK_ROLLING_COUNT 60;
BA_REL_ "GenSigTimeoutTime" BU_SG_REL_ AF01A SG_ 1288 CAN_TX_TRACK_RANGE_RATE 60;
BA_REL_ "GenSigTimeoutTime" BU_SG_REL_ AF01A SG_ 1288 CAN_TX_TRACK_RANGE_ACCEL 60;
BA_REL_ "GenSigTimeoutTime" BU_SG_REL_ AF01A SG_ 1288 CAN_TX_TRACK_RANGE 60;
BA_REL_ "GenSigTimeoutTime" BU_SG_REL_ AF01A SG_ 1288 CAN_TX_TRACK_ONCOMING 60;
BA_REL_ "GenSigTimeoutTime" BU_SG_REL_ AF01A SG_ 1288 CAN_TX_TRACK_MED_RANGE_MODE 60;
BA_REL_ "GenSigTimeoutTime" BU_SG_REL_ AF01A SG_ 1288 CAN_TX_TRACK_LAT_RATE 60;
BA_REL_ "GenSigTimeoutTime" BU_SG_REL_ AF01A SG_ 1288 CAN_TX_TRACK_GROUPING_CHANGED 60;
BA_REL_ "GenSigTimeoutTime" BU_SG_REL_ AF01A SG_ 1288 CAN_TX_TRACK_BRIDGE_OBJECT 60;
BA_REL_ "GenSigTimeoutTime" BU_SG_REL_ AF01A SG_ 1288 CAN_TX_TRACK_ANGLE 60;
BA_REL_ "GenSigTimeoutTime" BU_SG_REL_ AF01A SG_ 1287 CAN_TX_TRACK_WIDTH 60;
BA_REL_ "GenSigTimeoutTime" BU_SG_REL_ AF01A SG_ 1287 CAN_TX_TRACK_STATUS 60;
BA_REL_ "GenSigTimeoutTime" BU_SG_REL_ AF01A SG_ 1287 CAN_TX_TRACK_ROLLING_COUNT 60;
BA_REL_ "GenSigTimeoutTime" BU_SG_REL_ AF01A SG_ 1287 CAN_TX_TRACK_RANGE_RATE 60;
BA_REL_ "GenSigTimeoutTime" BU_SG_REL_ AF01A SG_ 1287 CAN_TX_TRACK_RANGE_ACCEL 60;
BA_REL_ "GenSigTimeoutTime" BU_SG_REL_ AF01A SG_ 1287 CAN_TX_TRACK_RANGE 60;
BA_REL_ "GenSigTimeoutTime" BU_SG_REL_ AF01A SG_ 1287 CAN_TX_TRACK_ONCOMING 60;
BA_REL_ "GenSigTimeoutTime" BU_SG_REL_ AF01A SG_ 1287 CAN_TX_TRACK_MED_RANGE_MODE 60;
BA_REL_ "GenSigTimeoutTime" BU_SG_REL_ AF01A SG_ 1287 CAN_TX_TRACK_LAT_RATE 60;
BA_REL_ "GenSigTimeoutTime" BU_SG_REL_ AF01A SG_ 1287 CAN_TX_TRACK_GROUPING_CHANGED 60;
BA_REL_ "GenSigTimeoutTime" BU_SG_REL_ AF01A SG_ 1287 CAN_TX_TRACK_BRIDGE_OBJECT 60;
BA_REL_ "GenSigTimeoutTime" BU_SG_REL_ AF01A SG_ 1287 CAN_TX_TRACK_ANGLE 60;
BA_REL_ "GenSigTimeoutTime" BU_SG_REL_ AF01A SG_ 1286 CAN_TX_TRACK_WIDTH 60;
BA_REL_ "GenSigTimeoutTime" BU_SG_REL_ AF01A SG_ 1286 CAN_TX_TRACK_STATUS 60;
BA_REL_ "GenSigTimeoutTime" BU_SG_REL_ AF01A SG_ 1286 CAN_TX_TRACK_ROLLING_COUNT 60;
BA_REL_ "GenSigTimeoutTime" BU_SG_REL_ AF01A SG_ 1286 CAN_TX_TRACK_RANGE_RATE 60;
BA_REL_ "GenSigTimeoutTime" BU_SG_REL_ AF01A SG_ 1286 CAN_TX_TRACK_RANGE_ACCEL 60;
BA_REL_ "GenSigTimeoutTime" BU_SG_REL_ AF01A SG_ 1286 CAN_TX_TRACK_RANGE 60;
BA_REL_ "GenSigTimeoutTime" BU_SG_REL_ AF01A SG_ 1286 CAN_TX_TRACK_ONCOMING 60;
BA_REL_ "GenSigTimeoutTime" BU_SG_REL_ AF01A SG_ 1286 CAN_TX_TRACK_MED_RANGE_MODE 60;
BA_REL_ "GenSigTimeoutTime" BU_SG_REL_ AF01A SG_ 1286 CAN_TX_TRACK_LAT_RATE 60;
BA_REL_ "GenSigTimeoutTime" BU_SG_REL_ AF01A SG_ 1286 CAN_TX_TRACK_GROUPING_CHANGED 60;
BA_REL_ "GenSigTimeoutTime" BU_SG_REL_ AF01A SG_ 1286 CAN_TX_TRACK_BRIDGE_OBJECT 60;
BA_REL_ "GenSigTimeoutTime" BU_SG_REL_ AF01A SG_ 1286 CAN_TX_TRACK_ANGLE 60;
BA_REL_ "GenSigTimeoutTime" BU_SG_REL_ AF01A SG_ 1285 CAN_TX_TRACK_WIDTH 60;
BA_REL_ "GenSigTimeoutTime" BU_SG_REL_ AF01A SG_ 1285 CAN_TX_TRACK_STATUS 60;
BA_REL_ "GenSigTimeoutTime" BU_SG_REL_ AF01A SG_ 1285 CAN_TX_TRACK_ROLLING_COUNT 60;
BA_REL_ "GenSigTimeoutTime" BU_SG_REL_ AF01A SG_ 1285 CAN_TX_TRACK_RANGE_RATE 60;
BA_REL_ "GenSigTimeoutTime" BU_SG_REL_ AF01A SG_ 1285 CAN_TX_TRACK_RANGE_ACCEL 60;
BA_REL_ "GenSigTimeoutTime" BU_SG_REL_ AF01A SG_ 1285 CAN_TX_TRACK_RANGE 60;
BA_REL_ "GenSigTimeoutTime" BU_SG_REL_ AF01A SG_ 1285 CAN_TX_TRACK_ONCOMING 60;
BA_REL_ "GenSigTimeoutTime" BU_SG_REL_ AF01A SG_ 1285 CAN_TX_TRACK_MED_RANGE_MODE 60;
BA_REL_ "GenSigTimeoutTime" BU_SG_REL_ AF01A SG_ 1285 CAN_TX_TRACK_LAT_RATE 60;
BA_REL_ "GenSigTimeoutTime" BU_SG_REL_ AF01A SG_ 1285 CAN_TX_TRACK_GROUPING_CHANGED 60;
BA_REL_ "GenSigTimeoutTime" BU_SG_REL_ AF01A SG_ 1285 CAN_TX_TRACK_BRIDGE_OBJECT 60;
BA_REL_ "GenSigTimeoutTime" BU_SG_REL_ AF01A SG_ 1285 CAN_TX_TRACK_ANGLE 60;
BA_REL_ "GenSigTimeoutTime" BU_SG_REL_ AF01A SG_ 1284 CAN_TX_TRACK_WIDTH 60;
BA_REL_ "GenSigTimeoutTime" BU_SG_REL_ AF01A SG_ 1284 CAN_TX_TRACK_STATUS 60;
BA_REL_ "GenSigTimeoutTime" BU_SG_REL_ AF01A SG_ 1284 CAN_TX_TRACK_ROLLING_COUNT 60;
BA_REL_ "GenSigTimeoutTime" BU_SG_REL_ AF01A SG_ 1284 CAN_TX_TRACK_RANGE_RATE 60;
BA_REL_ "GenSigTimeoutTime" BU_SG_REL_ AF01A SG_ 1284 CAN_TX_TRACK_RANGE_ACCEL 60;
BA_REL_ "GenSigTimeoutTime" BU_SG_REL_ AF01A SG_ 1284 CAN_TX_TRACK_RANGE 60;
BA_REL_ "GenSigTimeoutTime" BU_SG_REL_ AF01A SG_ 1284 CAN_TX_TRACK_ONCOMING 60;
BA_REL_ "GenSigTimeoutTime" BU_SG_REL_ AF01A SG_ 1284 CAN_TX_TRACK_MED_RANGE_MODE 60;
BA_REL_ "GenSigTimeoutTime" BU_SG_REL_ AF01A SG_ 1284 CAN_TX_TRACK_LAT_RATE 60;
BA_REL_ "GenSigTimeoutTime" BU_SG_REL_ AF01A SG_ 1284 CAN_TX_TRACK_GROUPING_CHANGED 60;
BA_REL_ "GenSigTimeoutTime" BU_SG_REL_ AF01A SG_ 1284 CAN_TX_TRACK_BRIDGE_OBJECT 60;
BA_REL_ "GenSigTimeoutTime" BU_SG_REL_ AF01A SG_ 1284 CAN_TX_TRACK_ANGLE 60;
BA_REL_ "GenSigTimeoutTime" BU_SG_REL_ AF01A SG_ 1283 CAN_TX_TRACK_WIDTH 60;
BA_REL_ "GenSigTimeoutTime" BU_SG_REL_ AF01A SG_ 1283 CAN_TX_TRACK_STATUS 60;
BA_REL_ "GenSigTimeoutTime" BU_SG_REL_ AF01A SG_ 1283 CAN_TX_TRACK_ROLLING_COUNT 60;
BA_REL_ "GenSigTimeoutTime" BU_SG_REL_ AF01A SG_ 1283 CAN_TX_TRACK_RANGE_RATE 60;
BA_REL_ "GenSigTimeoutTime" BU_SG_REL_ AF01A SG_ 1283 CAN_TX_TRACK_RANGE_ACCEL 60;
BA_REL_ "GenSigTimeoutTime" BU_SG_REL_ AF01A SG_ 1283 CAN_TX_TRACK_RANGE 60;
BA_REL_ "GenSigTimeoutTime" BU_SG_REL_ AF01A SG_ 1283 CAN_TX_TRACK_ONCOMING 60;
BA_REL_ "GenSigTimeoutTime" BU_SG_REL_ AF01A SG_ 1283 CAN_TX_TRACK_MED_RANGE_MODE 60;
BA_REL_ "GenSigTimeoutTime" BU_SG_REL_ AF01A SG_ 1283 CAN_TX_TRACK_LAT_RATE 60;
BA_REL_ "GenSigTimeoutTime" BU_SG_REL_ AF01A SG_ 1283 CAN_TX_TRACK_GROUPING_CHANGED 60;
BA_REL_ "GenSigTimeoutTime" BU_SG_REL_ AF01A SG_ 1283 CAN_TX_TRACK_BRIDGE_OBJECT 60;
BA_REL_ "GenSigTimeoutTime" BU_SG_REL_ AF01A SG_ 1283 CAN_TX_TRACK_ANGLE 60;
BA_REL_ "GenSigTimeoutTime" BU_SG_REL_ AF01A SG_ 1282 CAN_TX_TRACK_WIDTH 60;
BA_REL_ "GenSigTimeoutTime" BU_SG_REL_ AF01A SG_ 1282 CAN_TX_TRACK_STATUS 60;
BA_REL_ "GenSigTimeoutTime" BU_SG_REL_ AF01A SG_ 1282 CAN_TX_TRACK_ROLLING_COUNT 60;
BA_REL_ "GenSigTimeoutTime" BU_SG_REL_ AF01A SG_ 1282 CAN_TX_TRACK_RANGE_RATE 60;
BA_REL_ "GenSigTimeoutTime" BU_SG_REL_ AF01A SG_ 1282 CAN_TX_TRACK_RANGE_ACCEL 60;
BA_REL_ "GenSigTimeoutTime" BU_SG_REL_ AF01A SG_ 1282 CAN_TX_TRACK_RANGE 60;
BA_REL_ "GenSigTimeoutTime" BU_SG_REL_ AF01A SG_ 1282 CAN_TX_TRACK_ONCOMING 60;
BA_REL_ "GenSigTimeoutTime" BU_SG_REL_ AF01A SG_ 1282 CAN_TX_TRACK_MED_RANGE_MODE 60;
BA_REL_ "GenSigTimeoutTime" BU_SG_REL_ AF01A SG_ 1282 CAN_TX_TRACK_LAT_RATE 60;
BA_REL_ "GenSigTimeoutTime" BU_SG_REL_ AF01A SG_ 1282 CAN_TX_TRACK_GROUPING_CHANGED 60;
BA_REL_ "GenSigTimeoutTime" BU_SG_REL_ AF01A SG_ 1282 CAN_TX_TRACK_BRIDGE_OBJECT 60;
BA_REL_ "GenSigTimeoutTime" BU_SG_REL_ AF01A SG_ 1282 CAN_TX_TRACK_ANGLE 60;
BA_REL_ "GenSigTimeoutTime" BU_SG_REL_ AF01A SG_ 1281 CAN_TX_TRACK_WIDTH 60;
BA_REL_ "GenSigTimeoutTime" BU_SG_REL_ AF01A SG_ 1281 CAN_TX_TRACK_STATUS 60;
BA_REL_ "GenSigTimeoutTime" BU_SG_REL_ AF01A SG_ 1281 CAN_TX_TRACK_ROLLING_COUNT 60;
BA_REL_ "GenSigTimeoutTime" BU_SG_REL_ AF01A SG_ 1281 CAN_TX_TRACK_RANGE_RATE 60;
BA_REL_ "GenSigTimeoutTime" BU_SG_REL_ AF01A SG_ 1281 CAN_TX_TRACK_RANGE_ACCEL 60;
BA_REL_ "GenSigTimeoutTime" BU_SG_REL_ AF01A SG_ 1281 CAN_TX_TRACK_RANGE 60;
BA_REL_ "GenSigTimeoutTime" BU_SG_REL_ AF01A SG_ 1281 CAN_TX_TRACK_ONCOMING 60;
BA_REL_ "GenSigTimeoutTime" BU_SG_REL_ AF01A SG_ 1281 CAN_TX_TRACK_MED_RANGE_MODE 60;
BA_REL_ "GenSigTimeoutTime" BU_SG_REL_ AF01A SG_ 1281 CAN_TX_TRACK_LAT_RATE 60;
BA_REL_ "GenSigTimeoutTime" BU_SG_REL_ AF01A SG_ 1281 CAN_TX_TRACK_GROUPING_CHANGED 60;
BA_REL_ "GenSigTimeoutTime" BU_SG_REL_ AF01A SG_ 1281 CAN_TX_TRACK_BRIDGE_OBJECT 60;
BA_REL_ "GenSigTimeoutTime" BU_SG_REL_ AF01A SG_ 1281 CAN_TX_TRACK_ANGLE 60;
BA_REL_ "GenSigTimeoutTime" BU_SG_REL_ AF01A SG_ 1280 CAN_TX_TRACK_WIDTH 60;
BA_REL_ "GenSigTimeoutTime" BU_SG_REL_ AF01A SG_ 1280 CAN_TX_TRACK_STATUS 60;
BA_REL_ "GenSigTimeoutTime" BU_SG_REL_ AF01A SG_ 1280 CAN_TX_TRACK_ROLLING_COUNT 60;
BA_REL_ "GenSigTimeoutTime" BU_SG_REL_ AF01A SG_ 1280 CAN_TX_TRACK_RANGE_RATE 60;
BA_REL_ "GenSigTimeoutTime" BU_SG_REL_ AF01A SG_ 1280 CAN_TX_TRACK_RANGE_ACCEL 60;
BA_REL_ "GenSigTimeoutTime" BU_SG_REL_ AF01A SG_ 1280 CAN_TX_TRACK_RANGE 60;
BA_REL_ "GenSigTimeoutTime" BU_SG_REL_ AF01A SG_ 1280 CAN_TX_TRACK_ONCOMING 60;
BA_REL_ "GenSigTimeoutTime" BU_SG_REL_ AF01A SG_ 1280 CAN_TX_TRACK_MED_RANGE_MODE 60;
BA_REL_ "GenSigTimeoutTime" BU_SG_REL_ AF01A SG_ 1280 CAN_TX_TRACK_LAT_RATE 60;
BA_REL_ "GenSigTimeoutTime" BU_SG_REL_ AF01A SG_ 1280 CAN_TX_TRACK_GROUPING_CHANGED 60;
BA_REL_ "GenSigTimeoutTime" BU_SG_REL_ AF01A SG_ 1280 CAN_TX_TRACK_BRIDGE_OBJECT 60;
BA_REL_ "GenSigTimeoutTime" BU_SG_REL_ AF01A SG_ 1280 CAN_TX_TRACK_ANGLE 60;
BA_REL_ "GenSigTimeoutTime" BU_SG_REL_ AF01A SG_ 1251 CAN_TX_TRUCK_TARGET_DET 60;
BA_REL_ "GenSigTimeoutTime" BU_SG_REL_ AF01A SG_ 1251 CAN_TX_SIDELOBE_BLOCKAGE 60;
BA_REL_ "GenSigTimeoutTime" BU_SG_REL_ AF01A SG_ 1251 CAN_TX_ROLLING_COUNT_3 60;
BA_REL_ "GenSigTimeoutTime" BU_SG_REL_ AF01A SG_ 1251 CAN_TX_PATH_ID_FCW_STAT 60;
BA_REL_ "GenSigTimeoutTime" BU_SG_REL_ AF01A SG_ 1251 CAN_TX_PATH_ID_FCW_MOVE 60;
BA_REL_ "GenSigTimeoutTime" BU_SG_REL_ AF01A SG_ 1251 CAN_TX_PATH_ID_CMBB_STAT 60;
BA_REL_ "GenSigTimeoutTime" BU_SG_REL_ AF01A SG_ 1251 CAN_TX_PATH_ID_CMBB_MOVE 60;
BA_REL_ "GenSigTimeoutTime" BU_SG_REL_ AF01A SG_ 1251 CAN_TX_PATH_ID_ACC_STAT 60;
BA_REL_ "GenSigTimeoutTime" BU_SG_REL_ AF01A SG_ 1251 CAN_TX_PATH_ID_ACC 60;
BA_REL_ "GenSigTimeoutTime" BU_SG_REL_ AF01A SG_ 1251 CAN_TX_PARTIAL_BLOCKAGE 60;
BA_REL_ "GenSigTimeoutTime" BU_SG_REL_ AF01A SG_ 1251 CAN_TX_MR_LR_MODE 60;
BA_REL_ "GenSigTimeoutTime" BU_SG_REL_ AF01A SG_ 1251 CAN_TX_LR_ONLY_GRATING_LOBE_DET 60;
BA_REL_ "GenSigTimeoutTime" BU_SG_REL_ AF01A SG_ 1251 CAN_TX_AUTO_ALIGN_ANGLE 60;
BA_REL_ "GenSigTimeoutTime" BU_SG_REL_ AF01A SG_ 1250 CAN_TX_SW_VERSION_PLD 60;
BA_REL_ "GenSigTimeoutTime" BU_SG_REL_ AF01A SG_ 1250 CAN_TX_SW_VERSION_HOST 60;
BA_REL_ "GenSigTimeoutTime" BU_SG_REL_ AF01A SG_ 1250 CAN_TX_SERIAL_NUM 60;
BA_REL_ "GenSigTimeoutTime" BU_SG_REL_ AF01A SG_ 1250 CAN_TX_INTERFACE_VERSION 60;
BA_REL_ "GenSigTimeoutTime" BU_SG_REL_ AF01A SG_ 1250 CAN_TX_HW_VERSION 60;
BA_REL_ "GenSigTimeoutTime" BU_SG_REL_ AF01A SG_ 1249 CAN_TX_ROLLING_COUNT_2 60;
BA_REL_ "GenSigTimeoutTime" BU_SG_REL_ AF01A SG_ 1249 CAN_TX_MAXIMUM_TRACKS_ACK 60;
BA_REL_ "GenSigTimeoutTime" BU_SG_REL_ AF01A SG_ 1249 CAN_TX_RAW_DATA_MODE 60;
BA_REL_ "GenSigTimeoutTime" BU_SG_REL_ AF01A SG_ 1249 CAN_TX_XCVR_OPERATIONAL 60;
BA_REL_ "GenSigTimeoutTime" BU_SG_REL_ AF01A SG_ 1249 CAN_TX_INTERNAL_ERROR 60;
BA_REL_ "GenSigTimeoutTime" BU_SG_REL_ AF01A SG_ 1249 CAN_TX_RANGE_PERF_ERROR 60;
BA_REL_ "GenSigTimeoutTime" BU_SG_REL_ AF01A SG_ 1249 CAN_TX_OVERHEAT_ERROR 60;
BA_REL_ "GenSigTimeoutTime" BU_SG_REL_ AF01A SG_ 1249 CAN_TX_STEERING_ANGLE_ACK 60;
BA_REL_ "GenSigTimeoutTime" BU_SG_REL_ AF01A SG_ 1249 CAN_TX_TEMPERATURE 60;
BA_REL_ "GenSigTimeoutTime" BU_SG_REL_ AF01A SG_ 1249 CAN_TX_GROUPING_MODE 60;
BA_REL_ "GenSigTimeoutTime" BU_SG_REL_ AF01A SG_ 1249 CAN_TX_VEH_SPD_COMP_FACTOR 60;
BA_REL_ "GenSigTimeoutTime" BU_SG_REL_ AF01A SG_ 1249 CAN_TX_YAW_RATE_BIAS 60;
BA_REL_ "GenSigTimeoutTime" BU_SG_REL_ AF01A SG_ 1249 CAN_TX_SW_VERSION_DSP 60;
BA_REL_ "GenSigTimeoutTime" BU_SG_REL_ AF01A SG_ 1248 CAN_TX_VEHICLE_SPEED_CALC 60;
BA_REL_ "GenSigTimeoutTime" BU_SG_REL_ AF01A SG_ 1248 CAN_TX_YAW_RATE_CALC 60;
BA_REL_ "GenSigTimeoutTime" BU_SG_REL_ AF01A SG_ 1248 CAN_TX_SCAN_INDEX 60;
BA_REL_ "GenSigTimeoutTime" BU_SG_REL_ AF01A SG_ 1248 CAN_TX_RADIUS_CURVATURE_CALC 60;
BA_REL_ "GenSigTimeoutTime" BU_SG_REL_ AF01A SG_ 1248 CAN_TX_DSP_TIMESTAMP 60;
BA_REL_ "GenSigTimeoutTime" BU_SG_REL_ AF01A SG_ 1248 CAN_TX_COMM_ERROR 60;
BA_REL_ "GenSigTimeoutTime" BU_SG_REL_ AF01A SG_ 1248 CAN_TX_ROLLING_COUNT_1 60;
VAL_ 1306 CAN_TX_TRACK_STATUS 7 "New_Coasted_Target" 6 "Invalid_Coasted_Target" 5 "Merged_Target" 4 "Coasted_Target" 3 "Updated_Target" 2 "New_Updated_Target" 1 "New_Target" 0 "No_Target" ;
VAL_ 1306 CAN_TX_TRACK_ONCOMING 1 "Oncoming" 0 "NotOncoming" ;
VAL_ 1306 CAN_TX_TRACK_MED_RANGE_MODE 3 "Both_MR_LR_Update" 2 "LR_Update_Only" 1 "MR_Update_Only" 0 "No_MR_LR_Update" ;
VAL_ 1306 CAN_TX_TRACK_GROUPING_CHANGED 1 "GroupingChanged" 0 "GroupingUnchanged" ;
VAL_ 1306 CAN_TX_TRACK_BRIDGE_OBJECT 1 "Bridge" 0 "Not_Bridge" ;
VAL_ 1305 CAN_TX_TRACK_STATUS 7 "New_Coasted_Target" 6 "Invalid_Coasted_Target" 5 "Merged_Target" 4 "Coasted_Target" 3 "Updated_Target" 2 "New_Updated_Target" 1 "New_Target" 0 "No_Target" ;
VAL_ 1305 CAN_TX_TRACK_ONCOMING 1 "Oncoming" 0 "NotOncoming" ;
VAL_ 1305 CAN_TX_TRACK_MED_RANGE_MODE 3 "Both_MR_LR_Update" 2 "LR_Update_Only" 1 "MR_Update_Only" 0 "No_MR_LR_Update" ;
VAL_ 1305 CAN_TX_TRACK_GROUPING_CHANGED 1 "GroupingChanged" 0 "GroupingUnchanged" ;
VAL_ 1305 CAN_TX_TRACK_BRIDGE_OBJECT 1 "Bridge" 0 "Not_Bridge" ;
VAL_ 1304 CAN_TX_TRACK_STATUS 7 "New_Coasted_Target" 6 "Invalid_Coasted_Target" 5 "Merged_Target" 4 "Coasted_Target" 3 "Updated_Target" 2 "New_Updated_Target" 1 "New_Target" 0 "No_Target" ;
VAL_ 1304 CAN_TX_TRACK_ONCOMING 1 "Oncoming" 0 "NotOncoming" ;
VAL_ 1304 CAN_TX_TRACK_MED_RANGE_MODE 3 "Both_MR_LR_Update" 2 "LR_Update_Only" 1 "MR_Update_Only" 0 "No_MR_LR_Update" ;
VAL_ 1304 CAN_TX_TRACK_GROUPING_CHANGED 1 "GroupingChanged" 0 "GroupingUnchanged" ;
VAL_ 1304 CAN_TX_TRACK_BRIDGE_OBJECT 1 "Bridge" 0 "Not_Bridge" ;
VAL_ 1303 CAN_TX_TRACK_STATUS 7 "New_Coasted_Target" 6 "Invalid_Coasted_Target" 5 "Merged_Target" 4 "Coasted_Target" 3 "Updated_Target" 2 "New_Updated_Target" 1 "New_Target" 0 "No_Target" ;
VAL_ 1303 CAN_TX_TRACK_ONCOMING 1 "Oncoming" 0 "NotOncoming" ;
VAL_ 1303 CAN_TX_TRACK_MED_RANGE_MODE 3 "Both_MR_LR_Update" 2 "LR_Update_Only" 1 "MR_Update_Only" 0 "No_MR_LR_Update" ;
VAL_ 1303 CAN_TX_TRACK_GROUPING_CHANGED 1 "GroupingChanged" 0 "GroupingUnchanged" ;
VAL_ 1303 CAN_TX_TRACK_BRIDGE_OBJECT 1 "Bridge" 0 "Not_Bridge" ;
VAL_ 1302 CAN_TX_TRACK_STATUS 7 "New_Coasted_Target" 6 "Invalid_Coasted_Target" 5 "Merged_Target" 4 "Coasted_Target" 3 "Updated_Target" 2 "New_Updated_Target" 1 "New_Target" 0 "No_Target" ;
VAL_ 1302 CAN_TX_TRACK_ONCOMING 1 "Oncoming" 0 "NotOncoming" ;
VAL_ 1302 CAN_TX_TRACK_MED_RANGE_MODE 3 "Both_MR_LR_Update" 2 "LR_Update_Only" 1 "MR_Update_Only" 0 "No_MR_LR_Update" ;
VAL_ 1302 CAN_TX_TRACK_GROUPING_CHANGED 1 "GroupingChanged" 0 "GroupingUnchanged" ;
VAL_ 1302 CAN_TX_TRACK_BRIDGE_OBJECT 1 "Bridge" 0 "Not_Bridge" ;
VAL_ 1301 CAN_TX_TRACK_ONCOMING 1 "Oncoming" 0 "NotOncoming" ;
VAL_ 1301 CAN_TX_TRACK_MED_RANGE_MODE 3 "Both_MR_LR_Update" 2 "LR_Update_Only" 1 "MR_Update_Only" 0 "No_MR_LR_Update" ;
VAL_ 1301 CAN_TX_TRACK_GROUPING_CHANGED 1 "GroupingChanged" 0 "GroupingUnchanged" ;
VAL_ 1301 CAN_TX_TRACK_BRIDGE_OBJECT 1 "Bridge" 0 "Not_Bridge" ;
VAL_ 1300 CAN_TX_TRACK_STATUS 7 "New_Coasted_Target" 6 "Invalid_Coasted_Target" 5 "Merged_Target" 4 "Coasted_Target" 3 "Updated_Target" 2 "New_Updated_Target" 1 "New_Target" 0 "No_Target" ;
VAL_ 1300 CAN_TX_TRACK_ONCOMING 1 "Oncoming" 0 "NotOncoming" ;
VAL_ 1300 CAN_TX_TRACK_MED_RANGE_MODE 3 "Both_MR_LR_Update" 2 "LR_Update_Only" 1 "MR_Update_Only" 0 "No_MR_LR_Update" ;
VAL_ 1300 CAN_TX_TRACK_GROUPING_CHANGED 1 "GroupingChanged" 0 "GroupingUnchanged" ;
VAL_ 1300 CAN_TX_TRACK_BRIDGE_OBJECT 1 "Bridge" 0 "Not_Bridge" ;
VAL_ 1299 CAN_TX_TRACK_STATUS 7 "New_Coasted_Target" 6 "Invalid_Coasted_Target" 5 "Merged_Target" 4 "Coasted_Target" 3 "Updated_Target" 2 "New_Updated_Target" 1 "New_Target" 0 "No_Target" ;
VAL_ 1299 CAN_TX_TRACK_ONCOMING 1 "Oncoming" 0 "NotOncoming" ;
VAL_ 1299 CAN_TX_TRACK_MED_RANGE_MODE 3 "Both_MR_LR_Update" 2 "LR_Update_Only" 1 "MR_Update_Only" 0 "No_MR_LR_Update" ;
VAL_ 1299 CAN_TX_TRACK_GROUPING_CHANGED 1 "GroupingChanged" 0 "GroupingUnchanged" ;
VAL_ 1299 CAN_TX_TRACK_BRIDGE_OBJECT 1 "Bridge" 0 "Not_Bridge" ;
VAL_ 1298 CAN_TX_TRACK_STATUS 7 "New_Coasted_Target" 6 "Invalid_Coasted_Target" 5 "Merged_Target" 4 "Coasted_Target" 3 "Updated_Target" 2 "New_Updated_Target" 1 "New_Target" 0 "No_Target" ;
VAL_ 1298 CAN_TX_TRACK_ONCOMING 1 "Oncoming" 0 "NotOncoming" ;
VAL_ 1298 CAN_TX_TRACK_MED_RANGE_MODE 3 "Both_MR_LR_Update" 2 "LR_Update_Only" 1 "MR_Update_Only" 0 "No_MR_LR_Update" ;
VAL_ 1298 CAN_TX_TRACK_GROUPING_CHANGED 1 "GroupingChanged" 0 "GroupingUnchanged" ;
VAL_ 1298 CAN_TX_TRACK_BRIDGE_OBJECT 1 "Bridge" 0 "Not_Bridge" ;
VAL_ 1297 CAN_TX_TRACK_STATUS 7 "New_Coasted_Target" 6 "Invalid_Coasted_Target" 5 "Merged_Target" 4 "Coasted_Target" 3 "Updated_Target" 2 "New_Updated_Target" 1 "New_Target" 0 "No_Target" ;
VAL_ 1297 CAN_TX_TRACK_ONCOMING 1 "Oncoming" 0 "NotOncoming" ;
VAL_ 1297 CAN_TX_TRACK_MED_RANGE_MODE 3 "Both_MR_LR_Update" 2 "LR_Update_Only" 1 "MR_Update_Only" 0 "No_MR_LR_Update" ;
VAL_ 1297 CAN_TX_TRACK_GROUPING_CHANGED 1 "GroupingChanged" 0 "GroupingUnchanged" ;
VAL_ 1297 CAN_TX_TRACK_BRIDGE_OBJECT 1 "Bridge" 0 "Not_Bridge" ;
VAL_ 1296 CAN_TX_TRACK_STATUS 7 "New_Coasted_Target" 6 "Invalid_Coasted_Target" 5 "Merged_Target" 4 "Coasted_Target" 3 "Updated_Target" 2 "New_Updated_Target" 1 "New_Target" 0 "No_Target" ;
VAL_ 1296 CAN_TX_TRACK_ONCOMING 1 "Oncoming" 0 "NotOncoming" ;
VAL_ 1296 CAN_TX_TRACK_MED_RANGE_MODE 3 "Both_MR_LR_Update" 2 "LR_Update_Only" 1 "MR_Update_Only" 0 "No_MR_LR_Update" ;
VAL_ 1296 CAN_TX_TRACK_GROUPING_CHANGED 1 "GroupingChanged" 0 "GroupingUnchanged" ;
VAL_ 1296 CAN_TX_TRACK_BRIDGE_OBJECT 1 "Bridge" 0 "Not_Bridge" ;
VAL_ 1295 CAN_TX_TRACK_STATUS 7 "New_Coasted_Target" 6 "Invalid_Coasted_Target" 5 "Merged_Target" 4 "Coasted_Target" 3 "Updated_Target" 2 "New_Updated_Target" 1 "New_Target" 0 "No_Target" ;
VAL_ 1295 CAN_TX_TRACK_ONCOMING 1 "Oncoming" 0 "NotOncoming" ;
VAL_ 1295 CAN_TX_TRACK_MED_RANGE_MODE 3 "Both_MR_LR_Update" 2 "LR_Update_Only" 1 "MR_Update_Only" 0 "No_MR_LR_Update" ;
VAL_ 1295 CAN_TX_TRACK_GROUPING_CHANGED 1 "GroupingChanged" 0 "GroupingUnchanged" ;
VAL_ 1295 CAN_TX_TRACK_BRIDGE_OBJECT 1 "Bridge" 0 "Not_Bridge" ;
VAL_ 1294 CAN_TX_TRACK_STATUS 7 "New_Coasted_Target" 6 "Invalid_Coasted_Target" 5 "Merged_Target" 4 "Coasted_Target" 3 "Updated_Target" 2 "New_Updated_Target" 1 "New_Target" 0 "No_Target" ;
VAL_ 1294 CAN_TX_TRACK_ONCOMING 1 "Oncoming" 0 "NotOncoming" ;
VAL_ 1294 CAN_TX_TRACK_MED_RANGE_MODE 3 "Both_MR_LR_Update" 2 "LR_Update_Only" 1 "MR_Update_Only" 0 "No_MR_LR_Update" ;
VAL_ 1294 CAN_TX_TRACK_GROUPING_CHANGED 1 "GroupingChanged" 0 "GroupingUnchanged" ;
VAL_ 1294 CAN_TX_TRACK_BRIDGE_OBJECT 1 "Bridge" 0 "Not_Bridge" ;
VAL_ 1293 CAN_TX_TRACK_STATUS 7 "New_Coasted_Target" 6 "Invalid_Coasted_Target" 5 "Merged_Target" 4 "Coasted_Target" 3 "Updated_Target" 2 "New_Updated_Target" 1 "New_Target" 0 "No_Target" ;
VAL_ 1293 CAN_TX_TRACK_ONCOMING 1 "Oncoming" 0 "NotOncoming" ;
VAL_ 1293 CAN_TX_TRACK_MED_RANGE_MODE 3 "Both_MR_LR_Update" 2 "LR_Update_Only" 1 "MR_Update_Only" 0 "No_MR_LR_Update" ;
VAL_ 1293 CAN_TX_TRACK_GROUPING_CHANGED 1 "GroupingChanged" 0 "GroupingUnchanged" ;
VAL_ 1293 CAN_TX_TRACK_BRIDGE_OBJECT 1 "Bridge" 0 "Not_Bridge" ;
VAL_ 1292 CAN_TX_TRACK_ONCOMING 1 "Oncoming" 0 "NotOncoming" ;
VAL_ 1292 CAN_TX_TRACK_MED_RANGE_MODE 3 "Both_MR_LR_Update" 2 "LR_Update_Only" 1 "MR_Update_Only" 0 "No_MR_LR_Update" ;
VAL_ 1292 CAN_TX_TRACK_GROUPING_CHANGED 1 "GroupingChanged" 0 "GroupingUnchanged" ;
VAL_ 1292 CAN_TX_TRACK_BRIDGE_OBJECT 1 "Bridge" 0 "Not_Bridge" ;
VAL_ 1291 CAN_TX_TRACK_STATUS 7 "New_Coasted_Target" 6 "Invalid_Coasted_Target" 5 "Merged_Target" 4 "Coasted_Target" 3 "Updated_Target" 2 "New_Updated_Target" 1 "New_Target" 0 "No_Target" ;
VAL_ 1291 CAN_TX_TRACK_ONCOMING 1 "Oncoming" 0 "NotOncoming" ;
VAL_ 1291 CAN_TX_TRACK_MED_RANGE_MODE 3 "Both_MR_LR_Update" 2 "LR_Update_Only" 1 "MR_Update_Only" 0 "No_MR_LR_Update" ;
VAL_ 1291 CAN_TX_TRACK_GROUPING_CHANGED 1 "GroupingChanged" 0 "GroupingUnchanged" ;
VAL_ 1291 CAN_TX_TRACK_BRIDGE_OBJECT 1 "Bridge" 0 "Not_Bridge" ;
VAL_ 1290 CAN_TX_TRACK_STATUS 7 "New_Coasted_Target" 6 "Invalid_Coasted_Target" 5 "Merged_Target" 4 "Coasted_Target" 3 "Updated_Target" 2 "New_Updated_Target" 1 "New_Target" 0 "No_Target" ;
VAL_ 1290 CAN_TX_TRACK_ONCOMING 1 "Oncoming" 0 "NotOncoming" ;
VAL_ 1290 CAN_TX_TRACK_MED_RANGE_MODE 3 "Both_MR_LR_Update" 2 "LR_Update_Only" 1 "MR_Update_Only" 0 "No_MR_LR_Update" ;
VAL_ 1290 CAN_TX_TRACK_GROUPING_CHANGED 1 "GroupingChanged" 0 "GroupingUnchanged" ;
VAL_ 1290 CAN_TX_TRACK_BRIDGE_OBJECT 1 "Bridge" 0 "Not_Bridge" ;
VAL_ 1289 CAN_TX_TRACK_STATUS 7 "New_Coasted_Target" 6 "Invalid_Coasted_Target" 5 "Merged_Target" 4 "Coasted_Target" 3 "Updated_Target" 2 "New_Updated_Target" 1 "New_Target" 0 "No_Target" ;
VAL_ 1289 CAN_TX_TRACK_ONCOMING 1 "Oncoming" 0 "NotOncoming" ;
VAL_ 1289 CAN_TX_TRACK_MED_RANGE_MODE 3 "Both_MR_LR_Update" 2 "LR_Update_Only" 1 "MR_Update_Only" 0 "No_MR_LR_Update" ;
VAL_ 1289 CAN_TX_TRACK_GROUPING_CHANGED 1 "GroupingChanged" 0 "GroupingUnchanged" ;
VAL_ 1289 CAN_TX_TRACK_BRIDGE_OBJECT 1 "Bridge" 0 "Not_Bridge" ;
VAL_ 1288 CAN_TX_TRACK_STATUS 7 "New_Coasted_Target" 6 "Invalid_Coasted_Target" 5 "Merged_Target" 4 "Coasted_Target" 3 "Updated_Target" 2 "New_Updated_Target" 1 "New_Target" 0 "No_Target" ;
VAL_ 1288 CAN_TX_TRACK_ONCOMING 1 "Oncoming" 0 "NotOncoming" ;
VAL_ 1288 CAN_TX_TRACK_MED_RANGE_MODE 3 "Both_MR_LR_Update" 2 "LR_Update_Only" 1 "MR_Update_Only" 0 "No_MR_LR_Update" ;
VAL_ 1288 CAN_TX_TRACK_GROUPING_CHANGED 1 "GroupingChanged" 0 "GroupingUnchanged" ;
VAL_ 1288 CAN_TX_TRACK_BRIDGE_OBJECT 1 "Bridge" 0 "Not_Bridge" ;
VAL_ 1287 CAN_TX_TRACK_STATUS 7 "New_Coasted_Target" 6 "Invalid_Coasted_Target" 5 "Merged_Target" 4 "Coasted_Target" 3 "Updated_Target" 2 "New_Updated_Target" 1 "New_Target" 0 "No_Target" ;
VAL_ 1287 CAN_TX_TRACK_ONCOMING 1 "Oncoming" 0 "NotOncoming" ;
VAL_ 1287 CAN_TX_TRACK_MED_RANGE_MODE 3 "Both_MR_LR_Update" 2 "LR_Update_Only" 1 "MR_Update_Only" 0 "No_MR_LR_Update" ;
VAL_ 1287 CAN_TX_TRACK_GROUPING_CHANGED 1 "GroupingChanged" 0 "GroupingUnchanged" ;
VAL_ 1287 CAN_TX_TRACK_BRIDGE_OBJECT 1 "Bridge" 0 "Not_Bridge" ;
VAL_ 1286 CAN_TX_TRACK_STATUS 7 "New_Coasted_Target" 6 "Invalid_Coasted_Target" 5 "Merged_Target" 4 "Coasted_Target" 3 "Updated_Target" 2 "New_Updated_Target" 1 "New_Target" 0 "No_Target" ;
VAL_ 1286 CAN_TX_TRACK_ONCOMING 1 "Oncoming" 0 "NotOncoming" ;
VAL_ 1286 CAN_TX_TRACK_MED_RANGE_MODE 3 "Both_MR_LR_Update" 2 "LR_Update_Only" 1 "MR_Update_Only" 0 "No_MR_LR_Update" ;
VAL_ 1286 CAN_TX_TRACK_GROUPING_CHANGED 1 "GroupingChanged" 0 "GroupingUnchanged" ;
VAL_ 1286 CAN_TX_TRACK_BRIDGE_OBJECT 1 "Bridge" 0 "Not_Bridge" ;
VAL_ 1285 CAN_TX_TRACK_STATUS 7 "New_Coasted_Target" 6 "Invalid_Coasted_Target" 5 "Merged_Target" 4 "Coasted_Target" 3 "Updated_Target" 2 "New_Updated_Target" 1 "New_Target" 0 "No_Target" ;
VAL_ 1285 CAN_TX_TRACK_ONCOMING 1 "Oncoming" 0 "NotOncoming" ;
VAL_ 1285 CAN_TX_TRACK_MED_RANGE_MODE 3 "Both_MR_LR_Update" 2 "LR_Update_Only" 1 "MR_Update_Only" 0 "No_MR_LR_Update" ;
VAL_ 1285 CAN_TX_TRACK_GROUPING_CHANGED 1 "GroupingChanged" 0 "GroupingUnchanged" ;
VAL_ 1285 CAN_TX_TRACK_BRIDGE_OBJECT 1 "Bridge" 0 "Not_Bridge" ;
VAL_ 1284 CAN_TX_TRACK_STATUS 7 "New_Coasted_Target" 6 "Invalid_Coasted_Target" 5 "Merged_Target" 4 "Coasted_Target" 3 "Updated_Target" 2 "New_Updated_Target" 1 "New_Target" 0 "No_Target" ;
VAL_ 1284 CAN_TX_TRACK_ONCOMING 1 "Oncoming" 0 "NotOncoming" ;
VAL_ 1284 CAN_TX_TRACK_MED_RANGE_MODE 3 "Both_MR_LR_Update" 2 "LR_Update_Only" 1 "MR_Update_Only" 0 "No_MR_LR_Update" ;
VAL_ 1284 CAN_TX_TRACK_GROUPING_CHANGED 1 "GroupingChanged" 0 "GroupingUnchanged" ;
VAL_ 1284 CAN_TX_TRACK_BRIDGE_OBJECT 1 "Bridge" 0 "Not_Bridge" ;
VAL_ 1283 CAN_TX_TRACK_STATUS 7 "New_Coasted_Target" 6 "Invalid_Coasted_Target" 5 "Merged_Target" 4 "Coasted_Target" 3 "Updated_Target" 2 "New_Updated_Target" 1 "New_Target" 0 "No_Target" ;
VAL_ 1283 CAN_TX_TRACK_ONCOMING 1 "Oncoming" 0 "NotOncoming" ;
VAL_ 1283 CAN_TX_TRACK_MED_RANGE_MODE 3 "Both_MR_LR_Update" 2 "LR_Update_Only" 1 "MR_Update_Only" 0 "No_MR_LR_Update" ;
VAL_ 1283 CAN_TX_TRACK_GROUPING_CHANGED 1 "GroupingChanged" 0 "GroupingUnchanged" ;
VAL_ 1283 CAN_TX_TRACK_BRIDGE_OBJECT 1 "Bridge" 0 "Not_Bridge" ;
VAL_ 1282 CAN_TX_TRACK_STATUS 7 "New_Coasted_Target" 6 "Invalid_Coasted_Target" 5 "Merged_Target" 4 "Coasted_Target" 3 "Updated_Target" 2 "New_Updated_Target" 1 "New_Target" 0 "No_Target" ;
VAL_ 1282 CAN_TX_TRACK_ONCOMING 1 "Oncoming" 0 "NotOncoming" ;
VAL_ 1282 CAN_TX_TRACK_MED_RANGE_MODE 3 "Both_MR_LR_Update" 2 "LR_Update_Only" 1 "MR_Update_Only" 0 "No_MR_LR_Update" ;
VAL_ 1282 CAN_TX_TRACK_GROUPING_CHANGED 1 "GroupingChanged" 0 "GroupingUnchanged" ;
VAL_ 1282 CAN_TX_TRACK_BRIDGE_OBJECT 1 "Bridge" 0 "Not_Bridge" ;
VAL_ 1281 CAN_TX_TRACK_STATUS 7 "New_Coasted_Target" 6 "Invalid_Coasted_Target" 5 "Merged_Target" 4 "Coasted_Target" 3 "Updated_Target" 2 "New_Updated_Target" 1 "New_Target" 0 "No_Target" ;
VAL_ 1281 CAN_TX_TRACK_ONCOMING 1 "Oncoming" 0 "NotOncoming" ;
VAL_ 1281 CAN_TX_TRACK_MED_RANGE_MODE 3 "Both_MR_LR_Update" 2 "LR_Update_Only" 1 "MR_Update_Only" 0 "No_MR_LR_Update" ;
VAL_ 1281 CAN_TX_TRACK_GROUPING_CHANGED 1 "GroupingChanged" 0 "GroupingUnchanged" ;
VAL_ 1281 CAN_TX_TRACK_BRIDGE_OBJECT 1 "Bridge" 0 "Not_Bridge" ;
VAL_ 1280 CAN_TX_TRACK_STATUS 7 "New_Coasted_Target" 6 "Invalid_Coasted_Target" 5 "Merged_Target" 4 "Coasted_Target" 3 "Updated_Target" 2 "New_Updated_Target" 1 "New_Target" 0 "No_Target" ;
VAL_ 1280 CAN_TX_TRACK_ONCOMING 1 "Oncoming" 0 "NotOncoming" ;
VAL_ 1280 CAN_TX_TRACK_MED_RANGE_MODE 3 "Both_MR_LR_Update" 2 "LR_Update_Only" 1 "MR_Update_Only" 0 "No_MR_LR_Update" ;
VAL_ 1280 CAN_TX_TRACK_GROUPING_CHANGED 1 "GroupingChanged" 0 "GroupingUnchanged" ;
VAL_ 1280 CAN_TX_TRACK_BRIDGE_OBJECT 1 "Bridge" 0 "Not_Bridge" ;
VAL_ 1251 CAN_TX_TRUCK_TARGET_DET 1 "Detected" 0 "Not_Detected" ;
VAL_ 1251 CAN_TX_SIDELOBE_BLOCKAGE 1 "On" 0 "Off" ;
VAL_ 1251 CAN_TX_PARTIAL_BLOCKAGE 1 "Blocked" 0 "Not Blocked" ;
VAL_ 1251 CAN_TX_MR_LR_MODE 3 "Output all medium-range and long" 2 "Output only long-range tracks" 1 "Output only medium-range tracks" 0 "Reserved" ;
VAL_ 1251 CAN_TX_LR_ONLY_GRATING_LOBE_DET 1 "On" 0 "Off" ;
VAL_ 1249 CAN_TX_RAW_DATA_MODE 1 "Raw" 0 "Filtered" ;
VAL_ 1249 CAN_TX_XCVR_OPERATIONAL 1 "On" 0 "Off" ;
VAL_ 1249 CAN_TX_INTERNAL_ERROR 1 "Failed" 0 "Not Failed" ;
VAL_ 1249 CAN_TX_RANGE_PERF_ERROR 1 "Blocked" 0 "Not Blocked" ;
VAL_ 1249 CAN_TX_OVERHEAT_ERROR 1 "OverTemp" 0 "Not OverTemp" ;
VAL_ 1249 CAN_TX_GROUPING_MODE 3 "Group_Moving_Stationary" 2 "Group_Stationary_Only" 1 "Group_Moving_Only" 0 "No_Grouping" ;
VAL_ 1833 Status_Object_Distance_HLB 3 "Invalid signal" 2 "defined by oncoming vehicle" 1 "defined by preceding vehicle" 0 "No object detected" ;
VAL_ 1833 Status_Right_Hand_HLB 3 "Invalid signal" 2 "defined by oncoming vehicle" 1 "defined by preceding vehicle" 0 "No object detected" ;
VAL_ 1833 Status_Left_Hand_HLB 3 "Invalid signal" 2 "defined by oncoming vehicle" 1 "defined by preceding vehicle" 0 "No object detected" ;
VAL_ 1833 Status_Bottom_HLB 3 "Invalid signal" 2 "defined by oncoming vehicle" 1 "defined by preceding vehicle" 0 "No object detected" ;
SIG_VALTYPE_ 1616 Fixed_Horizon : 1;
SIG_VALTYPE_ 1616 Fixed_Yaw : 1;
